VERSION "HNNBNNNYNNNNNNNNNNNNNNNNNNNNNNNNNNNNNNNNNN/4/%%%/4/'%**4NNN///"

NS_ :

BS_:

BU_: BAP_Tester FASFrontradar ICAS1_X_Gateway MFK MFK120 MIK MRR2023 NR_1 NR_2

BO_ 2331595789 NR_FR_Object_09_10: 64 NR_2
 SG_ NR_FR_Object_09_10_CRC : 0|8@1+ (1,0) [0|255] ""  ICAS1_X_Gateway,MRR2023
 SG_ NR_FR_Object_09_10_BZ : 8|4@1+ (1,0) [0|15] ""  ICAS1_X_Gateway,MRR2023
 SG_ NR_FR_Object_09_10_BlockID_02 : 12|4@1+ (1,0) [0|15] "Unit_None"  ICAS1_X_Gateway,MRR2023
 SG_ NR_FR_Object_09_ID : 16|8@1+ (1,0) [1|254] "Unit_None"  ICAS1_X_Gateway,MRR2023
 SG_ NR_FR_Object_09_ReferencePoint : 24|4@1+ (1.0,0.0) [0.0|15] ""  ICAS1_X_Gateway,MRR2023
 SG_ NR_FR_Object_09_PosX : 28|14@1+ (0.03125,-200) [-200.00000|311.93750] "Unit_Meter"  ICAS1_X_Gateway,MRR2023
 SG_ NR_FR_Object_09_PosXSD : 42|8@1+ (0.03125,0) [0.00000|7.93750] "Unit_Meter"  ICAS1_X_Gateway,MRR2023
 SG_ NR_FR_Object_09_PosY : 50|13@1+ (0.03125,-128) [-128.00000|127.93750] "Unit_Meter"  ICAS1_X_Gateway,MRR2023
 SG_ NR_FR_Object_09_PosYSD : 63|8@1+ (0.03125,0) [0.00000|7.93750] "Unit_Meter"  ICAS1_X_Gateway,MRR2023
 SG_ NR_FR_Object_09_vAbsX : 71|12@1+ (0.0625,-128) [-128.0000|127.8750] "Unit_MeterPerSecon"  ICAS1_X_Gateway,MRR2023
 SG_ NR_FR_Object_09_vAbsXSD : 83|6@1+ (0.0625,0) [0.0000|3.8750] "Unit_MeterPerSecon"  ICAS1_X_Gateway,MRR2023
 SG_ NR_FR_Object_09_vAbsY : 89|12@1+ (0.0625,-128) [-128.0000|127.8750] "Unit_MeterPerSecon"  ICAS1_X_Gateway,MRR2023
 SG_ NR_FR_Object_09_vAbsYSD : 101|6@1+ (0.0625,0) [0.0000|3.8750] "Unit_MeterPerSecon"  ICAS1_X_Gateway,MRR2023
 SG_ NR_FR_Object_09_aAbsX : 107|9@1+ (0.0625,-16) [-16.0000|15.8750] "Unit_MeterPerSeconSquar"  ICAS1_X_Gateway,MRR2023
 SG_ NR_FR_Object_09_aAbsXSD : 116|6@1+ (0.0625,0) [0.0000|3.8750] "Unit_MeterPerSeconSquar"  ICAS1_X_Gateway,MRR2023
 SG_ NR_FR_Object_09_aAbsY : 122|9@1+ (0.0625,-16) [-16.0000|15.8750] "Unit_MeterPerSeconSquar"  ICAS1_X_Gateway,MRR2023
 SG_ NR_FR_Object_09_aAbsYSD : 131|6@1+ (0.0625,0) [0.0000|3.8750] "Unit_MeterPerSeconSquar"  ICAS1_X_Gateway,MRR2023
 SG_ NR_FR_Object_09_DynamicState : 137|2@1+ (1.0,0.0) [0.0|3] ""  ICAS1_X_Gateway,MRR2023
 SG_ NR_FR_Object_09_YawAngle : 139|12@1+ (0.001953125,-4) [-4.000000000|3.996093750] "Unit_Radia"  ICAS1_X_Gateway,MRR2023
 SG_ NR_FR_Object_09_YawAngleSD : 151|9@1+ (0.001953125,0) [0E-9|0.996093750] "Unit_Radia"  ICAS1_X_Gateway,MRR2023
 SG_ NR_FR_Object_09_Width : 160|8@1+ (0.03125,0) [0.00000|7.93750] "Unit_Meter"  ICAS1_X_Gateway,MRR2023
 SG_ NR_FR_Object_09_WidthSD : 168|7@1+ (0.03125,0) [0.00000|3.93750] "Unit_Meter"  ICAS1_X_Gateway,MRR2023
 SG_ NR_FR_Object_09_Length : 175|10@1+ (0.03125,0) [0.00000|31.93750] "Unit_Meter"  ICAS1_X_Gateway,MRR2023
 SG_ NR_FR_Object_09_LengthSD : 185|7@1+ (0.03125,0) [0.00000|3.93750] "Unit_Meter"  ICAS1_X_Gateway,MRR2023
 SG_ NR_FR_Object_09_Class : 192|4@1+ (1.0,0.0) [0.0|15] ""  ICAS1_X_Gateway,MRR2023
 SG_ NR_FR_Object_09_ClassPlausib : 196|4@1+ (0.0714285714,0) [0E-10|0.9999999996] "Unit_None"  ICAS1_X_Gateway,MRR2023
 SG_ NR_FR_Object_09_ExistProb : 200|7@1+ (0.0078125,0.015625) [0.0156250|1.0000000] "Unit_None"  ICAS1_X_Gateway,MRR2023
 SG_ NR_FR_Object_09_Age : 207|7@1+ (1,0) [0|126] "Unit_None"  ICAS1_X_Gateway,MRR2023
 SG_ NR_FR_Object_09_YawRateAbs : 214|12@1+ (0.001953125,-4) [-4.000000000|3.996093750] "Unit_RadiaPerSecon"  ICAS1_X_Gateway,MRR2023
 SG_ NR_FR_Object_09_YawRateAbsSD : 226|6@1+ (0.003906,0) [0.000000|0.242172] "Unit_RadiaPerSecon"  ICAS1_X_Gateway,MRR2023
 SG_ NR_FR_Object_09_MeasurementState : 232|1@1+ (1.0,0.0) [0.0|1] ""  ICAS1_X_Gateway,MRR2023
 SG_ NR_FR_Object_10_ID : 233|8@1+ (1,0) [1|254] "Unit_None"  ICAS1_X_Gateway,MRR2023
 SG_ NR_FR_Object_10_ReferencePoint : 241|4@1+ (1.0,0.0) [0.0|15] ""  ICAS1_X_Gateway,MRR2023
 SG_ NR_FR_Object_10_PosX : 245|14@1+ (0.03125,-200) [-200.00000|311.93750] "Unit_Meter"  ICAS1_X_Gateway,MRR2023
 SG_ NR_FR_Object_10_PosXSD : 259|8@1+ (0.03125,0) [0.00000|7.93750] "Unit_Meter"  ICAS1_X_Gateway,MRR2023
 SG_ NR_FR_Object_10_PosY : 267|13@1+ (0.03125,-128) [-128.00000|127.93750] "Unit_Meter"  ICAS1_X_Gateway,MRR2023
 SG_ NR_FR_Object_10_PosYSD : 280|8@1+ (0.03125,0) [0.00000|7.93750] "Unit_Meter"  ICAS1_X_Gateway,MRR2023
 SG_ NR_FR_Object_10_vAbsX : 288|12@1+ (0.0625,-128) [-128.0000|127.8750] "Unit_MeterPerSecon"  ICAS1_X_Gateway,MRR2023
 SG_ NR_FR_Object_10_vAbsXSD : 300|6@1+ (0.0625,0) [0.0000|3.8750] "Unit_MeterPerSecon"  ICAS1_X_Gateway,MRR2023
 SG_ NR_FR_Object_10_vAbsY : 306|12@1+ (0.0625,-128) [-128.0000|127.8750] "Unit_MeterPerSecon"  ICAS1_X_Gateway,MRR2023
 SG_ NR_FR_Object_10_vAbsYSD : 318|6@1+ (0.0625,0) [0.0000|3.8750] "Unit_MeterPerSecon"  ICAS1_X_Gateway,MRR2023
 SG_ NR_FR_Object_10_aAbsX : 324|9@1+ (0.0625,-16) [-16.0000|15.8750] "Unit_MeterPerSeconSquar"  ICAS1_X_Gateway,MRR2023
 SG_ NR_FR_Object_10_aAbsXSD : 333|6@1+ (0.0625,0) [0.0000|3.8750] "Unit_MeterPerSeconSquar"  ICAS1_X_Gateway,MRR2023
 SG_ NR_FR_Object_10_aAbsY : 339|9@1+ (0.0625,-16) [-16.0000|15.8750] "Unit_MeterPerSeconSquar"  ICAS1_X_Gateway,MRR2023
 SG_ NR_FR_Object_10_aAbsYSD : 348|6@1+ (0.0625,0) [0.0000|3.8750] "Unit_MeterPerSeconSquar"  ICAS1_X_Gateway,MRR2023
 SG_ NR_FR_Object_10_DynamicState : 354|2@1+ (1.0,0.0) [0.0|3] ""  ICAS1_X_Gateway,MRR2023
 SG_ NR_FR_Object_10_YawAngle : 356|12@1+ (0.001953125,-4) [-4.000000000|3.996093750] "Unit_Radia"  ICAS1_X_Gateway,MRR2023
 SG_ NR_FR_Object_10_YawAngleSD : 368|9@1+ (0.001953125,0) [0E-9|0.996093750] "Unit_Radia"  ICAS1_X_Gateway,MRR2023
 SG_ NR_FR_Object_10_Width : 377|8@1+ (0.03125,0) [0.00000|7.93750] "Unit_Meter"  ICAS1_X_Gateway,MRR2023
 SG_ NR_FR_Object_10_WidthSD : 385|7@1+ (0.03125,0) [0.00000|3.93750] "Unit_Meter"  ICAS1_X_Gateway,MRR2023
 SG_ NR_FR_Object_10_Length : 392|10@1+ (0.03125,0) [0.00000|31.93750] "Unit_Meter"  ICAS1_X_Gateway,MRR2023
 SG_ NR_FR_Object_10_LengthSD : 402|7@1+ (0.03125,0) [0.00000|3.93750] "Unit_Meter"  ICAS1_X_Gateway,MRR2023
 SG_ NR_FR_Object_10_Class : 409|4@1+ (1.0,0.0) [0.0|15] ""  ICAS1_X_Gateway,MRR2023
 SG_ NR_FR_Object_10_ClassPlausib : 413|4@1+ (0.0714285714,0) [0E-10|0.9999999996] "Unit_None"  ICAS1_X_Gateway,MRR2023
 SG_ NR_FR_Object_10_ExistProb : 417|7@1+ (0.0078125,0.015625) [0.0156250|1.0000000] "Unit_None"  ICAS1_X_Gateway,MRR2023
 SG_ NR_FR_Object_10_Age : 424|7@1+ (1,0) [0|126] "Unit_None"  ICAS1_X_Gateway,MRR2023
 SG_ NR_FR_Object_10_YawRateAbs : 431|12@1+ (0.001953125,-4) [-4.000000000|3.996093750] "Unit_RadiaPerSecon"  ICAS1_X_Gateway,MRR2023
 SG_ NR_FR_Object_10_YawRateAbsSD : 443|6@1+ (0.003906,0) [0.000000|0.242172] "Unit_RadiaPerSecon"  ICAS1_X_Gateway,MRR2023
 SG_ NR_FR_Object_10_MeasurementState : 449|1@1+ (1.0,0.0) [0.0|1] ""  ICAS1_X_Gateway,MRR2023
 SG_ SOK_NR_FR_Object_09_10_Signatur : 480|32@1+ (1,0) [0|4294967295] ""  ICAS1_X_Gateway

BO_ 2589284097 NR_FR_SensorHeader: 24 NR_2
 SG_ NR_FR_HW_Version : 12|32@1+ (1,0) [0|4294967294] "Unit_None"  ICAS1_X_Gateway,MRR2023
 SG_ NR_FR_SW_Version : 44|32@1+ (1,0) [0|4294967295] "Unit_None"  ICAS1_X_Gateway,MRR2023
 SG_ NR_FR_SerialNumber : 76|32@1+ (1,0) [0|4294967295] "Unit_None"  ICAS1_X_Gateway,MRR2023
 SG_ DS_FR_StructureVersion_1 : 108|32@1+ (1,0) [0|4294967295] "Unit_None"  ICAS1_X_Gateway
 SG_ DS_FR_StructureVersion_2 : 140|32@1+ (1,0) [0|4294967295] "Unit_None"  ICAS1_X_Gateway

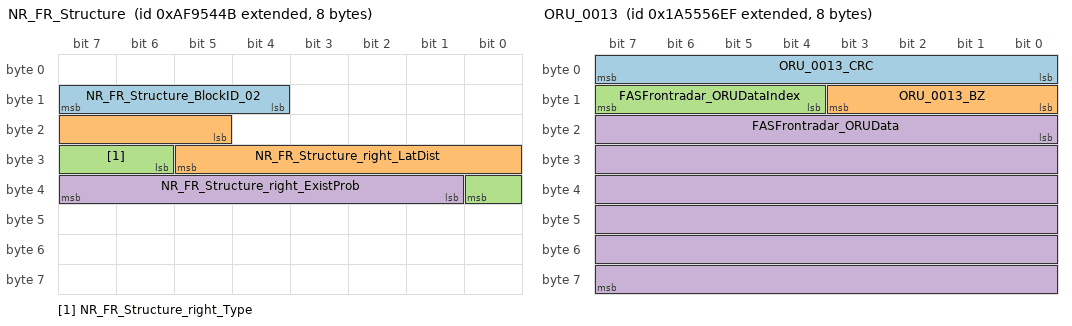
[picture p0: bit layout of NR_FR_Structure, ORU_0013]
BO_ 2331595851 NR_FR_Structure: 8 NR_2
 SG_ NR_FR_Structure_BlockID_02 : 12|4@1+ (1,0) [0|15] "Unit_None"  ICAS1_X_Gateway,MRR2023
 SG_ NR_FR_Structure_right_LatDist : 21|9@1+ (0.03125,0) [0.00000|15.93750] "Unit_Meter"  ICAS1_X_Gateway,MRR2023
 SG_ NR_FR_Structure_right_Type : 30|3@1+ (1.0,0.0) [0.0|7] ""  ICAS1_X_Gateway,MRR2023
 SG_ NR_FR_Structure_right_ExistProb : 33|7@1+ (0.0078125,0.015625) [0.0156250|1.0000000] "Unit_None"  ICAS1_X_Gateway,MRR2023

BO_ 2264486984 NR_FR_SyncReady: 16 NR_2
 SG_ NR_FR_SyncReadyVersion : 12|8@1+ (1,0) [0|255] "Unit_None"  ICAS1_X_Gateway,MRR2023
 SG_ NR_FR_EarliestStartTime : 20|32@1+ (1,0) [0|4294967295] "Unit_None"  ICAS1_X_Gateway,MRR2023
 SG_ NR_FR_RequestedModulation : 52|4@1+ (1,0) [0|15] "Unit_None"  ICAS1_X_Gateway,MRR2023
 SG_ NR_FR_InteferenceInfo : 56|16@1+ (1,0) [0|65535] "Unit_None"  ICAS1_X_Gateway,MRR2023
 SG_ NR_FR_SyncCycleCount : 74|32@1+ (1,0) [0|4294967295] "Unit_None"  ICAS1_X_Gateway,MRR2023
 SG_ NR_FR_LatestSyncCounter : 106|4@1+ (1,0) [0|15] "Unit_None"  ICAS1_X_Gateway,MRR2023

BO_ 2621440599 OBDC_ACC_Req_FD: 64 ICAS1_X_Gateway
 SG_ OBDC_ACC_Req_FD_Data : 0|512@1+ (1.0,0.0) [0.0|13407807929942597099574024998205846127479365820592393377723561443721764030073546976801874298166903427690031858186486050853753882811946569946433649006084095] ""  FASFrontradar,MRR2023

BO_ 2621571671 OBDC_ACC_Resp_FD: 64 FASFrontradar
 SG_ OBDC_ACC_Resp_FD_Data : 0|512@1+ (1.0,0.0) [0.0|13407807929942597099574024998205846127479365820592393377723561443721764030073546976801874298166903427690031858186486050853753882811946569946433649006084095] ""  ICAS1_X_Gateway

BO_ 2621506048 OBDC_Funktionaler_Req_All_FD: 64 ICAS1_X_Gateway
 SG_ OBDC_Funktion_Req_All_FD_Data : 0|512@1+ (1.0,0.0) [0.0|13407807929942597099574024998205846127479365820592393377723561443721764030073546976801874298166903427690031858186486050853753882811946569946433649006084095] ""  FASFrontradar,MFK,MRR2023,NR_1,NR_2

BO_ 2621440591 OBDC_Kamera_Req_FD: 64 ICAS1_X_Gateway
 SG_ OBDC_Kamera_Req_FD_Data : 0|512@1+ (1.0,0.0) [0.0|13407807929942597099574024998205846127479365820592393377723561443721764030073546976801874298166903427690031858186486050853753882811946569946433649006084095] ""  MFK

BO_ 2621571663 OBDC_Kamera_Resp_FD: 64 MFK
 SG_ OBDC_Kamera_Resp_FD_Data : 0|512@1+ (1.0,0.0) [0.0|13407807929942597099574024998205846127479365820592393377723561443721764030073546976801874298166903427690031858186486050853753882811946569946433649006084095] ""  ICAS1_X_Gateway

BO_ 2621440699 OBDC_NR_01_Req_FD: 64 ICAS1_X_Gateway
 SG_ OBDC_NR_01_Req_FD_Data : 0|512@1+ (1.0,0.0) [0.0|13407807929942597099574024998205846127479365820592393377723561443721764030073546976801874298166903427690031858186486050853753882811946569946433649006084095] ""  NR_1

BO_ 2621571771 OBDC_NR_01_Resp_FD: 64 NR_1
 SG_ OBDC_NR_01_Resp_FD_Data : 0|512@1+ (1.0,0.0) [0.0|13407807929942597099574024998205846127479365820592393377723561443721764030073546976801874298166903427690031858186486050853753882811946569946433649006084095] ""  ICAS1_X_Gateway

BO_ 2621440700 OBDC_NR_02_Req_FD: 64 ICAS1_X_Gateway
 SG_ OBDC_NR_02_Req_FD_Data : 0|512@1+ (1.0,0.0) [0.0|13407807929942597099574024998205846127479365820592393377723561443721764030073546976801874298166903427690031858186486050853753882811946569946433649006084095] ""  NR_2

BO_ 2621571772 OBDC_NR_02_Resp_FD: 64 NR_2
 SG_ OBDC_NR_02_Resp_FD_Data : 0|512@1+ (1.0,0.0) [0.0|13407807929942597099574024998205846127479365820592393377723561443721764030073546976801874298166903427690031858186486050853753882811946569946433649006084095] ""  ICAS1_X_Gateway

BO_ 2564502513 OBDx_allOBD_Req: 8 ICAS1_X_Gateway
 SG_ OBDx_allOBD_Req_Data : 0|64@1+ (1.0,0.0) [0.0|18446744073709551615] ""  Vector__XXX

BO_ 2589284079 ORU_0013: 8 FASFrontradar
 SG_ ORU_0013_CRC : 0|8@1+ (1,0) [0|255] ""  ICAS1_X_Gateway
 SG_ ORU_0013_BZ : 8|4@1+ (1,0) [0|15] ""  ICAS1_X_Gateway
 SG_ FASFrontradar_ORUDataIndex : 12|4@1+ (1,0) [0|15] ""  ICAS1_X_Gateway
 SG_ FASFrontradar_ORUData : 16|48@1+ (1,0) [0|281474976710655] ""  ICAS1_X_Gateway

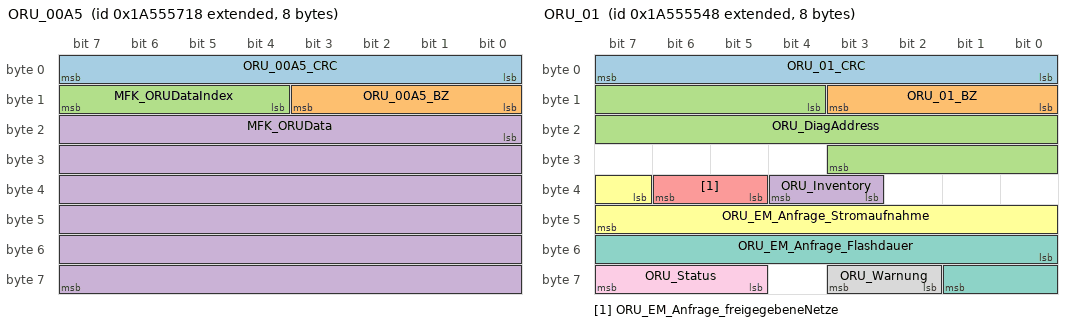
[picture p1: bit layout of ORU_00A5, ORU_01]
BO_ 2589284120 ORU_00A5: 8 MFK
 SG_ ORU_00A5_CRC : 0|8@1+ (1,0) [0|255] ""  ICAS1_X_Gateway
 SG_ ORU_00A5_BZ : 8|4@1+ (1,0) [0|15] ""  ICAS1_X_Gateway
 SG_ MFK_ORUDataIndex : 12|4@1+ (1.0,0.0) [0.0|15] ""  ICAS1_X_Gateway
 SG_ MFK_ORUData : 16|48@1+ (1,0) [0|281474976710655] ""  ICAS1_X_Gateway

BO_ 2589283656 ORU_01: 8 ICAS1_X_Gateway
 SG_ ORU_01_CRC : 0|8@1+ (1,0) [0|255] ""  MRR2023
 SG_ ORU_01_BZ : 8|4@1+ (1,0) [0|15] ""  MRR2023
 SG_ ORU_DiagAddress : 12|16@1+ (1,0) [0|65535] ""  Vector__XXX
 SG_ ORU_Inventory : 35|2@1+ (1.0,0.0) [0.0|3] ""  Vector__XXX
 SG_ ORU_EM_Anfrage_freigegebeneNetze : 37|2@1+ (1.0,0.0) [0.0|3] ""  Vector__XXX
 SG_ ORU_EM_Anfrage_Stromaufnahme : 39|9@1+ (0.1,0) [0.0|51.1] "Unit_Amper"  Vector__XXX
 SG_ ORU_EM_Anfrage_Flashdauer : 48|10@1+ (10,0) [0|10230] "Unit_Secon"  Vector__XXX
 SG_ ORU_Warnung : 58|2@1+ (1.0,0.0) [0.0|3] ""  MFK,MFK120
 SG_ ORU_Status : 61|3@1+ (1.0,0.0) [0.0|7] ""  FASFrontradar,MFK,MFK120,MIK,MRR2023

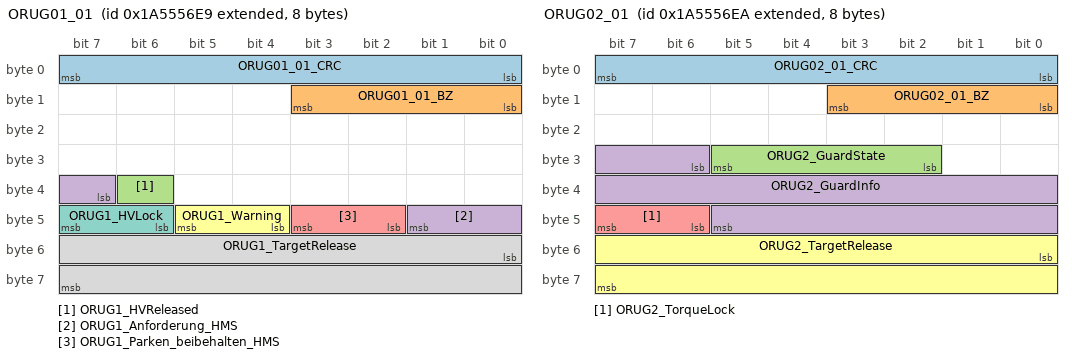
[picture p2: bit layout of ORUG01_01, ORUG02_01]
BO_ 2589284073 ORUG01_01: 8 ICAS1_X_Gateway
 SG_ ORUG01_01_CRC : 0|8@1+ (1,0) [0|255] ""  FASFrontradar,MFK,MFK120
 SG_ ORUG01_01_BZ : 8|4@1+ (1,0) [0|15] ""  FASFrontradar,MFK,MFK120
 SG_ ORUG1_HVReleased : 38|1@1+ (1.0,0.0) [0.0|1] ""  Vector__XXX
 SG_ ORUG1_Anforderung_HMS : 39|3@1+ (1.0,0.0) [0.0|7] ""  Vector__XXX
 SG_ ORUG1_Parken_beibehalten_HMS : 42|2@1+ (1.0,0.0) [0.0|3] ""  Vector__XXX
 SG_ ORUG1_Warning : 44|2@1+ (1.0,0.0) [0.0|3] ""  Vector__XXX
 SG_ ORUG1_HVLock : 46|2@1+ (1.0,0.0) [0.0|3] ""  Vector__XXX
 SG_ ORUG1_TargetRelease : 48|16@1+ (1,0) [0|65535] ""  FASFrontradar,MFK,MFK120,MRR2023

BO_ 2589284074 ORUG02_01: 8 ICAS1_X_Gateway
 SG_ ORUG02_01_CRC : 0|8@1+ (1,0) [0|255] ""  FASFrontradar,MFK,MFK120
 SG_ ORUG02_01_BZ : 8|4@1+ (1,0) [0|15] ""  FASFrontradar,MFK,MFK120
 SG_ ORUG2_GuardState : 26|4@1+ (1.0,0.0) [0.0|15] ""  Vector__XXX
 SG_ ORUG2_GuardInfo : 30|16@1+ (1.0,0.0) [0.0|65535] ""  Vector__XXX
 SG_ ORUG2_TorqueLock : 46|2@1+ (1.0,0.0) [0.0|3] ""  Vector__XXX
 SG_ ORUG2_TargetRelease : 48|16@1+ (1,0) [0|65535] ""  FASFrontradar,MFK,MFK120,MRR2023

BO_ 525 PaCo_01: 16 ICAS1_X_Gateway
 SG_ PaCo_01_Sendestatus : 12|1@1+ (1.0,0.0) [0.0|1] ""  MFK,MFK120
 SG_ PaCo_APS_TargetState : 13|3@1+ (1.0,0.0) [0.0|7] ""  Vector__XXX
 SG_ PaCo_APSOPS_DetectionFront : 16|1@1+ (1.0,0.0) [0.0|1] ""  Vector__XXX
 SG_ PaCo_APSOPS_DetectionRear : 17|1@1+ (1.0,0.0) [0.0|1] ""  Vector__XXX
 SG_ PaCo_APSOPS_LED : 18|2@1+ (1.0,0.0) [0.0|3] ""  Vector__XXX
 SG_ PaCo_OPS_TargetState : 20|3@1+ (1.0,0.0) [0.0|7] ""  Vector__XXX
 SG_ PaCo_OPS_DrivingTube : 23|1@1+ (1.0,0.0) [0.0|1] ""  Vector__XXX
 SG_ PaCo_PLAIPA_InterventionStart : 24|1@1+ (1.0,0.0) [0.0|1] ""  Vector__XXX
 SG_ PaCo_PLAIPA_PLE : 25|1@1+ (1.0,0.0) [0.0|1] ""  Vector__XXX
 SG_ PaCo_PLAIPA_LED : 26|2@1+ (1.0,0.0) [0.0|3] ""  Vector__XXX
 SG_ PaCo_PLAIPA_TargetState : 28|4@1+ (1.0,0.0) [0.0|15] ""  MFK,MFK120
 SG_ PaCo_PLAIPA_SwitchParkSlot : 32|1@1+ (1.0,0.0) [0.0|1] ""  Vector__XXX
 SG_ PaCo_RBFMA_InterventionStrategy : 33|3@1+ (1.0,0.0) [0.0|7] ""  Vector__XXX
 SG_ PaCo_VPS_TargetView : 36|4@1+ (1.0,0.0) [0.0|15] ""  Vector__XXX
 SG_ PaCo_VPS_TargetMode : 40|4@1+ (1.0,0.0) [0.0|15] ""  Vector__XXX
 SG_ PaCo_VPS_LED : 44|2@1+ (1.0,0.0) [0.0|3] ""  Vector__XXX
 SG_ PaCo_VPS_TargetState : 46|2@1+ (1.0,0.0) [0.0|3] ""  Vector__XXX
 SG_ PaCo_VPS_TargetBirdview : 48|3@1+ (1.0,0.0) [0.0|7] ""  Vector__XXX
 SG_ PaCo_VPS_DarkenVideo : 51|1@1+ (1.0,0.0) [0.0|1] ""  Vector__XXX
 SG_ PaCo_VPS_PLE : 52|1@1+ (1.0,0.0) [0.0|1] ""  Vector__XXX
 SG_ PaCo_ARA_TargetState : 53|1@1+ (1.0,0.0) [0.0|1] ""  Vector__XXX
 SG_ PaCo_RCTA_InterventionStrategy : 54|2@1+ (1.0,0.0) [0.0|3] ""  Vector__XXX
 SG_ PaCo_MainState : 56|3@1+ (1.0,0.0) [0.0|7] ""  MFK,MFK120
 SG_ PaCo_RCTA_Warning : 59|3@1+ (1.0,0.0) [0.0|7] ""  Vector__XXX
 SG_ PaCo_APS_AudioLowering : 62|1@1+ (1.0,0.0) [0.0|1] ""  Vector__XXX
 SG_ PaCo_VPS_TargetRVCscreen : 63|3@1+ (1.0,0.0) [0.0|7] ""  Vector__XXX
 SG_ PaCo_AAA_Intervention : 66|2@1+ (1.0,0.0) [0.0|3] ""  Vector__XXX
 SG_ PaCo_AAA_TargetState : 68|2@1+ (1.0,0.0) [0.0|3] ""  Vector__XXX
 SG_ PaCo_TPA_TargetState : 70|4@1+ (1.0,0.0) [0.0|15] ""  MFK,MFK120
 SG_ PaCo_DiETa_LED : 74|2@1+ (1.0,0.0) [0.0|3] ""  Vector__XXX
 SG_ PaCo_RA_InterventionStart : 80|1@1+ (1.0,0.0) [0.0|1] ""  Vector__XXX
 SG_ PaCo_VPS_TargetCarOverlay : 94|2@1+ (1.0,0.0) [0.0|3] ""  Vector__XXX
 SG_ PaCo_VPS_TargetBowl : 96|5@1+ (1.0,0.0) [0.0|31] ""  Vector__XXX
 SG_ PaCo_VPS_TargetGraphicOverlay : 101|4@1+ (1.0,0.0) [0.0|15] ""  Vector__XXX
 SG_ PaCo_RA_Targetstate : 108|4@1+ (1.0,0.0) [0.0|15] ""  Vector__XXX
 SG_ PaCo_AEBPR_InterventionStrategy : 118|1@1+ (1.0,0.0) [0.0|1] ""  Vector__XXX
 SG_ PaCo_AEBPR_ImplementationRBFMA : 120|1@1+ (1.0,0.0) [0.0|1] ""  Vector__XXX
 SG_ PaCo_RBFMA_ImplementationAEBPR : 121|1@1+ (1.0,0.0) [0.0|1] ""  Vector__XXX
 SG_ PaCo_ARA_InterventionStart : 124|1@1+ (1.0,0.0) [0.0|1] ""  Vector__XXX

BO_ 518 Parken_01: 24 ICAS1_X_Gateway
 SG_ Parken_01_CRC : 0|8@1+ (1,0) [0|255] ""  Vector__XXX
 SG_ Parken_01_BZ : 8|4@1+ (1,0) [0|15] ""  Vector__XXX
 SG_ Parken_BKD_Anf : 12|4@1+ (0.1,0) [0.0|1.3] "Unit_Secon"  Vector__XXX
 SG_ Parken_Verz_Anf : 16|7@1+ (0.1,-12.6) [-12.6|-0.1] "Unit_MeterPerSeconSquar"  Vector__XXX
 SG_ Parken_Prefill_Anf : 23|1@1+ (1.0,0.0) [0.0|1] ""  Vector__XXX
 SG_ Parken_Warnruck_Anf : 24|2@1+ (1.0,0.0) [0.0|3] ""  Vector__XXX
 SG_ Parken_Verz_Anf_ASIL : 26|2@1+ (1.0,0.0) [0.0|3] ""  Vector__XXX
 SG_ Parken_Warnruckeln_Anf : 28|2@1+ (1.0,0.0) [0.0|3] ""  Vector__XXX
 SG_ Parken_beibehalten : 30|2@1+ (1.0,0.0) [0.0|3] ""  Vector__XXX
 SG_ Parken_Anforderung_HMS : 32|3@1+ (1.0,0.0) [0.0|7] ""  Vector__XXX
 SG_ Parken_Fahrbereitschaft_Anf : 35|1@1+ (1.0,0.0) [0.0|1] ""  Vector__XXX
 SG_ Parken_Motorlauf_Anf : 36|2@1+ (1.0,0.0) [0.0|3] ""  Vector__XXX
 SG_ IPA_TPA_ausgerichtetes_Parken : 38|2@1+ (1.0,0.0) [0.0|3] ""  MFK120
 SG_ Parken_Notstopp_Anf : 40|2@1+ (1.0,0.0) [0.0|3] ""  Vector__XXX
 SG_ Parken_Anhalteweg_Anf : 42|10@1+ (0.01,0) [0.00|10.21] "Unit_Meter"  Vector__XXX
 SG_ Parken_aktives_System : 52|4@1+ (1.0,0.0) [0.0|15] ""  Vector__XXX
 SG_ Parken_max_Beschleunigung : 56|7@1+ (0.1,-6) [-5.9|6.1] "Unit_MeterPerSeconSquar"  Vector__XXX
 SG_ Parken_Blinker_li_Anf : 63|1@1+ (1.0,0.0) [0.0|1] ""  Vector__XXX
 SG_ Parken_Sollbeschleunigung : 118|9@1+ (0.01,-4.11) [-4.10|1.00] "Unit_MeterPerSeconSquar"  Vector__XXX
 SG_ Parken_Blinker_re_Anf : 127|1@1+ (1.0,0.0) [0.0|1] ""  Vector__XXX
 SG_ Parken_Status_IPA_TSK : 128|4@1+ (1.0,0.0) [0.0|15] ""  Vector__XXX
 SG_ Parken_erhoehtes_Moment : 132|4@1+ (1.0,0.0) [0.0|15] ""  Vector__XXX
 SG_ Parken_max_Geschwindigkeit : 136|8@1+ (0.1,0) [0.1|25.0] "Unit_KiloMeterPerHour"  Vector__XXX
 SG_ Parken_Soll_Anhalteweg_Anf : 144|10@1+ (0.01,0) [0.00|10.21] "Unit_Meter"  Vector__XXX
 SG_ Parken_Fahrstufenwunsch : 154|3@1+ (1.0,0.0) [0.0|7] ""  Vector__XXX
 SG_ Parken_Schleichfahrt_Anf : 157|1@1+ (1.0,0.0) [0.0|1] ""  Vector__XXX
 SG_ Parken_Bordstein_Winkel : 158|7@1+ (1,-1) [0|90] "Unit_DegreOfArc"  Vector__XXX
 SG_ IPA_TPA_Remote : 176|2@1+ (1.0,0.0) [0.0|3] ""  MFK,MFK120
 SG_ IPA_TPA_Remote_Anf : 178|2@1+ (1.0,0.0) [0.0|3] ""  MFK,MFK120
 SG_ IPA_TPA_Fehler : 180|4@1+ (1.0,0.0) [0.0|15] ""  MFK,MFK120
 SG_ IPA_TPA_Abbruch : 184|4@1+ (1.0,0.0) [0.0|15] ""  MFK,MFK120
 SG_ IPA_TPA_Status : 188|4@1+ (1.0,0.0) [0.0|15] ""  MFK,MFK120

BO_ 796 PCS_Li_01: 32 NR_1
 SG_ PCS_Li_MessZeitpunkt : 12|13@1+ (0.001,0) [0.000|8.190] "Unit_Secon"  ICAS1_X_Gateway
 SG_ PCS_Li_CW : 28|7@1+ (1,0) [0|100] "Unit_PerCent"  ICAS1_X_Gateway
 SG_ PCS_Li_CS : 42|7@1+ (1,0) [0|100] "Unit_PerCent"  ICAS1_X_Gateway
 SG_ PCS_Li_TTC : 56|10@1+ (0.001,0) [0.000|1.000] "Unit_Secon"  ICAS1_X_Gateway
 SG_ PCS_Li_BlockID : 73|4@1+ (1,0) [0|15] "Unit_None"  ICAS1_X_Gateway
 SG_ PCS_Li_Status : 77|4@1+ (1.0,0.0) [0.0|15] ""  ICAS1_X_Gateway

BO_ 797 PCS_Re_01: 32 NR_2
 SG_ PCS_Re_MessZeitpunkt : 12|13@1+ (0.001,0) [0.000|8.190] "Unit_Secon"  ICAS1_X_Gateway
 SG_ PCS_Re_CW : 28|7@1+ (1,0) [0|100] "Unit_PerCent"  ICAS1_X_Gateway
 SG_ PCS_Re_CS : 42|7@1+ (1,0) [0|100] "Unit_PerCent"  ICAS1_X_Gateway
 SG_ PCS_Re_TTC : 56|10@1+ (0.001,0) [0.000|1.000] "Unit_Secon"  ICAS1_X_Gateway
 SG_ PCS_Re_BlockID : 73|4@1+ (1,0) [0|15] "Unit_None"  ICAS1_X_Gateway
 SG_ PCS_Re_Status : 77|4@1+ (1.0,0.0) [0.0|15] ""  ICAS1_X_Gateway

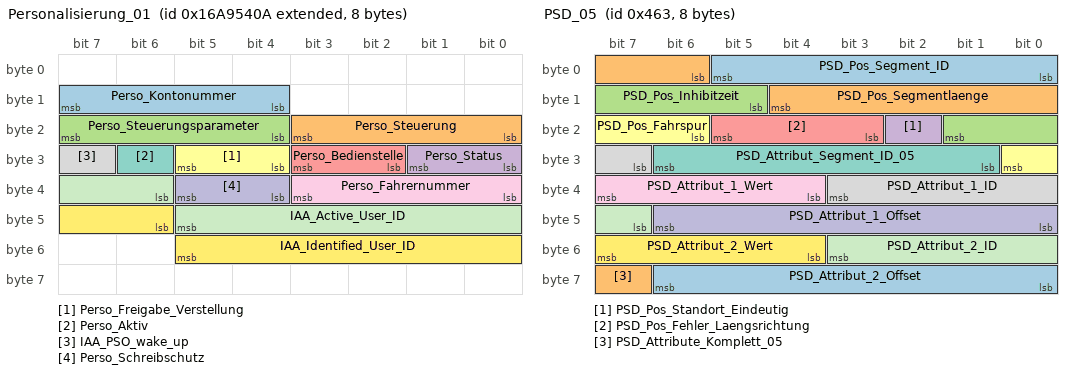
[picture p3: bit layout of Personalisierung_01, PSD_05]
BO_ 2527679498 Personalisierung_01: 8 ICAS1_X_Gateway
 SG_ Perso_Kontonummer : 12|4@1+ (1.0,0.0) [0.0|15] ""  FASFrontradar,MFK,MFK120,MRR2023
 SG_ Perso_Steuerung : 16|4@1+ (1.0,0.0) [0.0|15] ""  FASFrontradar,MFK,MFK120,MRR2023
 SG_ Perso_Steuerungsparameter : 20|4@1+ (1.0,0.0) [0.0|15] ""  FASFrontradar,MFK,MFK120,MRR2023
 SG_ Perso_Status : 24|2@1+ (1.0,0.0) [0.0|3] ""  FASFrontradar,MFK,MFK120,MRR2023
 SG_ Perso_Bedienstelle : 26|2@1+ (1.0,0.0) [0.0|3] ""  FASFrontradar,MFK,MRR2023
 SG_ Perso_Freigabe_Verstellung : 28|2@1+ (1.0,0.0) [0.0|3] ""  FASFrontradar,MFK,MRR2023
 SG_ Perso_Aktiv : 30|1@1+ (1.0,0.0) [0.0|1] ""  FASFrontradar,MFK,MFK120,MRR2023
 SG_ IAA_PSO_wake_up : 31|1@1+ (1.0,0.0) [0.0|1] ""  Vector__XXX
 SG_ Perso_Fahrernummer : 32|4@1+ (1.0,0.0) [0.0|15] ""  FASFrontradar,MFK,MFK120,MRR2023
 SG_ Perso_Schreibschutz : 36|2@1+ (1.0,0.0) [0.0|3] ""  FASFrontradar,MFK,MRR2023
 SG_ IAA_Active_User_ID : 38|8@1+ (1,0) [0|255] "Unit_None"  Vector__XXX
 SG_ IAA_Identified_User_ID : 46|8@1+ (1,0) [0|255] "Unit_None"  Vector__XXX

BO_ 1031 PLA_04: 8 ICAS1_X_Gateway
 SG_ PLA_04_CRC : 0|8@1+ (1,0) [0|255] ""  Vector__XXX
 SG_ PLA_04_BZ : 8|4@1+ (1,0) [0|15] ""  Vector__XXX
 SG_ PLAIPA_PaCo_ParkingSlots_02 : 12|4@1+ (1.0,0.0) [0.0|15] ""  Vector__XXX
 SG_ RA_PaCo_USSensorStatus : 16|3@1+ (1.0,0.0) [0.0|7] ""  Vector__XXX
 SG_ RA_PaCo_MainState : 19|3@1+ (1.0,0.0) [0.0|7] ""  Vector__XXX
 SG_ RA_PaCo_FunctionState : 22|4@1+ (1.0,0.0) [0.0|15] ""  Vector__XXX
 SG_ RA_PaCo_InterventionPossible : 26|3@1+ (1.0,0.0) [0.0|7] ""  Vector__XXX
 SG_ RA_PaCo_UnavailableReason : 29|4@1+ (1.0,0.0) [0.0|15] ""  Vector__XXX
 SG_ PLAIPA_PaCo_RemoteActivatable : 33|3@1+ (1.0,0.0) [0.0|7] ""  Vector__XXX
 SG_ PLAIPA_PaCo_GarageActivatable : 36|1@1+ (1.0,0.0) [0.0|1] ""  Vector__XXX
 SG_ RPA_Anf_Sonder_Funktion_Status : 37|3@1+ (1.0,0.0) [0.0|7] ""  Vector__XXX
 SG_ RPA_Anf_Sonder_Klemme_15 : 40|2@1+ (1.0,0.0) [0.0|3] ""  Vector__XXX
 SG_ RPA_Anf_WFS_Freigabe : 42|2@1+ (1.0,0.0) [0.0|3] ""  Vector__XXX
 SG_ PLAIPA_PaCo_SwitchPossible : 44|1@1+ (1.0,0.0) [0.0|1] ""  Vector__XXX
 SG_ PLAIPA_PaCo_ParkingSlots : 45|3@1+ (1.0,0.0) [0.0|7] ""  Vector__XXX
 SG_ PLAIPA_PaCo_UnavailableReason : 48|4@1+ (1.0,0.0) [0.0|15] ""  MFK,MFK120
 SG_ PLAIPA_PaCo_InterventionPossible : 52|1@1+ (1.0,0.0) [0.0|1] ""  Vector__XXX
 SG_ PLAIPA_PaCo_MainState : 53|3@1+ (1.0,0.0) [0.0|7] ""  Vector__XXX
 SG_ PLAIPA_PaCo_FunctionState : 56|5@1+ (1.0,0.0) [0.0|31] ""  FASFrontradar,MRR2023
 SG_ PLAIPA_PaCo_PLEPossible : 61|1@1+ (1.0,0.0) [0.0|1] ""  Vector__XXX
 SG_ PLAIPA_PaCo_Button : 62|2@1+ (1.0,0.0) [0.0|3] ""  Vector__XXX

BO_ 1122 PSD_04: 8 ICAS1_X_Gateway
 SG_ PSD_Segment_ID : 0|6@1+ (1,0) [2|63] ""  MFK120,MRR2023
 SG_ PSD_Vorgaenger_Segment_ID : 6|6@1+ (1,0) [2|63] ""  MFK120,MRR2023
 SG_ PSD_Segmentlaenge : 12|7@1+ (2,0) [0|254] "Unit_Meter"  MFK120,MRR2023
 SG_ PSD_Strassenkategorie : 19|3@1+ (1.0,0.0) [0.0|7] ""  MFK120,MRR2023
 SG_ PSD_Endkruemmung : 22|8@1+ (1,0) [0|254] "Unit_None"  MFK120,MRR2023
 SG_ PSD_Endkruemmung_Vorz : 30|1@1+ (1.0,0.0) [0.0|1] ""  MFK120,MRR2023
 SG_ PSD_Idenditaets_ID : 31|6@1+ (1,0) [2|63] ""  MFK120,MRR2023
 SG_ PSD_ADAS_Qualitaet : 37|1@1+ (1.0,0.0) [0.0|1] ""  MFK120,MRR2023
 SG_ PSD_wahrscheinlichster_Pfad : 38|1@1+ (1.0,0.0) [0.0|1] ""  MFK120,MRR2023
 SG_ PSD_Geradester_Pfad : 39|1@1+ (1.0,0.0) [0.0|1] ""  MFK120,MRR2023
 SG_ PSD_Fahrspuren_Anzahl : 40|3@1+ (1.0,0.0) [0.0|7] ""  MFK120,MRR2023
 SG_ PSD_Bebauung : 43|1@1+ (1.0,0.0) [0.0|1] ""  MFK120,MRR2023
 SG_ PSD_Segment_Komplett : 44|1@1+ (1.0,0.0) [0.0|1] ""  MFK120,MRR2023
 SG_ PSD_Rampe : 45|2@1+ (1.0,0.0) [0.0|3] ""  MFK120,MRR2023
 SG_ PSD_Anfangskruemmung : 47|8@1+ (1,0) [0|254] ""  MFK120,MRR2023
 SG_ PSD_Anfangskruemmung_Vorz : 55|1@1+ (1.0,0.0) [0.0|1] ""  MFK120,MRR2023
 SG_ PSD_Abzweigerichtung : 56|1@1+ (1.0,0.0) [0.0|1] ""  MFK120,MRR2023
 SG_ PSD_Abzweigewinkel : 57|7@1+ (1.417323,0) [0.000000|180.000021] ""  MFK120,MRR2023

BO_ 1123 PSD_05: 8 ICAS1_X_Gateway
 SG_ PSD_Pos_Segment_ID : 0|6@1+ (1,0) [2|63] ""  MFK120,MRR2023
 SG_ PSD_Pos_Segmentlaenge : 6|7@1+ (2,0) [0|254] "Unit_Meter"  MFK120,MRR2023
 SG_ PSD_Pos_Inhibitzeit : 13|5@1+ (10,0) [0|310] "Unit_MilliSecon"  MFK120,MRR2023
 SG_ PSD_Pos_Standort_Eindeutig : 18|1@1+ (1.0,0.0) [0.0|1] ""  MFK120,MRR2023
 SG_ PSD_Pos_Fehler_Laengsrichtung : 19|3@1+ (1.0,0.0) [0.0|7] ""  MFK120,MRR2023
 SG_ PSD_Pos_Fahrspur : 22|3@1+ (1.0,0.0) [0.0|7] ""  MFK120,MRR2023
 SG_ PSD_Attribut_Segment_ID_05 : 25|6@1+ (1,0) [2|63] ""  MFK120,MRR2023
 SG_ PSD_Attribut_1_ID : 31|5@1+ (1,0) [1|31] ""  MFK120,MRR2023
 SG_ PSD_Attribut_1_Wert : 36|4@1+ (1,0) [0|15] "Unit_None"  MFK120,MRR2023
 SG_ PSD_Attribut_1_Offset : 40|7@1+ (2,0) [0|254] "Unit_Meter"  MFK120,MRR2023
 SG_ PSD_Attribut_2_ID : 47|5@1+ (1,0) [1|31] ""  MFK120,MRR2023
 SG_ PSD_Attribut_2_Wert : 52|4@1+ (1,0) [0|15] "Unit_None"  MFK120,MRR2023
 SG_ PSD_Attribut_2_Offset : 56|7@1+ (2,0) [0|254] "Unit_Meter"  MFK120,MRR2023
 SG_ PSD_Attribute_Komplett_05 : 63|1@1+ (1.0,0.0) [0.0|1] ""  MFK120,MRR2023

BO_ 1124 PSD_06: 8 ICAS1_X_Gateway
 SG_ PSD_06_Mux M  : 0|3@1+ (1.0,0.0) [0.0|7] ""  MFK120,MRR2023
 SG_ PSD_Sys_Segment_ID m0  : 3|6@1+ (1,0) [2|63] ""  MFK120,MRR2023
 SG_ PSD_Attribut_Segment_ID m1  : 3|6@1+ (1,0) [2|63] ""  MFK120,MRR2023
 SG_ PSD_Ges_Segment_ID m2  : 3|6@1+ (1,0) [2|63] ""  MFK120,MRR2023
 SG_ PSD_Baum_Laenge_VZ m3  : 3|1@1+ (1.0,0.0) [0.0|1] ""  MFK120,MRR2023
 SG_ PSD_Steigung_1_Segment_ID m4  : 3|6@1+ (1,0) [2|63] ""  MFK120,MRR2023
 SG_ PSD_Baum_Laenge m3  : 4|25@1+ (0.00001,0) [0.00000|180.00000] "Unit_DegreOfArc"  MFK120,MRR2023
 SG_ PSD_Sys_Laendercode m0  : 9|8@1+ (1,0) [0|255] "Unit_None"  MFK120,MRR2023
 SG_ PSD_Attribut_3_ID m1  : 9|5@1+ (1,0) [1|31] ""  MFK120,MRR2023
 SG_ PSD_Ges_Offset m2  : 9|7@1+ (2,0) [0|254] "Unit_Meter"  MFK120,MRR2023
 SG_ PSD_Steigung_1_A_Steigung m4  : 9|7@1+ (0.12,0) [0.00|15.00] "Unit_PerCent"  MFK120,MRR2023
 SG_ PSD_Attribut_3_Offset m1  : 14|7@1+ (2,0) [0|254] "Unit_Meter"  MFK120,MRR2023
 SG_ PSD_Ges_Geschwindigkeit m2  : 16|5@1+ (1.0,0.0) [0.0|31] ""  MFK120,MRR2023
 SG_ PSD_Steigung_1_A_Vorz m4  : 16|1@1+ (1.0,0.0) [0.0|1] ""  MFK120,MRR2023
 SG_ PSD_Sys_Geschwindigkeit_Einheit m0  : 17|1@1+ (1.0,0.0) [0.0|1] ""  MFK120,MRR2023
 SG_ PSD_Steigung_1_A_Offset m4  : 17|7@1+ (2,0) [0|254] "Unit_Meter"  MFK120,MRR2023
 SG_ PSD_Sys_Verkehrsrichtung m0  : 18|1@1+ (1.0,0.0) [0.0|1] ""  MFK120,MRR2023
 SG_ PSD_Sys_Geometrieguete m0  : 19|2@1+ (1.0,0.0) [0.0|3] ""  MFK120,MRR2023
 SG_ PSD_Sys_Mapmatchingguete m0  : 21|2@1+ (1.0,0.0) [0.0|3] ""  MFK120,MRR2023
 SG_ PSD_Attribut_3_Wert m1  : 21|4@1+ (1,0) [0|15] "Unit_None"  MFK120,MRR2023
 SG_ PSD_Ges_Typ m2  : 21|2@1+ (1.0,0.0) [0.0|3] ""  MFK120,MRR2023
 SG_ PSD_Sys_Alter_Karte m0  : 23|3@1+ (1.0,0.0) [0.0|7] ""  MFK120,MRR2023
 SG_ PSD_Ges_Spur_Geschw_Begrenzung m2  : 23|6@1+ (1.0,0.0) [0.0|63] ""  MFK120,MRR2023
 SG_ PSD_Steigung_1_B_Steigung m4  : 24|7@1+ (0.12,0) [0.00|15.00] "Unit_PerCent"  MFK120,MRR2023
 SG_ PSD_Attribut_4_ID m1  : 25|5@1+ (1,0) [1|31] ""  MFK120,MRR2023
 SG_ PSD_Sys_Zielfuehrung m0  : 26|1@1+ (1.0,0.0) [0.0|1] ""  MFK120,MRR2023
 SG_ PSD_Sys_US_State m0  : 27|6@1+ (1.0,0.0) [0.0|63] ""  MFK120,MRR2023
 SG_ PSD_Ges_Geschwindigkeit_Gespann m2  : 29|2@1+ (1.0,0.0) [0.0|3] ""  MFK120,MRR2023
 SG_ PSD_Baum_Breite_VZ m3  : 29|1@1+ (1.0,0.0) [0.0|1] ""  MFK120,MRR2023
 SG_ PSD_Attribut_4_Wert m1  : 30|4@1+ (1,0) [0|15] ""  MFK120,MRR2023
 SG_ PSD_Baum_Breite m3  : 30|24@1+ (0.00001,0) [0.00000|90.00000] "Unit_DegreOfArc"  MFK120,MRR2023
 SG_ PSD_Ges_Geschwindigkeit_Witter m2  : 31|2@1+ (1.0,0.0) [0.0|3] ""  MFK120,MRR2023
 SG_ PSD_Steigung_1_B_Vorz m4  : 31|1@1+ (1.0,0.0) [0.0|1] ""  MFK120,MRR2023
 SG_ PSD_Steigung_1_B_Offset m4  : 32|7@1+ (2,0) [0|254] "Unit_Meter"  MFK120,MRR2023
 SG_ PSD_Sys_Quali_Geometrien m0  : 33|3@1+ (1,0) [0|7] "Unit_None"  MFK120,MRR2023
 SG_ PSD_Ges_Geschwindigkeit_Tag_Anf m2  : 33|3@1+ (1.0,0.0) [0.0|7] ""  MFK120,MRR2023
 SG_ PSD_Attribut_4_Offset m1  : 34|7@1+ (2,0) [0|254] "Unit_Meter"  MFK120,MRR2023
 SG_ PSD_Sys_Quali_Ortsinfo m0  : 36|2@1+ (1,0) [0|3] "Unit_None"  MFK120,MRR2023
 SG_ PSD_Ges_Geschwindigkeit_Tag_Ende m2  : 36|3@1+ (1.0,0.0) [0.0|7] ""  MFK120,MRR2023
 SG_ PSD_Sys_Quali_verfuegbar m0  : 38|1@1+ (1.0,0.0) [0.0|1] ""  MFK120,MRR2023
 SG_ PSD_Sys_Zielfuehrung_geaendert m0  : 39|1@1+ (1.0,0.0) [0.0|1] ""  MFK120,MRR2023
 SG_ PSD_Ges_Geschwindigkeit_Std_Anf m2  : 39|5@1+ (1,0) [0|24] "Unit_Hours"  MFK120,MRR2023
 SG_ PSD_Steigung_1_Attribute_kompl m4  : 39|1@1+ (1.0,0.0) [0.0|1] ""  MFK120,MRR2023
 SG_ PSD_Sys_Geometrieguete_erweitert m0  : 40|8@1+ (1.0,0.0) [0.0|255] ""  MFK120,MRR2023
 SG_ PSD_Steigung_2_Segment_ID m4  : 40|6@1+ (1,0) [2|63] ""  MFK120,MRR2023
 SG_ PSD_Attribut_5_ID m1  : 41|5@1+ (1,0) [1|31] ""  MFK120,MRR2023
 SG_ PSD_Ges_Geschwindigkeit_Std_Ende m2  : 44|5@1+ (1,0) [0|24] "Unit_Hours"  MFK120,MRR2023
 SG_ PSD_Attribut_5_Offset m1  : 46|7@1+ (2,0) [0|254] "Unit_Meter"  MFK120,MRR2023
 SG_ PSD_Steigung_2_Steigung m4  : 46|7@1+ (0.12,0) [0.00|15.00] "Unit_PerCent"  MFK120,MRR2023
 SG_ PSD_Sys_Quali_sonstige_Attribute m0  : 48|3@1+ (1,0) [0|7] "Unit_None"  MFK120,MRR2023
 SG_ PSD_Ges_Ueberholverbot m2  : 49|2@1+ (1.0,0.0) [0.0|3] ""  MFK120,MRR2023
 SG_ PSD_Sys_Quali_Steigungen m0  : 51|3@1+ (1,0) [0|7] ""  MFK120,MRR2023
 SG_ PSD_Ges_Wechselverkehrszeichen m2  : 51|3@1+ (1.0,0.0) [0.0|7] ""  MFK120,MRR2023
 SG_ PSD_Attribut_5_Wert m1  : 53|4@1+ (1,0) [0|15] ""  MFK120,MRR2023
 SG_ PSD_Steigung_2_Vorz m4  : 53|1@1+ (1.0,0.0) [0.0|1] ""  MFK120,MRR2023
 SG_ PSD_Sys_Quali_Strassenkennz m0  : 54|3@1+ (1,0) [0|7] "Unit_None"  MFK120,MRR2023
 SG_ PSD_Wechselverkehrszeichen_Typ m2  : 54|2@1+ (1.0,0.0) [0.0|3] ""  MFK120,MRR2023
 SG_ PSD_Baum_Ausrichtung m3  : 54|10@1+ (0.3515625,0) [0E-7|359.6484375] "Unit_DegreOfArc"  MFK120,MRR2023
 SG_ PSD_Steigung_2_Offset m4  : 54|7@1+ (2,0) [0|254] "Unit_Meter"  MFK120,MRR2023
 SG_ PSD_Ges_Gesetzlich_Kategorie m2  : 56|3@1+ (1.0,0.0) [0.0|7] ""  MFK120,MRR2023
 SG_ PSD_Sys_Quali_Tempolimits m0  : 57|3@1+ (1,0) [0|7] "Unit_None"  MFK120,MRR2023
 SG_ PSD_Attribute_Komplett_06 m1  : 57|1@1+ (1.0,0.0) [0.0|1] ""  MFK120,MRR2023
 SG_ PSD_Ges_Gesetzlich_Zusatz m2  : 59|2@1+ (1.0,0.0) [0.0|3] ""  MFK120,MRR2023
 SG_ PSD_Sys_Quali_Vorfahrtsregelung m0  : 60|3@1+ (1,0) [0|7] "Unit_None"  MFK120,MRR2023
 SG_ PSD_Ges_Verkehrszeichen_Quelle m2  : 61|2@1+ (1.0,0.0) [0.0|3] ""  MFK120,MRR2023
 SG_ PSD_Steigung_2_Attribute_kompl m4  : 61|1@1+ (1.0,0.0) [0.0|1] ""  MFK120,MRR2023
 SG_ PSD_Ges_Attribute_Komplett m2  : 63|1@1+ (1.0,0.0) [0.0|1] ""  MFK120,MRR2023

BO_ 317 QFK_01_Auth: 32 ICAS1_X_Gateway
 SG_ QFK_01_CRC : 0|8@1+ (1,0) [0|255] ""  Vector__XXX
 SG_ QFK_01_BZ : 8|4@1+ (1,0) [0|15] ""  Vector__XXX
 SG_ QFK_01_Sendestatus : 12|1@1+ (1.0,0.0) [0.0|1] ""  MFK
 SG_ QFK_stEingriffBr : 13|1@1+ (1.0,0.0) [0.0|1] ""  MFK,MFK120
 SG_ QFK_DynBegr_aktiv : 14|1@1+ (1.0,0.0) [0.0|1] ""  FASFrontradar,MFK,MFK120,MRR2023
 SG_ QFK_Anf_Giermomoffset_VZ : 15|1@1+ (1.0,0.0) [0.0|1] ""  MFK,MFK120
 SG_ QFK_Status : 16|4@1+ (1.0,0.0) [0.0|15] ""  FASFrontradar,MFK,MFK120,MRR2023
 SG_ QFK_stHCA : 20|4@1+ (1.0,0.0) [0.0|15] ""  MFK,MFK120
 SG_ QFK_stPLA : 24|4@1+ (1.0,0.0) [0.0|15] ""  Vector__XXX
 SG_ QFK_stAWV : 28|4@1+ (1.0,0.0) [0.0|15] ""  FASFrontradar,MRR2023
 SG_ QFK_stDSR : 32|4@1+ (1.0,0.0) [0.0|15] ""  FASFrontradar,MRR2023
 SG_ QFK_ZPosIst_VZ : 36|1@1+ (1.0,0.0) [0.0|1] ""  Vector__XXX
 SG_ QFK_KrIst_VZ : 37|1@1+ (1.0,0.0) [0.0|1] ""  MFK,MFK120
 SG_ QFK_IstKraft_VZ : 38|1@1+ (1.0,0.0) [0.0|1] ""  MFK,MFK120
 SG_ QFK_KruemmIst : 40|15@1+ (0.0000067,0) [0E-7|0.2195389] "Unit_MeterInver"  FASFrontradar,MFK,MFK120,MRR2023
 SG_ QFK_KruemmIst_VZ : 55|1@1+ (1.0,0.0) [0.0|1] ""  FASFrontradar,MFK,MFK120,MRR2023
 SG_ QFK_IstKraftNiveau : 56|7@1+ (1,0) [0|100] "Unit_PerCent"  MFK,MFK120
 SG_ QFK_IstKraftNiveau_VZ : 63|1@1+ (1.0,0.0) [0.0|1] ""  MFK,MFK120
 SG_ QFK_Anf_Giermomoffset : 64|12@1+ (0.65,0) [0.00|2661.75] "Unit_NewtoMeter"  MFK,MFK120
 SG_ QFK_ZPosIst : 76|16@1+ (0.00153,0) [0.00000|100.26702] "Unit_MilliMeter"  Vector__XXX
 SG_ QFK_stMA : 92|4@1+ (1.0,0.0) [0.0|15] ""  Vector__XXX
 SG_ QFK_KrIst : 96|16@1+ (0.0000067,0) [0E-7|0.4390711] "Unit_MeterInver"  MFK,MFK120
 SG_ QFK_IstKraft : 112|10@1+ (30,0) [0|30630] "Unit_Newto"  MFK,MFK120
 SG_ SOK_QFK_01_Signatur : 224|32@1+ (1,0) [0|4294967295] ""  Vector__XXX

BO_ 591 RDR1_Objekte_02: 64 FASFrontradar
 SG_ RDR1_relevanter_Fehler : 12|1@1+ (1.0,0.0) [0.0|1] ""  ICAS1_X_Gateway
 SG_ RDR1_Blindheit_erkannt : 13|1@1+ (1.0,0.0) [0.0|1] ""  ICAS1_X_Gateway
 SG_ RDR1_relev_Nichtverfuegbarkeit : 14|1@1+ (1.0,0.0) [0.0|1] ""  ICAS1_X_Gateway
 SG_ RDR1_Obj_01_Nummer : 16|6@1+ (1,0) [0|63] ""  ICAS1_X_Gateway
 SG_ RDR1_Obj_02_Nummer : 22|6@1+ (1,0) [0|63] ""  ICAS1_X_Gateway
 SG_ RDR1_Obj_03_Nummer : 28|6@1+ (1,0) [0|63] ""  ICAS1_X_Gateway
 SG_ RDR1_Obj_04_Nummer : 34|6@1+ (1,0) [0|63] ""  ICAS1_X_Gateway
 SG_ RDR1_Obj_05_Nummer : 40|6@1+ (1,0) [0|63] ""  ICAS1_X_Gateway
 SG_ RDR1_Obj_06_Nummer : 46|6@1+ (1,0) [0|63] ""  ICAS1_X_Gateway
 SG_ RDR1_Verkehrssinn : 52|2@1+ (1.0,0.0) [0.0|3] ""  ICAS1_X_Gateway
 SG_ RDR1_Objekte_02_Datenalter : 54|10@1+ (0.0009765625,0) [0E-10|0.9980468750] "Unit_Secon"  ICAS1_X_Gateway
 SG_ RDR1_Obj_01_dx_v : 64|12@1+ (0.0625,0) [0.0000|255.9375] "Unit_Meter"  ICAS1_X_Gateway
 SG_ RDR1_Obj_01_dy_v : 76|10@1+ (0.0625,-32) [-32.0000|31.9375] "Unit_Meter"  ICAS1_X_Gateway
 SG_ RDR1_Obj_01_vx_v : 86|10@1+ (0.25,-128) [-128.00|127.75] "Unit_MeterPerSecon"  ICAS1_X_Gateway
 SG_ RDR1_Obj_02_dx_v : 96|12@1+ (0.0625,0) [0.0000|255.9375] "Unit_Meter"  ICAS1_X_Gateway
 SG_ RDR1_Obj_02_dy_v : 108|10@1+ (0.0625,-32) [-32.0000|31.9375] "Unit_Meter"  ICAS1_X_Gateway
 SG_ RDR1_Obj_02_vx_v : 118|10@1+ (0.25,-128) [-128.00|127.75] "Unit_MeterPerSecon"  ICAS1_X_Gateway
 SG_ RDR1_Obj_03_dx_v : 128|12@1+ (0.0625,0) [0.0000|255.9375] "Unit_Meter"  ICAS1_X_Gateway
 SG_ RDR1_Obj_03_dy_v : 140|10@1+ (0.0625,-32) [-32.0000|31.9375] "Unit_Meter"  ICAS1_X_Gateway
 SG_ RDR1_Obj_03_vx_v : 150|10@1+ (0.25,-128) [-128.00|127.75] "Unit_MeterPerSecon"  ICAS1_X_Gateway
 SG_ RDR1_Obj_04_dx_v : 160|12@1+ (0.0625,0) [0.0000|255.9375] "Unit_Meter"  ICAS1_X_Gateway
 SG_ RDR1_Obj_04_dy_v : 172|10@1+ (0.0625,-32) [-32.0000|31.9375] "Unit_Meter"  ICAS1_X_Gateway
 SG_ RDR1_Obj_04_vx_v : 182|10@1+ (0.25,-128) [-128.00|127.75] "Unit_MeterPerSecon"  ICAS1_X_Gateway
 SG_ RDR1_Obj_05_dx_v : 192|12@1+ (0.0625,0) [0.0000|255.9375] "Unit_Meter"  ICAS1_X_Gateway
 SG_ RDR1_Obj_05_dy_v : 204|10@1+ (0.0625,-32) [-32.0000|31.9375] "Unit_Meter"  ICAS1_X_Gateway
 SG_ RDR1_Obj_05_vx_v : 214|10@1+ (0.25,-128) [-128.00|127.75] "Unit_MeterPerSecon"  ICAS1_X_Gateway
 SG_ RDR1_Obj_06_dx_v : 224|12@1+ (0.0625,0) [0.0000|255.9375] "Unit_Meter"  ICAS1_X_Gateway
 SG_ RDR1_Obj_06_dy_v : 236|10@1+ (0.0625,-32) [-32.0000|31.9375] "Unit_Meter"  ICAS1_X_Gateway
 SG_ RDR1_Obj_06_vx_v : 246|10@1+ (0.25,-128) [-128.00|127.75] "Unit_MeterPerSecon"  ICAS1_X_Gateway
 SG_ RDR1_Obj_01_ax_v : 256|8@1+ (0.125,-16) [-16.000|15.750] "Unit_MeterPerSeconSquar"  ICAS1_X_Gateway
 SG_ RDR1_Obj_01_ax_StdA : 264|6@1+ (0.125,0) [0.000|7.750] "Unit_MeterPerSeconSquar"  ICAS1_X_Gateway
 SG_ RDR1_Obj_01_vx_StdA : 270|7@1+ (0.03125,0) [0.00000|3.93750] "Unit_MeterPerSecon"  ICAS1_X_Gateway
 SG_ RDR1_Obj_01_dx_StdA : 277|7@1+ (0.05,0) [0.00|6.30] "Unit_Meter"  ICAS1_X_Gateway
 SG_ RDR1_Obj_01_dy_StdA : 284|7@1+ (0.0625,0) [0.0000|7.8750] "Unit_Meter"  ICAS1_X_Gateway

BO_TX_BU_ 2621571671 :FASFrontradar,MRR2023;
BO_TX_BU_ 2589284079 :FASFrontradar,MRR2023;
BO_TX_BU_ 2589284120 :MFK,MFK120;
CM_ BO_ 2621506048 "VDC funktionaler Request auf CANFD";

CM_ SG_ 2331595789 NR_FR_Object_09_10_BlockID_02 "BlockID is a counter to associate data togehter, which are split over severel PDUs.";
CM_ SG_ 2331595789 NR_FR_Object_09_10_BZ "4bit Botschaftszähler, wird mit jeder Sendebotschaft inkrementiert";
CM_ SG_ 2331595789 NR_FR_Object_09_10_CRC "Für MLB:
Berechnung siehe Lastenheft 'Kommunikationsabsicherung für FlexRay und CAN'
Ab MQB und MLBevo:
Berechnung siehe Lastenheft 'End-to-End Kommunikationsabsicherung'

Endwerte siehe Begleitdokument 'S-PDU Kennungsfolgen'";
CM_ SG_ 2331595789 NR_FR_Object_09_aAbsX "The signal indicates the absolute acceleration of the object in the X direction.";
CM_ SG_ 2331595789 NR_FR_Object_09_aAbsXSD "The signal indicates the standard deviation of the absolute acceleration of the object in the X direction.";
CM_ SG_ 2331595789 NR_FR_Object_09_aAbsY "The signal indicates the absolute acceleration of the object in the Y direction.";
CM_ SG_ 2331595789 NR_FR_Object_09_aAbsYSD "The signal indicates the standard deviation of the absolute acceleration of the object in the Y direction.";
CM_ SG_ 2331595789 NR_FR_Object_09_Age "The signal indicates the age of the object. How long has the object been seen";
CM_ SG_ 2331595789 NR_FR_Object_09_Class "The signal indicates the object class.";
CM_ SG_ 2331595789 NR_FR_Object_09_ClassPlausib "The signal indicates the plausibility of the object class.";
CM_ SG_ 2331595789 NR_FR_Object_09_DynamicState "The signal indicates the motion state of the object.";
CM_ SG_ 2331595789 NR_FR_Object_09_ExistProb "The signal indicates the existence probability of the object.";
CM_ SG_ 2331595789 NR_FR_Object_09_ID "Signal indicates the ID of the object.";
CM_ SG_ 2331595789 NR_FR_Object_09_Length "The signal indicates the length of the object.";
CM_ SG_ 2331595789 NR_FR_Object_09_LengthSD "The signal indicates the standard deviation of the length of the object.";
CM_ SG_ 2331595789 NR_FR_Object_09_MeasurementState "The signal indicates whether the object was measured in the current cycle.";
CM_ SG_ 2331595789 NR_FR_Object_09_PosX "Object X position in UKS";
CM_ SG_ 2331595789 NR_FR_Object_09_PosXSD "The signal indicates the standard deviation of the X position";
CM_ SG_ 2331595789 NR_FR_Object_09_PosY "Object Y position in UKS";
CM_ SG_ 2331595789 NR_FR_Object_09_PosYSD "The signal indicates the standard deviation of the Y position";
CM_ SG_ 2331595789 NR_FR_Object_09_ReferencePoint "Reference Point of the Object";
CM_ SG_ 2331595789 NR_FR_Object_09_vAbsX "The signal indicates the velocity in X direction";
CM_ SG_ 2331595789 NR_FR_Object_09_vAbsXSD "The signal indicates the standard deviation of the velocity in X direction";
CM_ SG_ 2331595789 NR_FR_Object_09_vAbsY "The signal indicates the velocity in Y direction.";
CM_ SG_ 2331595789 NR_FR_Object_09_vAbsYSD "The signal indicates the standard deviation of the velocity in Y direction.";
CM_ SG_ 2331595789 NR_FR_Object_09_Width "The signal indicates the width of the object.";
CM_ SG_ 2331595789 NR_FR_Object_09_WidthSD "The signal indicates the standard deviation of the width of the object.";
CM_ SG_ 2331595789 NR_FR_Object_09_YawAngle "The signal indicates the yaw angle of the object relative to the UKS.";
CM_ SG_ 2331595789 NR_FR_Object_09_YawAngleSD "The signal indicates the standard deviation to the yaw angle.";
CM_ SG_ 2331595789 NR_FR_Object_09_YawRateAbs "The signal indicates the yaw rate of the object relative to the UKS.";
CM_ SG_ 2331595789 NR_FR_Object_09_YawRateAbsSD "The signal indicates the standard deviation to the yaw rate.";
CM_ SG_ 2331595789 NR_FR_Object_10_aAbsX "The signal indicates the absolute acceleration of the object in the X direction.";
CM_ SG_ 2331595789 NR_FR_Object_10_aAbsXSD "The signal indicates the standard deviation of the absolute acceleration of the object in the X direction.";
CM_ SG_ 2331595789 NR_FR_Object_10_aAbsY "The signal indicates the absolute acceleration of the object in the Y direction.";
CM_ SG_ 2331595789 NR_FR_Object_10_aAbsYSD "The signal indicates the standard deviation of the absolute acceleration of the object in the Y direction.";
CM_ SG_ 2331595789 NR_FR_Object_10_Age "The signal indicates the age of the object. How long has the object been seen";
CM_ SG_ 2331595789 NR_FR_Object_10_Class "The signal indicates the object class.";
CM_ SG_ 2331595789 NR_FR_Object_10_ClassPlausib "The signal indicates the plausibility of the object class.";
CM_ SG_ 2331595789 NR_FR_Object_10_DynamicState "The signal indicates the motion state of the object.";
CM_ SG_ 2331595789 NR_FR_Object_10_ExistProb "The signal indicates the existence probability of the object.";
CM_ SG_ 2331595789 NR_FR_Object_10_ID "Signal indicates the ID of the object.";
CM_ SG_ 2331595789 NR_FR_Object_10_Length "The signal indicates the length of the object.";
CM_ SG_ 2331595789 NR_FR_Object_10_LengthSD "The signal indicates the standard deviation of the length of the object.";
CM_ SG_ 2331595789 NR_FR_Object_10_MeasurementState "The signal indicates whether the object was measured in the current cycle.";
CM_ SG_ 2331595789 NR_FR_Object_10_PosX "Object X position in UKS";
CM_ SG_ 2331595789 NR_FR_Object_10_PosXSD "The signal indicates the standard deviation of the X position";
CM_ SG_ 2331595789 NR_FR_Object_10_PosY "Object Y position in UKS";
CM_ SG_ 2331595789 NR_FR_Object_10_PosYSD "The signal indicates the standard deviation of the Y position";
CM_ SG_ 2331595789 NR_FR_Object_10_ReferencePoint "Reference Point of the Object";
CM_ SG_ 2331595789 NR_FR_Object_10_vAbsX "The signal indicates the velocity in X direction";
CM_ SG_ 2331595789 NR_FR_Object_10_vAbsXSD "The signal indicates the standard deviation of the velocity in X direction";
CM_ SG_ 2331595789 NR_FR_Object_10_vAbsY "The signal indicates the velocity in Y direction.";
CM_ SG_ 2331595789 NR_FR_Object_10_vAbsYSD "The signal indicates the standard deviation of the velocity in Y direction.";
CM_ SG_ 2331595789 NR_FR_Object_10_Width "The signal indicates the width of the object.";
CM_ SG_ 2331595789 NR_FR_Object_10_WidthSD "The signal indicates the standard deviation of the width of the object.";
CM_ SG_ 2331595789 NR_FR_Object_10_YawAngle "The signal indicates the yaw angle of the object relative to the UKS.";
CM_ SG_ 2331595789 NR_FR_Object_10_YawAngleSD "The signal indicates the standard deviation to the yaw angle.";
CM_ SG_ 2331595789 NR_FR_Object_10_YawRateAbs "The signal indicates the yaw rate of the object relative to the UKS.";
CM_ SG_ 2331595789 NR_FR_Object_10_YawRateAbsSD "The signal indicates the standard deviation to the yaw rate.";
CM_ SG_ 2331595789 SOK_NR_FR_Object_09_10_Signatur "Signatur im Rahmen der durch SOK geschützen Broadcast-Kommunikation
";

CM_ SG_ 2589284097 DS_FR_StructureVersion_1 "Current 'Datensatzversion' structure";
CM_ SG_ 2589284097 DS_FR_StructureVersion_2 "Current 'Datensatzversion' version";
CM_ SG_ 2589284097 NR_FR_HW_Version "Hardware Version (intern)";
CM_ SG_ 2589284097 NR_FR_SerialNumber "Serial number of the component.";
CM_ SG_ 2589284097 NR_FR_SW_Version "Sofware Version of Sensor";

CM_ SG_ 2331595851 NR_FR_Structure_BlockID_02 "BlockID is a counter to associate data togehter, which are split over severel PDUs.";
CM_ SG_ 2331595851 NR_FR_Structure_right_ExistProb "The signal indicates the existence probability of the side cultivation (Randbebauung) structure right";
CM_ SG_ 2331595851 NR_FR_Structure_right_LatDist "Distance to side cultivation (Randbebauung) structure right";
CM_ SG_ 2331595851 NR_FR_Structure_right_Type "Type of side cultivation (Randbebauung) structure right";

CM_ SG_ 2264486984 NR_FR_EarliestStartTime "Signal indicates the earlist chirp sequence start time";
CM_ SG_ 2264486984 NR_FR_InteferenceInfo "Signal indicates the current interferece level";
CM_ SG_ 2264486984 NR_FR_LatestSyncCounter "Signal indicates the latest synchronisation counter";
CM_ SG_ 2264486984 NR_FR_RequestedModulation "Signal indicates the requested modulation mode";
CM_ SG_ 2264486984 NR_FR_SyncCycleCount "Signal indicates the current cycle indication";
CM_ SG_ 2264486984 NR_FR_SyncReadyVersion "Signal indicates the version of synchronisation ready";

CM_ SG_ 2621440599 OBDC_ACC_Req_FD_Data "OnBoard Tester Diagnose Request ACC";

CM_ SG_ 2621571671 OBDC_ACC_Resp_FD_Data "OnBoard Tester Diagnose Response ACC";

CM_ SG_ 2621506048 OBDC_Funktion_Req_All_FD_Data "OnBoard Tester funktionaler Diagnose Request ALL";

CM_ SG_ 2621440591 OBDC_Kamera_Req_FD_Data "OnBoard Tester Diagnose Request FD Kamera.";

CM_ SG_ 2621571663 OBDC_Kamera_Resp_FD_Data "OnBoard Tester Diagnose Response FD Kamera.";

CM_ SG_ 2621440699 OBDC_NR_01_Req_FD_Data "OnBoard Tester Diagnose Request NR_01";

CM_ SG_ 2621571771 OBDC_NR_01_Resp_FD_Data "OnBoard Tester Diagnose Response NR_01";

CM_ SG_ 2621440700 OBDC_NR_02_Req_FD_Data "OnBoard Tester Diagnose Request NR_02";

CM_ SG_ 2621571772 OBDC_NR_02_Resp_FD_Data "OnBoard Tester Diagnose Response NR_02";

CM_ SG_ 2564502513 OBDx_allOBD_Req_Data "Generic Scan Tool funktionaler Diagnose Request ALL OBD";

CM_ SG_ 2589284079 FASFrontradar_ORUData "ORU information multiplexed
- diagnostic address (2 bytes)
- HW-part no   (11 bytes)
- HW version no.   (3 bytes)
- SW version no. (4 bytes)
- IVD-P Value   (64 bytes)

need to be sent in combination with ORUDataIndex";
CM_ SG_ 2589284079 FASFrontradar_ORUDataIndex "Data index of the last 6 Bytes";
CM_ SG_ 2589284079 ORU_0013_BZ "4bit Botschaftszähler, wird mit jeder Sendebotschaft inkrementiert";
CM_ SG_ 2589284079 ORU_0013_CRC "Für MLB:
Berechnung siehe Lastenheft 'Kommunikationsabsicherung für FlexRay und CAN'
Ab MQB und MLBevo:
Berechnung siehe Lastenheft 'End-to-End Kommunikationsabsicherung'

Endwerte siehe Begleitdokument 'S-PDU Kennungsfolgen'";

CM_ SG_ 2589284120 MFK_ORUData "- diagnostic address LowByte=a / Highbyte=b (2 bytes)
- HW-part no cde.fgh.ijk.lm   (11 bytes ASCII)
- HW version no. nop  (3 bytes ACII)
- SW version no. qrst (4 bytes ASCII)
- IVD-P Value   (32 bytes) lowest byte = I1 / highest byte = I32";
CM_ SG_ 2589284120 MFK_ORUDataIndex "Data index of the last 6 Bytes";
CM_ SG_ 2589284120 ORU_00A5_BZ "4bit Botschaftszähler, wird mit jeder Sendebotschaft inkrementiert";
CM_ SG_ 2589284120 ORU_00A5_CRC "Für MLB:
Berechnung siehe Lastenheft 'Kommunikationsabsicherung für FlexRay und CAN'
Ab MQB und MLBevo:
Berechnung siehe Lastenheft 'End-to-End Kommunikationsabsicherung'

Endwerte siehe Begleitdokument 'S-PDU Kennungsfolgen'";

CM_ SG_ 2589283656 ORU_DiagAddress "Diagnostic address of next ECU to be updated";
CM_ SG_ 2589283656 ORU_EM_Anfrage_Flashdauer "Anfrage an das Energiemanagement, ob ein konkretes Online Remote Update durchgeführt werden kann - Flashdauer in 10s.";
CM_ SG_ 2589283656 ORU_EM_Anfrage_freigegebeneNetze "Meldung der während eines konkreten Online Remote Updates freigegebenen Netze (12V, 48V, HV)";
CM_ SG_ 2589283656 ORU_EM_Anfrage_Stromaufnahme "Meldung der voraussichtlichen durchschnittlichen Stromaufnahme eines konkreten Online Remote Updates an das NVEM";
CM_ SG_ 2589283656 ORU_Inventory "Signal zur Anzeige, ob die Inventory Erstellung durch ORU aktiv ist.

0 = Init
1 = ORU Inventory Erstellung ist nicht aktiv
2 = ORU Inventory Erstellung ist aktiv";
CM_ SG_ 2589283656 ORU_Status "Verteilung des internen ORU Zustandes";
CM_ SG_ 2589283656 ORU_Warnung "Wenn durch Störungen der Funktion Online Remote Update nicht sichergestellt ist, dass vor Kunde keine Funktionseinschränkungen auftreten, muss der Benutzer des Fahrzeugs entsprechend gewarnt werden.";

CM_ SG_ 2589284073 ORUG01_01_BZ "4bit Botschaftszähler, wird mit jeder Sendebotschaft inkrementiert";
CM_ SG_ 2589284073 ORUG01_01_CRC "Für MLB:
Berechnung siehe Lastenheft 'Kommunikationsabsicherung für FlexRay und CAN'
Ab MQB und MLBevo:
Berechnung siehe Lastenheft 'End-to-End Kommunikationsabsicherung'

Endwerte siehe Begleitdokument 'S-PDU Kennungsfolgen'";
CM_ SG_ 2589284073 ORUG1_Anforderung_HMS "Request to gain park status to HMS";
CM_ SG_ 2589284073 ORUG1_HVLock "Request to lock HV-System to be de-energized";
CM_ SG_ 2589284073 ORUG1_HVReleased "Combination of the two status fixation state of HV to be de-energized is active and no crash has occured.";
CM_ SG_ 2589284073 ORUG1_Parken_beibehalten_HMS "Request to keep park status to HMS";
CM_ SG_ 2589284073 ORUG1_TargetRelease "Diagnostic address of ECU released to be updated";
CM_ SG_ 2589284073 ORUG1_Warning "Suppress warning on HMI during ORU update";

CM_ SG_ 2589284074 ORUG02_01_BZ "4bit Botschaftszähler, wird mit jeder Sendebotschaft inkrementiert";
CM_ SG_ 2589284074 ORUG02_01_CRC "Für MLB:
Berechnung siehe Lastenheft 'Kommunikationsabsicherung für FlexRay und CAN'
Ab MQB und MLBevo:
Berechnung siehe Lastenheft 'End-to-End Kommunikationsabsicherung'

Endwerte siehe Begleitdokument 'S-PDU Kennungsfolgen'";
CM_ SG_ 2589284074 ORUG2_GuardInfo "Released           = no lock is active
VehLocked         = vehicle lock is active
HVVehLocked    = HV-System is locked";
CM_ SG_ 2589284074 ORUG2_GuardState "Idle            = ORU guards are in Idle state
DataErr      = check of Metadata not succsessful
CountErr    = no. of ECUs differs between data and vehicle
Collecting = data collection from ECUs is incomplete
HwVerErr  = wrong HW version found
Waiting";
CM_ SG_ 2589284074 ORUG2_TargetRelease "Diagnostic address of ECU released to be updated";
CM_ SG_ 2589284074 ORUG2_TorqueLock "Request HV system to prevent bringing torque on the EMotor";

CM_ SG_ 525 PaCo_01_Sendestatus "Gibt den Sendestatus der Botschaft PaCo_01 an (notwendig für IL-Unterstützung)";
CM_ SG_ 525 PaCo_AAA_Intervention "Fahrfreigabe des Kunden.";
CM_ SG_ 525 PaCo_AAA_TargetState "Sollzustand der Kundenfunktion AAA.";
CM_ SG_ 525 PaCo_AEBPR_ImplementationRBFMA "Über dieses Signal wird die Information, ob RBF im Fahrzeug verbaut ist, an die Funktion AEB-PR gesendet.";
CM_ SG_ 525 PaCo_AEBPR_InterventionStrategy "Signal controls AEB-PR function activation";
CM_ SG_ 525 PaCo_APS_AudioLowering "Steuerung der Anforderung der Audioabsenkung

0 Inactive: Die Kundenfunktion APS fordert keine Audioabsenkung bei der Tonausgabe an
1 Active: Die Kundenfunktion APS fordert eine Audioabsenkung bei der Tonausgabe an";
CM_ SG_ 525 PaCo_APS_TargetState "Sollzustand der APS-Funktion.

0 APS_Inactive: APS darf den Fahrer nicht vor Hindernissen warnen.
1 APS_Active: APS muss den Fahrer gemäß seiner Warnstrategie vor Hindernissen warnen.
2 APS_Active_ReducedRange: APS muss den Fahrer mit Hilfe von Warntö";
CM_ SG_ 525 PaCo_APSOPS_DetectionFront "control of obstacle detection in the front
0 Detection_Inactive: APSOPS shall not display obtacles in the front
1 Detection_Active: APSOPS shall display obstacles in the front";
CM_ SG_ 525 PaCo_APSOPS_DetectionRear "control of obstacle detectionin the rear
0 Detection_Inactive: APSOPS shall not display obtacles in the rear
1 Detection_Active: APSOPS shall display obstacles in the rear";
CM_ SG_ 525 PaCo_APSOPS_LED "Steuerung des Zustandes der Funktionsbeleuchtung im PDC-Hardkey.

0 LED_Inactive: Die Funktionsbeleuchtung im PDC-Hardkey muss leuchten
1 LED_Active: Die Funktionsbeleuchtung im PDC-Hardkey darf nicht leuchten
2 LED_Flashing: Die Funktionsbeleuchtung ";
CM_ SG_ 525 PaCo_ARA_InterventionStart "Initiierung der aktiven Regelung der Funktion ARA

Inactive: ARA darf die Regelung nicht übernehmen
Active: ARA muss die Regelung gemäß der ARA-Funktionsstrategie übernehmen";
CM_ SG_ 525 PaCo_ARA_TargetState "Sollzustand der Kundenfunktion ARA

0 Inactive: ARA übernimmt nicht die Querführung des Fahrzeugs und ermöglicht dem Fahrer nicht die Einstellung des Sollknickwinkels
1 Active: ARA übernimmt die Querführung des Fahrzeugs und ermöglicht dem Fahrer die E";
CM_ SG_ 525 PaCo_DiETa_LED "Ansteuerung der Funktionsbeleuchtung im Direkteinstiegstaster ('DiETa') durch den Parking Coordinator ('PaCo').

0 LED_Inactive: Die Funktionsbeleuchtung im DiETa_Parken muss leuchten
1 LED_Active: Die Funktionsbeleuchtung im DiETa_Parken darf nicht le";
CM_ SG_ 525 PaCo_MainState "Hauptzustand des ParkingCoordinator

0 Init: PaCo befindet sich in der Initialisierung
1 InOperation_NoError: PaCo befindet sich im Betrieb ohne Fehler
7 Fehler: PaCo befindet sich im Fehlerzustand";
CM_ SG_ 525 PaCo_OPS_DrivingTube "Steuerung der Übertragung von Fahrschlauchinformationen.

0 Inactive: OPS darf derzeit keine Fahrschlauchinformationen an die Headunit übertragen
1 Active: OPS muss derzeit Fahrschlauchinformationen an die Headunit übertragen";
CM_ SG_ 525 PaCo_OPS_TargetState "Target state of function OPS
0 = function is inactive
1 = function is active
2 = function is active but muted";
CM_ SG_ 525 PaCo_PLAIPA_InterventionStart "Initiierung des aktiven Parkvorgangs

0 Inactive: PLA/IPA darf die Führung des Fahrzeugs für den aktiven Parkvorgang nicht übernehmen
1 Active: PLA/IPA muss die Führung des Fahrzeugs für den aktiven Parkvorgang gemäß der PLA/IPA-Funktionsstrategie über";
CM_ SG_ 525 PaCo_PLAIPA_LED "Steuerung des Zustandes der Funktionsbeleuchtung im PLA/IPA-Hardkey.

0 LED_Inactive: Die Funktionsbeleuchtung im PLA/IPA-Hardkey muss leuchten
1 LED_Active: Die Funktionsbeleuchtung im PLA/IPA-Hardkey darf nicht leuchten
2 LED_Flashing: Die Funktions";
CM_ SG_ 525 PaCo_PLAIPA_PLE "Steuerung des Zustandes der Parklückeneinblendung (PLE)

0 Inactive: PLA/IPA überträgt keine Koordinaten für PLE an die Kamera
1 Active: PLA/IPA überträgt Koordinaten für PLE an die Kamera";
CM_ SG_ 525 PaCo_PLAIPA_SwitchParkSlot "Steuerung zur Übermittlung der Aufforderung an PLA/IPA dem Fahrer die nächste Parklücke anzubieten

0 NotToggle_ToNextParkingSlot: PLA/IPA darf dem Fahrer nicht die nächste Parklücke anbieten
1 Toggle_ToNextParkingSlot: PLA/IPA muss dem Fahrer die näch";
CM_ SG_ 525 PaCo_PLAIPA_TargetState "Sollzustand der Kundenfunktion PLA/IPA

0 Inactive: PLA/IPA ist inakiv vor Kunde
1 Active_Visible: PLA/IPA ist gemäß der PLA/IPA-Funktionsstrategie aktiv vor Kunde
2 DeactBy_NoReason: PLA/IPA muss sich deaktivieren und anschließend inaktiv vor Kunde s";
CM_ SG_ 525 PaCo_RA_InterventionStart "Initiierung des aktiven Rückwärtsfahrens

-----

Signalwerte:
0 Inactive: RA darf die Querführung des Fahrzeugs für das aktive Rückwärtsfahren nicht übernehmen
1 Active: RA muss die Querführung des Fahrzeugs für das aktive Rückwärtsfahren  gemäß der";
CM_ SG_ 525 PaCo_RA_Targetstate "Signal is used to control the activation state of ReverseAssist function in accordance to the Parking PopUp Content in Infotainment";
CM_ SG_ 525 PaCo_RBFMA_ImplementationAEBPR "Dieses Signal übermittelt der Rangierbremsfunktion, ob AEB-PR im Fahrzeug verbaut ist.";
CM_ SG_ 525 PaCo_RBFMA_InterventionStrategy "Steuerung der Eingriffstrategie von RBF/MA.

0 No_Intervention: RBF/MA muss inaktiv vor Kunde sein und darf keine Eingriffe durchführen
1 Only_Braking: RBF/MA muss den Fahrer durch Bremseingriff gemäß der RBF/MA-Warnstrategie unterstützen und darf den ";
CM_ SG_ 525 PaCo_RCTA_InterventionStrategy "Steuerung der Eingriffstrategie der RCTA-Funktion

0 No_Intervention: RCTA muss inaktiv vor Kunde sein und darf keine Eingriffe durchführen
1 Braking: RCTA muss dem Fahrer eine Unterstützung durch Bremseingriff gemäß der RCTA-Warnstrategie anbieten";
CM_ SG_ 525 PaCo_RCTA_Warning "control of RCTA warning output
0=RCTA_Inactive
1=RCTA_Active
2=RCTA_Active_Muted
3=RCTA_Off";
CM_ SG_ 525 PaCo_TPA_TargetState "Sollzustand der Kundenfunktion TPA


0 Inactive: TPA ist inakiv vor Kunde
1 Active_Visible: TPA ist gemäß der TPA-Funktionsstrategie aktiv vor Kunde
2 DeactBy_NoReason: PLA/IPA muss sich deaktivieren und anschließend inaktiv vor Kunde sein
8 DeactBy";
CM_ SG_ 525 PaCo_VPS_DarkenVideo "Steuerung der Schwarzschaltung von VPS

0 Inactive: VPS schaltet das Videobild nicht schwarz
1 Active: VPS schaltet das Videobild schwarz";
CM_ SG_ 525 PaCo_VPS_LED "Steuerung des Zustandes der Funktionsbeleuchtung im VPS-Hardkey.

0 LED_Inactive: Die Funktionsbeleuchtung im VPS-Hardkey muss leuchten
1 LED_Active: Die Funktionsbeleuchtung im VPS-Hardkey darf nicht leuchten
2 LED_Flashing: Die Funktionsbeleuchtung ";
CM_ SG_ 525 PaCo_VPS_PLE "Steuerung des Zustandes der Parklückeneinblendung (PLE)

0 Inactive: VPS blendet keine Parklücken für PLE im Videobild ein
1 Active: VPS blendet Parklücken für PLE im Videobild ein";
CM_ SG_ 525 PaCo_VPS_TargetBirdview "Target-Birdview of the  VPS-Function";
CM_ SG_ 525 PaCo_VPS_TargetBowl "Control of the 3D view direction";
CM_ SG_ 525 PaCo_VPS_TargetCarOverlay "Control of the overlay on the vehicle pictogram 0=noCarOverlay 1=normalCarOverlay 2=transparentCarOverlay";
CM_ SG_ 525 PaCo_VPS_TargetGraphicOverlay "Control of the graphical overlay on the video image";
CM_ SG_ 525 PaCo_VPS_TargetMode "Target-Mode of the VPS-Function";
CM_ SG_ 525 PaCo_VPS_TargetRVCscreen "Signal zum Umschalten der Rearview Ansicht

Werte:
0x0=NoScreen
0x1=Fullscreen
0x2=Side-by-Side / Splitscreen";
CM_ SG_ 525 PaCo_VPS_TargetState "Target-State of the VPS-Function";
CM_ SG_ 525 PaCo_VPS_TargetView "Target-View of the  VPS-Function";

CM_ SG_ 518 IPA_TPA_Abbruch "Signalisierung eines durch IPA erkannten Abbruchs mit Angabe des Grundes";
CM_ SG_ 518 IPA_TPA_ausgerichtetes_Parken "signalisiert TPA, ob ausgerichtetes Einparken aktiv ist";
CM_ SG_ 518 IPA_TPA_Fehler "Signalisierung eines durch IPA erkannten Fehlers mit Angabe der Fehlerart";
CM_ SG_ 518 IPA_TPA_Remote "Status hinsichtlich Umschaltung auf fernbedienten Parkvorgang";
CM_ SG_ 518 IPA_TPA_Remote_Anf "Anforderung für bzw. bei fernbedienten Parkvorgang";
CM_ SG_ 518 IPA_TPA_Status "Status der Funktion IPA gegenüber der Funktion TPA";
CM_ SG_ 518 Parken_01_BZ "4bit Botschaftszähler, wird mit jeder Sendebotschaft inkrementiert";
CM_ SG_ 518 Parken_01_CRC "Für MLB:
Berechnung siehe Lastenheft 'Kommunikationsabsicherung für FlexRay und CAN'
Ab MQB und MLBevo:
Berechnung siehe Lastenheft 'End-to-End Kommunikationsabsicherung'

Endwerte siehe Begleitdokument 'S-PDU Kennungsfolgen'";
CM_ SG_ 518 Parken_aktives_System "Das Signal zeigt an, welches der Parksysteme auf dem zFAS gerade aktiv ist.";
CM_ SG_ 518 Parken_Anforderung_HMS "Anforderung der Dienste des HMS durch die Parkplattform";
CM_ SG_ 518 Parken_Anhalteweg_Anf "Zeigt eine Anhalteweg Anforderung an";
CM_ SG_ 518 Parken_beibehalten "Fordert das Parken beim HMS an";
CM_ SG_ 518 Parken_BKD_Anf "Anforderung der Systemtotzeitoptimierung ans VZM";
CM_ SG_ 518 Parken_Blinker_li_Anf "Anforderung seitens Parkens für 'Links blinken'";
CM_ SG_ 518 Parken_Blinker_re_Anf "Anforderung seitens Parken für 'Rechts blinken'";
CM_ SG_ 518 Parken_Bordstein_Winkel "Winkel zwischen Bordstein und Fahrzeug.";
CM_ SG_ 518 Parken_erhoehtes_Moment "Anforderung einer spezifizierten Motormomenten-Rampe seitens IPA/PiloPa für das Überfahren einer Schwelle oder eines Bordsteins.";
CM_ SG_ 518 Parken_Fahrbereitschaft_Anf "Anforderung seitens iPA/pilotiertes Parken, die Fahrbereitschaft aufrecht zu erhalten und das Verlassenskonzept im MSG beim „automatischen Parkvorgang“ zu deaktivieren.";
CM_ SG_ 518 Parken_Fahrstufenwunsch "Fahrstufenwunsch von IPAe/RPAe an das Getriebe";
CM_ SG_ 518 Parken_max_Beschleunigung "Maximale zulässige Beschleunigung der Parkfunktion";
CM_ SG_ 518 Parken_max_Geschwindigkeit "Maximale zulässige Geschwindigkeit der Parkfunktion";
CM_ SG_ 518 Parken_Motorlauf_Anf "Anforderung Motorlauf seitens PiloPa";
CM_ SG_ 518 Parken_Notstopp_Anf "Anforderung Notstopp der Parkplattform";
CM_ SG_ 518 Parken_Prefill_Anf "Anforderung Prefill am VZM";
CM_ SG_ 518 Parken_Schleichfahrt_Anf "Anforderungen des Schleichfahrtmodus.";
CM_ SG_ 518 Parken_Soll_Anhalteweg_Anf "Anforderung des Soll Anhalteweges der PPF beim VZM";
CM_ SG_ 518 Parken_Sollbeschleunigung "Anforderung einer Parkenfunktion an den TSK, das Fahrzeug zu beschleunigen.";
CM_ SG_ 518 Parken_Status_IPA_TSK "Statusinformation vom IPA für Handshakemechanismus mit TSK";
CM_ SG_ 518 Parken_Verz_Anf "Zeigt die die angeforderte Verzögerung an";
CM_ SG_ 518 Parken_Verz_Anf_ASIL "Angabe des ASIL Levels der aktuell aktiven Funtkion auf der Parkplattform";
CM_ SG_ 518 Parken_Warnruck_Anf "Signal zur Anforderung Warnruck beim VZM";
CM_ SG_ 518 Parken_Warnruckeln_Anf "Anforderung Warnruckeln beim VZM";

CM_ SG_ 796 PCS_Li_BlockID "BlockID is a counter to associate objects to the measurement cylce (one block contains header plus objects).";
CM_ SG_ 796 PCS_Li_CS "Prädizierte Schwere für eine Kollision.";
CM_ SG_ 796 PCS_Li_CW "Kollisionswahrscheinlichkeit";
CM_ SG_ 796 PCS_Li_MessZeitpunkt "Wann wurden die Objekte gemessen? (analog Masterzeit)";
CM_ SG_ 796 PCS_Li_Status "Status der PCS-Komponente auf dem linkem Nanoradar.";
CM_ SG_ 796 PCS_Li_TTC "Prädizierte Zeit bis zur Kollision.";

CM_ SG_ 797 PCS_Re_BlockID "BlockID is a counter to associate objects to the measurement cylce (one block contains header plus objects).";
CM_ SG_ 797 PCS_Re_CS "Prädizierte Schwere für eine Kollision.";
CM_ SG_ 797 PCS_Re_CW "Kollisionswahrscheinlichkeit";
CM_ SG_ 797 PCS_Re_MessZeitpunkt "Wann wurden die Objekte gemessen? (analog Masterzeit)";
CM_ SG_ 797 PCS_Re_Status "Status der PCS-Komponente auf dem rechten Nanoradar.";
CM_ SG_ 797 PCS_Re_TTC "Prädizierte Zeit bis zur Kollision.";

CM_ SG_ 2527679498 IAA_Active_User_ID "Signal gibt die IAA Nutzer ID des aktiven IAA Nutzers an.";
CM_ SG_ 2527679498 IAA_Identified_User_ID "Signal gibt die IAA Nutzer ID des vom BCM identifizierten IAA Nutzers an";
CM_ SG_ 2527679498 IAA_PSO_wake_up "Signal zum Wake_up der IAA und PSO Komponenten im Kombi und in der OCU";
CM_ SG_ 2527679498 Perso_Aktiv "Status Personalisierung für den Fahrer aktiviert/ deaktiviert (via HMI)";
CM_ SG_ 2527679498 Perso_Bedienstelle "Signal zeigt an, über welche Bedienstelle die Umschaltung des Benutzerkontos gestartet wurden.";
CM_ SG_ 2527679498 Perso_Fahrernummer "Signal gibt die jewels aktuelle Nummer des Fahrers für die Personalisierung an.
Nicht für AU736 und AU48x.";
CM_ SG_ 2527679498 Perso_Freigabe_Verstellung "Signal zeigt an, ob die Ergonomiefunktionen nach Umschaltung des Benutzerkontos verfahren dürfen.";
CM_ SG_ 2527679498 Perso_Kontonummer "Signal gibt die jewels aktuelle Kontonummer für die Personalisierung an.
Nicht für AU736 und AU48x.";
CM_ SG_ 2527679498 Perso_Schreibschutz "Signal zeigt an, ob der Schreibschutz der Personalisierung aktiv ist.";
CM_ SG_ 2527679498 Perso_Status "Codierstatus der Personalisierung
Nicht für AU736 und AU49x.";
CM_ SG_ 2527679498 Perso_Steuerung "Signal gibt einen Steuerungsbefehl an die Funktionsteilnehmer der Personalisierung.
Nicht für AU736 und AU49x.";
CM_ SG_ 2527679498 Perso_Steuerungsparameter "Signal gibt einen Parameter zum Steuerungsbefehl (Signal Perso_Steuerung) für die Personalisierung an.
Nicht für AU736 und AU49x.";

CM_ SG_ 1031 PLA_04_BZ "4bit Botschaftszähler, wird mit jeder Sendebotschaft inkrementiert";
CM_ SG_ 1031 PLA_04_CRC "Für MLB:
Berechnung siehe Lastenheft 'Kommunikationsabsicherung für FlexRay und CAN'
Ab MQB und MLBevo:
Berechnung siehe Lastenheft 'End-to-End Kommunikationsabsicherung'

Endwerte siehe Begleitdokument 'S-PDU Kennungsfolgen'";
CM_ SG_ 1031 PLAIPA_PaCo_Button "Signalisierung eines gedrückten PLA/IPA-Hardkeys.

0 Init_Or_Not_Equipped: Init oder kein PLA/IPA-Hardkey vorhanden
1 Button_Not_Pressed: PLA/IPA-Hardkey ist nicht gedrückt
2 Button_Pressed_Debounced: PLA/IPA-Hardkey ist gedrückt (entprellt)
3 Error:";
CM_ SG_ 1031 PLAIPA_PaCo_FunctionState "Signalisierung des Funktionszustandes von PLA/IPA

0 ResumePossible: Wiederaufnahme des aktiven Parkvorgangs ist seitens PLA/IPA möglich
1 Park_In_SearchMode: PLA/IPA befindet sich in der Lückensuchfahrt
2 Park_In_SlotFound: PLA/IPA hat mindestens ein";
CM_ SG_ 1031 PLAIPA_PaCo_GarageActivatable "Signalisierung, ob Garagenparken vom Fahrer aktiviert werden kann.";
CM_ SG_ 1031 PLAIPA_PaCo_InterventionPossible "Signalisierung, ob seitens PLA/IPA eine Übernahme der Fahrzeugführung für den (teil-)automatisierten Parkvorgang möglich ist

0 Not_Possible: Die Übernahme der Fahrzeugführung ist seitens PLA/IPA nicht möglich
1 Possible_Or_Active: Die Übernahme der Fa";
CM_ SG_ 1031 PLAIPA_PaCo_MainState "Hauptzustand der Kundenfunktion PLA/IPA.

0 Init: PLAIPA befindet sich in der Initialisierung
1 InOperation_NoError: PLAIPA befindet sich im Betrieb ohne Fehler
7 Fehler: PLAIPA befindet sich im Fehlerzustand";
CM_ SG_ 1031 PLAIPA_PaCo_ParkingSlots "Signalisierung der von PLA/IPA gefundenen Parklücken

0 Nothing: PLA/IPA hat keine Parklücken gefunden
1 One_ParkingSlot: PLA/IPA hat eine Parklücke gefunden
2 Two_ParkingSlots: PLA/IPA hat zwei Parklücken gefunden
3 Three_ParkingSlots: PLA/IPA hat d";
CM_ SG_ 1031 PLAIPA_PaCo_ParkingSlots_02 "Signalisierung der von PLA/IPA gefundenen Parklücken

0 Nothing: PLA/IPA hat keine Parklücken gefunden
1 One_ParkingSlot: PLA/IPA hat eine Parklücke gefunden
2 Two_ParkingSlots: PLA/IPA hat zwei Parklücken gefunden
3 Three_ParkingSlots: PLA/IPA hat d";
CM_ SG_ 1031 PLAIPA_PaCo_PLEPossible "Signalisierung, ob seitens PLA/IPA die Parklückeneinblendung (PLE) zur Verfügung steht

0 Not_Possible: die PLE-Funktionalität von PLA/IPA steht nicht zur Verfügung
1 Possible: die PLE-Funktionalität von PLA/IPA steht zur Verfügung";
CM_ SG_ 1031 PLAIPA_PaCo_RemoteActivatable "Signalisierung, ob RPAe vom Fahrer aktiviert werden kann.";
CM_ SG_ 1031 PLAIPA_PaCo_SwitchPossible "Signalisierung, ob seitens PLA/IPA ein Toggeln zur Auswahl der nächsten Parklücke möglich ist

0 Not_Possible: PLA/IPA kann keine weitere Parklücke als die aktuell ausgewählte dem Fahrer anbieten
1 Possible: PLA/IPA kann eine weitere Parklücke als die ";
CM_ SG_ 1031 PLAIPA_PaCo_UnavailableReason "Signalisierung der Ursache für die Nicht-Verfügbarkeit des PLA/IPA

0 No_Reason: PLA/IPA signalisiert keine Ursache für eine Nicht-Verfügbarkeit
1 EmergencyAssist_active: PLA/IPA steht aufgrund des aktiven Notfallassistenten nicht zur Verfügung.
2 Off";
CM_ SG_ 1031 RA_PaCo_FunctionState "Signalisierung des Funktionszustandes von RA

-----

Signalwerte:
0: Available (verfügbar): RA kann innerhalb der aktuellen Grenzen dem Fahrer die Funktion anbieten.
1: Trajectory_Recording (aufzeichnend): RA speichert eine Trajektorie zum späteren ";
CM_ SG_ 1031 RA_PaCo_InterventionPossible "Signalisierung, ob seitens RA eine Übernahme der Querführung für das Rückwärtsfahren möglich ist

-----

Signalwerte:
0 Not_Possible: Die Übernahme der Querführung ist seitens RA nicht möglich
1 Possible_Or_Active: Die Übernahme der Querführung ist ";
CM_ SG_ 1031 RA_PaCo_MainState "Hauptzustand der Kundenfunktion RA.

-----

Signalwerte:
0 Init: RA befindet sich in der Initialisierung
1 InOperation_NoError: RA befindet sich im Betrieb ohne Fehler
2 Fehler: RA befindet sich im Fehlerzustand";
CM_ SG_ 1031 RA_PaCo_UnavailableReason "Signalisierung für die Verfügbarkeit und die Ursache für die Nicht-Verfügbarkeit des Reversing Assist (RA)

-----

Signalwerte:
0 No_Reason: RA ist verfügbar. Es liegt kein Grund für eine Nicht-Verfügbarkeit vor
1 EmergencyAssist_active: RA steht au";
CM_ SG_ 1031 RA_PaCo_USSensorStatus "Signalverwendung:
0 No_Error: es liegt kein Fehler der Ultraschallsensorik vor
1 Sensor_Defect: es liegt ein Fehler aufgrund eines Sensordefekts vor
2 Sensor_Contaminated: es liegt ein Fehler aufgrund einer Sensorvereisung /-verschmutzung vor";
CM_ SG_ 1031 RPA_Anf_Sonder_Funktion_Status "Hiermit signalisiert die Funktion RemoteParkAssist ihren Zustand únd die Übernahme von bzw. Übergabe an KlemmenKoordinator";
CM_ SG_ 1031 RPA_Anf_Sonder_Klemme_15 "Hiermit fordert die Funktion RemoteParkAssist das Einschalten der Klemme 15 beim KlemmenKoordinator an";
CM_ SG_ 1031 RPA_Anf_WFS_Freigabe "Hiermit übermittelt die Funktion RPA welche Art der Fahrfreigabe beim Herstellen der Zündung notwendig ist";

CM_ SG_ 1122 PSD_Abzweigerichtung "Richtung, in der die Abzweigung von der Hauptroute abzweigt
";
CM_ SG_ 1122 PSD_Abzweigewinkel "Winkel, unter dem die Abzweigung von der Hauptroute abzweigt.
";
CM_ SG_ 1122 PSD_ADAS_Qualitaet "ADAS Qualtität des Streckensegments.";
CM_ SG_ 1122 PSD_Anfangskruemmung "Startkrümmung der Klothoide des übermittelten abzweigenden Streckensegments. 
1/(1+0.155 * x^2) {1/m}'
";
CM_ SG_ 1122 PSD_Anfangskruemmung_Vorz "Vorzeichen für die Startkrümmung bei Abzweigungen
";
CM_ SG_ 1122 PSD_Bebauung "Segement befindet sich innerhalb bebauten Gebietes";
CM_ SG_ 1122 PSD_Endkruemmung "'Endkrümmung der Klotoide des übermittelten Streckensegments. Die Anfangskrümmung des folgenden Streckensegments entspricht der Endkrümmung dieses Segments. Krümmung = 1/(1+0.155 * x²) [1/m]

";
CM_ SG_ 1122 PSD_Fahrspuren_Anzahl "Anzahl der Fahrspuren in Fahrtrichtung
";
CM_ SG_ 1122 PSD_Geradester_Pfad "Segment ist Teil des geradesten Pfades";
CM_ SG_ 1122 PSD_Idenditaets_ID "Identifier auf ein Streckensegment, dass mit dem aktuell übertragenen geometrisch identisch ist.";
CM_ SG_ 1122 PSD_Segment_ID "Identifier des prädiktiven Streckensegments
";
CM_ SG_ 1122 PSD_Segment_Komplett "Zeigt, ob alle Attribute für das Segment übertragen worden sind
";
CM_ SG_ 1122 PSD_Segmentlaenge "Gesamtlänge des prädiktiven Streckensegments";
CM_ SG_ 1122 PSD_Strassenkategorie "Klassifizierung der Straße des beschriebenen Segments
";
CM_ SG_ 1122 PSD_Vorgaenger_Segment_ID "An dem Streckensegment mit diesem Identifier schließt sich das neue Segment mit der ID 'PSD_01_Segment_ID' an.
";
CM_ SG_ 1122 PSD_wahrscheinlichster_Pfad "Identifiziert den vom Navigationssystem berechneten wahrscheinlichsten Pfad des Fahrzeuges. ";

CM_ SG_ 1123 PSD_Attribut_1_ID "Identifier des ersten Attributes";
CM_ SG_ 1123 PSD_Attribut_1_Offset "Positionsoffset im Segment für die Position des Attributs";
CM_ SG_ 1123 PSD_Attribut_1_Wert "Wert des ersten Attributes";
CM_ SG_ 1123 PSD_Attribut_2_ID "Identifier des zweiten Attributes";
CM_ SG_ 1123 PSD_Attribut_2_Offset "Positionsoffset im Segment für die Position des Attributs";
CM_ SG_ 1123 PSD_Attribut_2_Wert "Wert des zweiten Attributes";
CM_ SG_ 1123 PSD_Attribut_Segment_ID_05 "Identifier des Streckensegments, für das die weiteren Attribute in der Botschaft gültig sind";
CM_ SG_ 1123 PSD_Attribute_Komplett_05 "Zeigt, ob alle Attribute für das Segment übertragen worden sind";
CM_ SG_ 1123 PSD_Pos_Fahrspur "Spur, auf der sich das Fahrzeug aktuell befindet";
CM_ SG_ 1123 PSD_Pos_Fehler_Laengsrichtung "Laengsfehler der Positionierung";
CM_ SG_ 1123 PSD_Pos_Inhibitzeit "Zeitspanne zwischen Generierung der PSD Daten im Navigationssystem und Versand der Daten auf den Most
";
CM_ SG_ 1123 PSD_Pos_Segment_ID "Identifier des Streckensegments, auf dem sich das Fahrzeug aktuell befindet
";
CM_ SG_ 1123 PSD_Pos_Segmentlaenge "Verbleibende Länge des Streckensegments, auf dem sich das Fahrzeug aktuell befindet
";
CM_ SG_ 1123 PSD_Pos_Standort_Eindeutig "Ist die Position des Fahrzeugs eindeutig dem aktuelle Segment zugeordnet, oder gibt es fahrbare alternative Segmente, die bei akteller GPS-Position ebenfalls als aktuelles Segment möglich wären.";

CM_ SG_ 1124 PSD_06_Mux "Multiplex Zähler für die PSD_06-Botschaft.
Die unterschiedlichen Muxe folgen keiner festen Reihenfolge. Je nach Inhalt des PSD-Protokolls an der aktuellen Position werden jeweils die notwendigen PSD6-Botschaften gesendet.";
CM_ SG_ 1124 PSD_Attribut_3_ID "Identifier des dritten Attributes";
CM_ SG_ 1124 PSD_Attribut_3_Offset "Positionsoffset im Segment für die Position des Attributs";
CM_ SG_ 1124 PSD_Attribut_3_Wert "Wert des dritten Attributes";
CM_ SG_ 1124 PSD_Attribut_4_ID "Typ von Attribut 4";
CM_ SG_ 1124 PSD_Attribut_4_Offset "Offset von Attribut 4";
CM_ SG_ 1124 PSD_Attribut_4_Wert "Wert von Attribut 4";
CM_ SG_ 1124 PSD_Attribut_5_ID "Typ von Attribut 5";
CM_ SG_ 1124 PSD_Attribut_5_Offset "Offset von Attribut 5";
CM_ SG_ 1124 PSD_Attribut_5_Wert "Wert von Attribut 5";
CM_ SG_ 1124 PSD_Attribut_Segment_ID "Identifier des Streckensegments,für das die weiteren Attribute in der Botschaft gültig sind";
CM_ SG_ 1124 PSD_Attribute_Komplett_06 "Zeigt, ob alle Attribute für das Segment übertragen worden sind
";
CM_ SG_ 1124 PSD_Baum_Ausrichtung "Ausrichtung des Fahrzeugsegments zu Nord";
CM_ SG_ 1124 PSD_Baum_Breite "WGS84 Breite des Fahrzeugsegments";
CM_ SG_ 1124 PSD_Baum_Breite_VZ "Vorzeichen WGS84 Breite des Fahrzeugsegments";
CM_ SG_ 1124 PSD_Baum_Laenge "WGS84 Laenge des Fahrzeugsegments";
CM_ SG_ 1124 PSD_Baum_Laenge_VZ "Vorzeichen WGS84 Laenge des Fahrzeugsegments";
CM_ SG_ 1124 PSD_Ges_Attribute_Komplett "Zeigt, ob alle Attribute für das Segment übertragen worden sind";
CM_ SG_ 1124 PSD_Ges_Geschwindigkeit_Gespann "Gilt diese Einschränkung der Geschwindigkeit für alle Fahrzeuge oder ausschließlich für PKW mit Gespann oder für LKW, Buss, etc.";
CM_ SG_ 1124 PSD_Ges_Geschwindigkeit_Std_Anf "Stunde, zu der die stündliche Geschwindigkeitsbegrenzung beginnt
0h.. 24h";
CM_ SG_ 1124 PSD_Ges_Geschwindigkeit_Std_Ende "Stunde, an der die stündliche Geschwindigkeitsbegrenzung endet
0h.. 24h";
CM_ SG_ 1124 PSD_Ges_Geschwindigkeit_Tag_Anf "Wochentag, an dem die tägliche Geschwindigkeitsbegrenzung beginnt";
CM_ SG_ 1124 PSD_Ges_Geschwindigkeit_Tag_Ende "Wochentag, an dem die tägliche Geschwindigkeitsbegrenzung endet";
CM_ SG_ 1124 PSD_Ges_Geschwindigkeit_Witter "Witterungsabhängigkeit der Geschwindigkeitsbegrenzung";
CM_ SG_ 1124 PSD_Ges_Gesetzlich_Kategorie "Kategorie für das legale Gebot";
CM_ SG_ 1124 PSD_Ges_Gesetzlich_Zusatz "Zusatz für das legale Gebot";
CM_ SG_ 1124 PSD_Ges_Offset "Positionsoffset im Segment für die Position des Attributs";
CM_ SG_ 1124 PSD_Ges_Segment_ID "Identifier des prädiktiven Streckensegments ab dem die Geschwindigkeitsbegrenzungen und mögliche Einschränkungen gelten.
";
CM_ SG_ 1124 PSD_Ges_Spur_Geschw_Begrenzung "Definition der Spuren, für die das übertragene Gebot gilt";
CM_ SG_ 1124 PSD_Ges_Typ "Typ der Geschwindigkeitsbegrenzung
";
CM_ SG_ 1124 PSD_Ges_Verkehrszeichen_Quelle "Quelle der Verkehrszeicheninformation";
CM_ SG_ 1124 PSD_Ges_Wechselverkehrszeichen "Am Beginn des Segments ist ein Wechselverkehrszeichen angebracht.";
CM_ SG_ 1124 PSD_Steigung_1_A_Offset "Positionsoffset im Segment für die Position der Steigung 1 A";
CM_ SG_ 1124 PSD_Steigung_1_A_Steigung "Steigung des Segments ab Offset 1A";
CM_ SG_ 1124 PSD_Steigung_1_A_Vorz "Vorzeichen für Steigung 1 A";
CM_ SG_ 1124 PSD_Steigung_1_Attribute_kompl "Alle Steigungsdaten für dieses Segment gesendet";
CM_ SG_ 1124 PSD_Steigung_1_B_Offset "Positionsoffset im Segment für die Position der Steigung 1 B";
CM_ SG_ 1124 PSD_Steigung_1_B_Steigung "Steigung des Segments ab Offset 1B";
CM_ SG_ 1124 PSD_Steigung_1_B_Vorz "Vorzeichen für Steigung 1 B";
CM_ SG_ 1124 PSD_Steigung_1_Segment_ID "Identifier des prädiktiven Streckensegments, zu dem die  ersten beiden Steigungswerte dieser Botschaft gehören";
CM_ SG_ 1124 PSD_Steigung_2_Attribute_kompl "Alle Steigungsdaten für dieses Segment gesendet";
CM_ SG_ 1124 PSD_Steigung_2_Offset "Positionsoffset im Segment für die Position der Steigung 2";
CM_ SG_ 1124 PSD_Steigung_2_Segment_ID "Identifier des prädiktiven Streckensegments, zu dem der dritte Steigungswert dieser Botschaft gehört";
CM_ SG_ 1124 PSD_Steigung_2_Steigung "Steigung des Segments ab Offset 2";
CM_ SG_ 1124 PSD_Steigung_2_Vorz "Vorzeichen für Steigung 2";
CM_ SG_ 1124 PSD_Sys_Alter_Karte "Alter der Karte";
CM_ SG_ 1124 PSD_Sys_Geometrieguete "Maß für die Güte der Klothoidengeometrie.";
CM_ SG_ 1124 PSD_Sys_Geometrieguete_erweitert "Güte der Kurvenrepräsentation der Klothoiden";
CM_ SG_ 1124 PSD_Sys_Geschwindigkeit_Einheit "Unterscheidung zwischen km/h und miles/h";
CM_ SG_ 1124 PSD_Sys_Laendercode "Ländercode";
CM_ SG_ 1124 PSD_Sys_Mapmatchingguete "Güte des Mapmatchings";
CM_ SG_ 1124 PSD_Sys_Quali_Geometrien "Qualität der Geometrien in dieser Region";
CM_ SG_ 1124 PSD_Sys_Quali_Ortsinfo "Qualität Ortsinformationen (Bebauung, Ortsschild) dieser Region";
CM_ SG_ 1124 PSD_Sys_Quali_sonstige_Attribute "Qualität sonstiger Attribute dieser Region";
CM_ SG_ 1124 PSD_Sys_Quali_Steigungen "Qualität der Steigungen dieser Region";
CM_ SG_ 1124 PSD_Sys_Quali_Strassenkennz "Qualität Straßenkennzeichnungen dieser Region";
CM_ SG_ 1124 PSD_Sys_Quali_Tempolimits "Qualität Tempolimits dieser Region";
CM_ SG_ 1124 PSD_Sys_Quali_verfuegbar "Karte enthält gültige Qualitätskriterien";
CM_ SG_ 1124 PSD_Sys_Quali_Vorfahrtsregelung "Qualität Vorfahrtsregelungen dieser Region";
CM_ SG_ 1124 PSD_Sys_Segment_ID "Identifier des prädiktiven Streckensegments ab dem die Systeminformationen gültig sind.
";
CM_ SG_ 1124 PSD_Sys_US_State "Name des USA-State";
CM_ SG_ 1124 PSD_Sys_Verkehrsrichtung "Unterscheidung zwischen Linksverkehr und Rechtsverkehr";
CM_ SG_ 1124 PSD_Sys_Zielfuehrung "Zielfuehrung im Navigationssystem. Damit lässt sich der wahrscheinlichste Pfad des Fahrzeuges zuverlässig angeben.";
CM_ SG_ 1124 PSD_Sys_Zielfuehrung_geaendert "Die Zielführung (Route) hat sich geändert hat ohne dass der Fahrer eine neue Zielführung gestartet hat";
CM_ SG_ 1124 PSD_Wechselverkehrszeichen_Typ "Typ des Wechselverkehrszeichen";

CM_ SG_ 317 QFK_01_BZ "4bit Botschaftszähler, wird mit jeder Sendebotschaft inkrementiert";
CM_ SG_ 317 QFK_01_CRC "Für MLB:
Berechnung siehe Lastenheft 'Kommunikationsabsicherung für FlexRay und CAN'
Ab MQB und MLBevo:
Berechnung siehe Lastenheft 'End-to-End Kommunikationsabsicherung'

Endwerte siehe Begleitdokument 'S-PDU Kennungsfolgen'";
CM_ SG_ 317 QFK_01_Sendestatus "Umschalten zwischen langsamem und schnellem Zyklus der QFK_01-Botschaft";
CM_ SG_ 317 QFK_Anf_Giermomoffset "Giermomentenanforderung an das ESC";
CM_ SG_ 317 QFK_Anf_Giermomoffset_VZ "Giermomentenanforderung an das ESC Vorzeichen";
CM_ SG_ 317 QFK_DynBegr_aktiv "Aktueller Eingriff wird durch Sicherheits-
Ebene beschränkt";
CM_ SG_ 317 QFK_IstKraft "QFK IstKraft Bedienung mit gem. QFK Masterlastenheft";
CM_ SG_ 317 QFK_IstKraft_VZ "Vorzeicheninformation des Signals QFK_IstKraft";
CM_ SG_ 317 QFK_IstKraftNiveau "QFK Ist-Kraftniveau";
CM_ SG_ 317 QFK_IstKraftNiveau_VZ "Vorzeichen QFK Ist-Kraftniveau";
CM_ SG_ 317 QFK_KrIst "QFK Ist-Krümmung erweiterter Wertebereich";
CM_ SG_ 317 QFK_KrIst_VZ "Vorzeicheninformation des Signals QFK_KrIst (Ist-Kruemmung erweiterter Wertebereich)";
CM_ SG_ 317 QFK_KruemmIst "QFK Ist-Krümmung";
CM_ SG_ 317 QFK_KruemmIst_VZ "Vorzeicheninformation der QFK Ist-Kruemmung";
CM_ SG_ 317 QFK_Status "Statussignal für VMM und Teilnehmer";
CM_ SG_ 317 QFK_stAWV "QFK-Statussignal für AWV";
CM_ SG_ 317 QFK_stDSR "QFK-Statussignal für DSR";
CM_ SG_ 317 QFK_stEingriffBr "QFK Status des Bremseneingriffs";
CM_ SG_ 317 QFK_stHCA "QFK-Statussignal für HCA";
CM_ SG_ 317 QFK_stMA "Lenkhilfe QFK Statussignal für MA";
CM_ SG_ 317 QFK_stPLA "QFK-Statussignal für PLA";
CM_ SG_ 317 QFK_ZPosIst "Ist Zahnstangenposition";
CM_ SG_ 317 QFK_ZPosIst_VZ "Zahnstangenposition Vorzeichen";
CM_ SG_ 317 SOK_QFK_01_Signatur "Signatur im Rahmen der durch SOK geschützten Broadcast-Kommunikation

Geschützte Funktion: FAS-Systeme
Geschützte Botschaft: QFK_01";

CM_ SG_ 591 RDR1_Blindheit_erkannt "Blindheitserkennung";
CM_ SG_ 591 RDR1_Obj_01_ax_StdA "Standardabweichung der Relativbeschleunigung in x-Richtung des bezüglich des Ego-Fzg. Momentankurses detektierten Objektes";
CM_ SG_ 591 RDR1_Obj_01_ax_v "Relativbeschleunigung in x-Richtung des bezüglich des Ego-Fzg. Momentankurses detektierten Objektes";
CM_ SG_ 591 RDR1_Obj_01_dx_StdA "Standardabweichung des x-Abstands des bezüglich des Ego-Fzg.-Momentankurses detektierten Objektdatenblocks";
CM_ SG_ 591 RDR1_Obj_01_dx_v "x-Abstand des bezüglich des Ego-Fzg.-Momentankurses detektierten Objektdatenblocks";
CM_ SG_ 591 RDR1_Obj_01_dy_StdA "Standardabweichung des y-Abstands des bezüglich des Ego-Fzg.-Momentankurses detektierten Objektdatenblocks";
CM_ SG_ 591 RDR1_Obj_01_dy_v "y-Abstand des bezüglich des Ego-Fzg.-Momentankurses detektierten Objektdatenblocks";
CM_ SG_ 591 RDR1_Obj_01_Nummer "Interne Objektnummer (Track)";
CM_ SG_ 591 RDR1_Obj_01_vx_StdA "Standardabweichung der Relativgeschwindigkeit in x-Richtung des bezüglich des Ego-Fzg. Momentankurses detektierten Objektes";
CM_ SG_ 591 RDR1_Obj_01_vx_v "Relativgeschwindigkeit in x-Richtung des bezüglich des Ego-Fzg. Momentankurses detektierten Objektes";
CM_ SG_ 591 RDR1_Obj_02_dx_v "x-Abstand des bezüglich des Ego-Fzg.-Momentankurses detektierten Objektdatenblocks";
CM_ SG_ 591 RDR1_Obj_02_dy_v "y-Abstand des bezüglich des Ego-Fzg.-Momentankurses detektierten Objektdatenblocks";
CM_ SG_ 591 RDR1_Obj_02_Nummer "Interne Objektnummer (Track)";
CM_ SG_ 591 RDR1_Obj_02_vx_v "Relativgeschwindigkeit in x-Richtung des bezüglich des Ego-Fzg. Momentankurses detektierten Objektes";
CM_ SG_ 591 RDR1_Obj_03_dx_v "x-Abstand des bezüglich des Ego-Fzg.-Momentankurses detektierten Objektdatenblocks";
CM_ SG_ 591 RDR1_Obj_03_dy_v "y-Abstand des bezüglich des Ego-Fzg.-Momentankurses detektierten Objektdatenblocks";
CM_ SG_ 591 RDR1_Obj_03_Nummer "Interne Objektnummer (Track)";
CM_ SG_ 591 RDR1_Obj_03_vx_v "Relativgeschwindigkeit in x-Richtung des bezüglich des Ego-Fzg. Momentankurses detektierten Objektes";
CM_ SG_ 591 RDR1_Obj_04_dx_v "x-Abstand des bezüglich des Ego-Fzg.-Momentankurses detektierten Objektdatenblocks";
CM_ SG_ 591 RDR1_Obj_04_dy_v "y-Abstand des bezüglich des Ego-Fzg.-Momentankurses detektierten Objektdatenblocks";
CM_ SG_ 591 RDR1_Obj_04_Nummer "Interne Objektnummer (Track)";
CM_ SG_ 591 RDR1_Obj_04_vx_v "Relativgeschwindigkeit in x-Richtung des bezüglich des Ego-Fzg. Momentankurses detektierten Objektes";
CM_ SG_ 591 RDR1_Obj_05_dx_v "x-Abstand des bezüglich des Ego-Fzg.-Momentankurses detektierten Objektdatenblocks";
CM_ SG_ 591 RDR1_Obj_05_dy_v "y-Abstand des bezüglich des Ego-Fzg.-Momentankurses detektierten Objektdatenblocks";
CM_ SG_ 591 RDR1_Obj_05_Nummer "Interne Objektnummer (Track)";
CM_ SG_ 591 RDR1_Obj_05_vx_v "Relativgeschwindigkeit in x-Richtung des bezüglich des Ego-Fzg. Momentankurses detektierten Objektes";
CM_ SG_ 591 RDR1_Obj_06_dx_v "x-Abstand des bezüglich des Ego-Fzg.-Momentankurses detektierten Objektdatenblocks";
CM_ SG_ 591 RDR1_Obj_06_dy_v "y-Abstand des bezüglich des Ego-Fzg.-Momentankurses detektierten Objektdatenblocks";
CM_ SG_ 591 RDR1_Obj_06_Nummer "Interne Objektnummer (Track)";
CM_ SG_ 591 RDR1_Obj_06_vx_v "Relativgeschwindigkeit in x-Richtung des bezüglich des Ego-Fzg. Momentankurses detektierten Objektes";
CM_ SG_ 591 RDR1_Objekte_02_Datenalter "Datenalter der Objekte aus Botschaft RDR1_Objekte_02";
CM_ SG_ 591 RDR1_relev_Nichtverfuegbarkeit "RDR1-SG erkennt eine temporäre Nichtverfügbarkeit, ohne FSP-Eintrag";
CM_ SG_ 591 RDR1_relevanter_Fehler "RDR1-SG erkennt einen Fehler, mit FSP-Eintrag.";
CM_ SG_ 591 RDR1_Verkehrssinn "vom Radar erkannter Verkehrssinn";
BA_DEF_REL_ BU_SG_REL_  "GenSigTimeoutTime" INT 0 65535;
BA_DEF_ BO_  "DiagRequest" ENUM "No", "Yes";
BA_DEF_ BO_  "DiagResponse" ENUM "No", "Yes";
BA_DEF_ BO_  "DiagState" ENUM "No", "Yes";
BA_DEF_ BO_  "GenMsgChkConstant" HEX 0 4095;
BA_DEF_ BO_  "GenMsgCycleTime" INT 0 65535;
BA_DEF_ BO_  "GenMsgCycleTimeFast" INT 0 65535;
BA_DEF_ BO_  "GenMsgDelayTime" INT 0 100000;
BA_DEF_ BO_  "GenMsgILSupport" ENUM "No", "Yes";
BA_DEF_ BO_  "GenMsgNrOfRepetition" INT 0 100;
BA_DEF_ BO_  "GenMsgPDUConstants" STRING;
BA_DEF_ BO_  "GenMsgSendType" ENUM "Cyclic", "not_used", "not_used", "not_used", "not_used", "not_used", "not_used", "IfActive", "NoMsgSendType";
BA_DEF_ BO_  "GenMsgStartDelayTime" INT 0 100000;
BA_DEF_ BO_  "NmMessage" ENUM "No", "Yes";
BA_DEF_ BO_  "NmhMessage" ENUM "No", "Yes";
BA_DEF_ BO_  "MsgType" ENUM "Application", "NM ", "NMH", "TP2.0", "ISO-TP ", "BAP", "EID", "KS", "XCP_PRE_CONFIGURED", "XCP_RUNTIME_CONFIGURED";
BA_DEF_ BO_  "VAGTP20_API" HEX 0 255;
BA_DEF_ BO_  "VAGTP20_DynConnection" ENUM "No", "Yes";
BA_DEF_ BO_  "VAGTP20_DynSetup" ENUM "No", "Yes";
BA_DEF_ BO_  "VAGTP20_StatConnection" ENUM "No", "Yes";
BA_DEF_ BO_  "CANFD_BRS" ENUM "0", "1";
BA_DEF_ BO_  "VFrameFormat" ENUM "StandardCAN", "ExtendedCAN", "reserved", "reserved", "reserved", "reserved", "reserved", "reserved", "reserved", "reserved", "reserved", "reserved", "reserved", "reserved", "StandardCAN_FD", "ExtendedCAN_FD";
BA_DEF_ SG_  "GenSigActiveRepetitions" INT -2147483648 2147483647;
BA_DEF_ SG_  "GenSigInactiveValue" INT -2147483648 2147483647;
BA_DEF_ SG_  "GenSigSendType" ENUM "Cyclic", "OnWrite", "OnWriteWithRepetition", "OnChange", "OnChangeWithRepetition", "IfActive", "IfActiveWithRepetition", "NoSigSendType", "OnChangeAndIfActive", "OnChangeAndIfActiveWithRepetition";
BA_DEF_ SG_  "GenSigStartValue" INT -2147483648 2147483647;
BA_DEF_ SG_  "NWM-WakeupAllowed" ENUM "No", "Yes";
BA_DEF_ SG_  "GenSigFuncType" ENUM "NoFunction", "MsgCounter", "CRC-8", "XOR", "XOR-2", "DatedBit", "SW-Kl15", "CHK", "Constant", "Protocol", "CRC-8-SAE_J1850", "CRC-32", "DataLength", "DataID", "MsgCounter16", "SOK-Signatur", "Cluster";
BA_DEF_ SG_  "GenSigSwitchedByIgnition" ENUM "No", "Yes";
BA_DEF_ SG_  "Fehlerwert" HEX 0 2147483647;
BA_DEF_ SG_  "GenSigMissingSourceValue" HEX 0 2147483647;
BA_DEF_DEF_REL_  "GenSigTimeoutTime" 0;
BA_DEF_DEF_  "DiagRequest" "No";
BA_DEF_DEF_  "DiagResponse" "No";
BA_DEF_DEF_  "DiagState" "No";
BA_DEF_DEF_  "GenMsgChkConstant" 0;
BA_DEF_DEF_  "GenMsgCycleTime" 0;
BA_DEF_DEF_  "GenMsgCycleTimeFast" 0;
BA_DEF_DEF_  "GenMsgDelayTime" 0;
BA_DEF_DEF_  "GenMsgILSupport" "No";
BA_DEF_DEF_  "GenMsgNrOfRepetition" 0;
BA_DEF_DEF_  "GenMsgPDUConstants" "";
BA_DEF_DEF_  "GenMsgSendType" "NoMsgSendType";
BA_DEF_DEF_  "GenMsgStartDelayTime" 0;
BA_DEF_DEF_  "NmMessage" "No";
BA_DEF_DEF_  "NmhMessage" "No";
BA_DEF_DEF_  "MsgType" "Application";
BA_DEF_DEF_  "VAGTP20_API" 0;
BA_DEF_DEF_  "VAGTP20_DynConnection" "No";
BA_DEF_DEF_  "VAGTP20_DynSetup" "No";
BA_DEF_DEF_  "VAGTP20_StatConnection" "No";
BA_DEF_DEF_  "CANFD_BRS" "1";
BA_DEF_DEF_  "VFrameFormat" "StandardCAN";
BA_DEF_DEF_  "GenSigActiveRepetitions" 0;
BA_DEF_DEF_  "GenSigInactiveValue" 0;
BA_DEF_DEF_  "GenSigSendType" "NoSigSendType";
BA_DEF_DEF_  "GenSigStartValue" 0;
BA_DEF_DEF_  "NWM-WakeupAllowed" "No";
BA_DEF_DEF_  "GenSigFuncType" "NoFunction";
BA_DEF_DEF_  "GenSigSwitchedByIgnition" "Yes";
BA_DEF_DEF_  "Fehlerwert" 0;
BA_DEF_DEF_  "GenSigMissingSourceValue" 0;
BA_ "GenMsgCycleTime" BO_ 2331595789 50;
BA_ "GenMsgILSupport" BO_ 2331595789 1;
BA_ "GenMsgPDUConstants" BO_ 2331595789 "0xf9,0xce,0xc4,0xd1,0xb4,0xe2,0x53,0x1a,0x4f,0xef,0xec,0xe4,0x32,0xfb,0xf8,0x65";
BA_ "GenMsgSendType" BO_ 2331595789 0;
BA_ "VFrameFormat" BO_ 2331595789 15;
BA_ "GenMsgCycleTime" BO_ 2589284097 2000;
BA_ "GenMsgILSupport" BO_ 2589284097 1;
BA_ "GenMsgSendType" BO_ 2589284097 0;
BA_ "VFrameFormat" BO_ 2589284097 15;
BA_ "GenMsgCycleTime" BO_ 2331595851 50;
BA_ "GenMsgILSupport" BO_ 2331595851 1;
BA_ "GenMsgSendType" BO_ 2331595851 0;
BA_ "VFrameFormat" BO_ 2331595851 15;
BA_ "GenMsgCycleTime" BO_ 2264486984 50;
BA_ "GenMsgILSupport" BO_ 2264486984 1;
BA_ "GenMsgSendType" BO_ 2264486984 0;
BA_ "VFrameFormat" BO_ 2264486984 15;
BA_ "DiagRequest" BO_ 2621440599 1;
BA_ "MsgType" BO_ 2621440599 4;
BA_ "VFrameFormat" BO_ 2621440599 15;
BA_ "DiagResponse" BO_ 2621571671 1;
BA_ "MsgType" BO_ 2621571671 4;
BA_ "VFrameFormat" BO_ 2621571671 15;
BA_ "DiagState" BO_ 2621506048 1;
BA_ "MsgType" BO_ 2621506048 4;
BA_ "VFrameFormat" BO_ 2621506048 15;
BA_ "DiagRequest" BO_ 2621440591 1;
BA_ "MsgType" BO_ 2621440591 4;
BA_ "VFrameFormat" BO_ 2621440591 15;
BA_ "DiagResponse" BO_ 2621571663 1;
BA_ "MsgType" BO_ 2621571663 4;
BA_ "VFrameFormat" BO_ 2621571663 15;
BA_ "DiagRequest" BO_ 2621440699 1;
BA_ "MsgType" BO_ 2621440699 4;
BA_ "VFrameFormat" BO_ 2621440699 15;
BA_ "DiagResponse" BO_ 2621571771 1;
BA_ "MsgType" BO_ 2621571771 4;
BA_ "VFrameFormat" BO_ 2621571771 15;
BA_ "DiagRequest" BO_ 2621440700 1;
BA_ "MsgType" BO_ 2621440700 4;
BA_ "VFrameFormat" BO_ 2621440700 15;
BA_ "DiagResponse" BO_ 2621571772 1;
BA_ "MsgType" BO_ 2621571772 4;
BA_ "VFrameFormat" BO_ 2621571772 15;
BA_ "DiagState" BO_ 2564502513 1;
BA_ "MsgType" BO_ 2564502513 4;
BA_ "VFrameFormat" BO_ 2564502513 15;
BA_ "GenMsgCycleTime" BO_ 2589284079 500;
BA_ "GenMsgILSupport" BO_ 2589284079 1;
BA_ "GenMsgPDUConstants" BO_ 2589284079 "0xb9,0x99,0x69,0xec,0xc7,0xa8,0x14,0x13,0xf0,0xd6,0xce,0x6f,0x9e,0x7f,0x26,0x33";
BA_ "GenMsgSendType" BO_ 2589284079 0;
BA_ "VFrameFormat" BO_ 2589284079 15;
BA_ "GenMsgCycleTime" BO_ 2589284120 500;
BA_ "GenMsgILSupport" BO_ 2589284120 1;
BA_ "GenMsgPDUConstants" BO_ 2589284120 "0x9f,0x22,0x99,0xda,0x44,0xbe,0x18,0x85,0x97,0x54,0x7b,0x63,0x72,0x7c,0x80,0xf5";
BA_ "GenMsgSendType" BO_ 2589284120 0;
BA_ "VFrameFormat" BO_ 2589284120 15;
BA_ "GenMsgCycleTime" BO_ 2589283656 500;
BA_ "GenMsgDelayTime" BO_ 2589283656 100;
BA_ "GenMsgILSupport" BO_ 2589283656 1;
BA_ "GenMsgPDUConstants" BO_ 2589283656 "0xee,0xcc,0x2f,0x27,0x93,0x0c,0x45,0x97,0x87,0x2e,0xec,0x3b,0xd3,0x35,0xcb,0x4a";
BA_ "GenMsgSendType" BO_ 2589283656 0;
BA_ "VFrameFormat" BO_ 2589283656 15;
BA_ "GenMsgCycleTime" BO_ 2589284073 500;
BA_ "GenMsgILSupport" BO_ 2589284073 1;
BA_ "GenMsgPDUConstants" BO_ 2589284073 "0xdf,0xa2,0xc0,0x44,0x96,0xbf,0x81,0x49,0x65,0xe4,0x1a,0xd1,0xf4,0x10,0xaa,0xac";
BA_ "GenMsgSendType" BO_ 2589284073 0;
BA_ "VFrameFormat" BO_ 2589284073 15;
BA_ "GenMsgCycleTime" BO_ 2589284074 500;
BA_ "GenMsgILSupport" BO_ 2589284074 1;
BA_ "GenMsgPDUConstants" BO_ 2589284074 "0x20,0x60,0x3f,0x23,0x7c,0x96,0x28,0x42,0x0e,0x79,0x90,0xe4,0x40,0xb1,0xce,0x18";
BA_ "GenMsgSendType" BO_ 2589284074 0;
BA_ "VFrameFormat" BO_ 2589284074 15;
BA_ "GenMsgCycleTime" BO_ 525 1000;
BA_ "GenMsgCycleTimeFast" BO_ 525 50;
BA_ "GenMsgDelayTime" BO_ 525 50;
BA_ "GenMsgILSupport" BO_ 525 1;
BA_ "GenMsgNrOfRepetition" BO_ 525 5;
BA_ "GenMsgSendType" BO_ 525 0;
BA_ "VFrameFormat" BO_ 525 14;
BA_ "GenMsgCycleTime" BO_ 518 20;
BA_ "GenMsgILSupport" BO_ 518 1;
BA_ "GenMsgPDUConstants" BO_ 518 "0x09,0xfa,0xca,0x8e,0x62,0xd5,0xd1,0xf0,0x31,0xa0,0xaf,0xda,0x4d,0x1a,0x0a,0x97";
BA_ "GenMsgSendType" BO_ 518 0;
BA_ "VFrameFormat" BO_ 518 14;
BA_ "GenMsgCycleTime" BO_ 796 50;
BA_ "GenMsgILSupport" BO_ 796 1;
BA_ "GenMsgPDUConstants" BO_ 796 "0x82,0xd7,0xb7,0x12,0xad,0x85,0x09,0x7e,0x13,0x0b,0x9c,0x34,0x5a,0xfa,0x87,0x16";
BA_ "GenMsgSendType" BO_ 796 0;
BA_ "VFrameFormat" BO_ 796 14;
BA_ "GenMsgCycleTime" BO_ 797 50;
BA_ "GenMsgILSupport" BO_ 797 1;
BA_ "GenMsgPDUConstants" BO_ 797 "0x0e,0xa2,0xbc,0xc6,0x54,0x6d,0x12,0x40,0x57,0xa3,0x86,0x32,0xc2,0x7e,0x93,0xbe";
BA_ "GenMsgSendType" BO_ 797 0;
BA_ "VFrameFormat" BO_ 797 14;
BA_ "GenMsgCycleTime" BO_ 2527679498 1000;
BA_ "GenMsgCycleTimeFast" BO_ 2527679498 200;
BA_ "GenMsgDelayTime" BO_ 2527679498 50;
BA_ "GenMsgILSupport" BO_ 2527679498 1;
BA_ "GenMsgNrOfRepetition" BO_ 2527679498 3;
BA_ "GenMsgSendType" BO_ 2527679498 0;
BA_ "VFrameFormat" BO_ 2527679498 15;
BA_ "GenMsgCycleTime" BO_ 1031 100;
BA_ "GenMsgDelayTime" BO_ 1031 50;
BA_ "GenMsgILSupport" BO_ 1031 1;
BA_ "GenMsgPDUConstants" BO_ 1031 "0xef,0x60,0x04,0xa8,0x0c,0x1c,0xda,0x07,0x36,0xd7,0x28,0x92,0xa9,0x88,0x2c,0x4a";
BA_ "GenMsgSendType" BO_ 1031 0;
BA_ "VFrameFormat" BO_ 1031 14;
BA_ "GenMsgCycleTime" BO_ 1122 150;
BA_ "GenMsgILSupport" BO_ 1122 1;
BA_ "GenMsgSendType" BO_ 1122 0;
BA_ "VFrameFormat" BO_ 1122 14;
BA_ "GenMsgCycleTime" BO_ 1123 150;
BA_ "GenMsgILSupport" BO_ 1123 1;
BA_ "GenMsgSendType" BO_ 1123 0;
BA_ "VFrameFormat" BO_ 1123 14;
BA_ "GenMsgCycleTime" BO_ 1124 150;
BA_ "GenMsgILSupport" BO_ 1124 1;
BA_ "GenMsgSendType" BO_ 1124 0;
BA_ "VFrameFormat" BO_ 1124 14;
BA_ "GenMsgCycleTime" BO_ 317 20;
BA_ "GenMsgCycleTimeFast" BO_ 317 10;
BA_ "GenMsgILSupport" BO_ 317 1;
BA_ "GenMsgNrOfRepetition" BO_ 317 5;
BA_ "GenMsgPDUConstants" BO_ 317 "0x18,0x71,0x10,0x8d,0xd7,0xaa,0xb0,0x78,0xac,0x12,0xae,0x0c,0xdd,0xf1,0x85,0x68";
BA_ "GenMsgSendType" BO_ 317 0;
BA_ "VFrameFormat" BO_ 317 14;
BA_ "GenMsgCycleTime" BO_ 591 40;
BA_ "GenMsgILSupport" BO_ 591 1;
BA_ "GenMsgSendType" BO_ 591 0;
BA_ "VFrameFormat" BO_ 591 14;
BA_ "GenSigSendType" SG_ 2331595789 NR_FR_Object_09_10_BlockID_02 0;
BA_ "GenSigSendType" SG_ 2331595789 NR_FR_Object_09_10_BZ 0;
BA_ "GenSigFuncType" SG_ 2331595789 NR_FR_Object_09_10_BZ 1;
BA_ "GenSigSwitchedByIgnition" SG_ 2331595789 NR_FR_Object_09_10_BZ 0;
BA_ "GenSigSendType" SG_ 2331595789 NR_FR_Object_09_10_CRC 0;
BA_ "GenSigFuncType" SG_ 2331595789 NR_FR_Object_09_10_CRC 2;
BA_ "GenSigSwitchedByIgnition" SG_ 2331595789 NR_FR_Object_09_10_CRC 0;
BA_ "GenSigSendType" SG_ 2331595789 NR_FR_Object_09_aAbsX 0;
BA_ "GenSigStartValue" SG_ 2331595789 NR_FR_Object_09_aAbsX 511;
BA_ "GenSigSendType" SG_ 2331595789 NR_FR_Object_09_aAbsXSD 0;
BA_ "GenSigStartValue" SG_ 2331595789 NR_FR_Object_09_aAbsXSD 63;
BA_ "GenSigSendType" SG_ 2331595789 NR_FR_Object_09_aAbsY 0;
BA_ "GenSigStartValue" SG_ 2331595789 NR_FR_Object_09_aAbsY 511;
BA_ "GenSigSendType" SG_ 2331595789 NR_FR_Object_09_aAbsYSD 0;
BA_ "GenSigStartValue" SG_ 2331595789 NR_FR_Object_09_aAbsYSD 63;
BA_ "GenSigSendType" SG_ 2331595789 NR_FR_Object_09_Age 0;
BA_ "GenSigStartValue" SG_ 2331595789 NR_FR_Object_09_Age 127;
BA_ "GenSigSendType" SG_ 2331595789 NR_FR_Object_09_Class 0;
BA_ "GenSigStartValue" SG_ 2331595789 NR_FR_Object_09_Class 15;
BA_ "GenSigSendType" SG_ 2331595789 NR_FR_Object_09_ClassPlausib 0;
BA_ "GenSigStartValue" SG_ 2331595789 NR_FR_Object_09_ClassPlausib 15;
BA_ "GenSigSendType" SG_ 2331595789 NR_FR_Object_09_DynamicState 0;
BA_ "GenSigStartValue" SG_ 2331595789 NR_FR_Object_09_DynamicState 3;
BA_ "GenSigSendType" SG_ 2331595789 NR_FR_Object_09_ExistProb 0;
BA_ "GenSigStartValue" SG_ 2331595789 NR_FR_Object_09_ExistProb 127;
BA_ "GenSigSendType" SG_ 2331595789 NR_FR_Object_09_ID 0;
BA_ "GenSigStartValue" SG_ 2331595789 NR_FR_Object_09_ID 255;
BA_ "GenSigSendType" SG_ 2331595789 NR_FR_Object_09_Length 0;
BA_ "GenSigStartValue" SG_ 2331595789 NR_FR_Object_09_Length 1023;
BA_ "GenSigSendType" SG_ 2331595789 NR_FR_Object_09_LengthSD 0;
BA_ "GenSigStartValue" SG_ 2331595789 NR_FR_Object_09_LengthSD 127;
BA_ "GenSigSendType" SG_ 2331595789 NR_FR_Object_09_MeasurementState 0;
BA_ "GenSigSendType" SG_ 2331595789 NR_FR_Object_09_PosX 0;
BA_ "GenSigStartValue" SG_ 2331595789 NR_FR_Object_09_PosX 16383;
BA_ "GenSigSendType" SG_ 2331595789 NR_FR_Object_09_PosXSD 0;
BA_ "GenSigStartValue" SG_ 2331595789 NR_FR_Object_09_PosXSD 255;
BA_ "GenSigSendType" SG_ 2331595789 NR_FR_Object_09_PosY 0;
BA_ "GenSigStartValue" SG_ 2331595789 NR_FR_Object_09_PosY 8191;
BA_ "GenSigSendType" SG_ 2331595789 NR_FR_Object_09_PosYSD 0;
BA_ "GenSigStartValue" SG_ 2331595789 NR_FR_Object_09_PosYSD 255;
BA_ "GenSigSendType" SG_ 2331595789 NR_FR_Object_09_ReferencePoint 0;
BA_ "GenSigStartValue" SG_ 2331595789 NR_FR_Object_09_ReferencePoint 15;
BA_ "GenSigSendType" SG_ 2331595789 NR_FR_Object_09_vAbsX 0;
BA_ "GenSigStartValue" SG_ 2331595789 NR_FR_Object_09_vAbsX 4095;
BA_ "GenSigSendType" SG_ 2331595789 NR_FR_Object_09_vAbsXSD 0;
BA_ "GenSigStartValue" SG_ 2331595789 NR_FR_Object_09_vAbsXSD 63;
BA_ "GenSigSendType" SG_ 2331595789 NR_FR_Object_09_vAbsY 0;
BA_ "GenSigStartValue" SG_ 2331595789 NR_FR_Object_09_vAbsY 4095;
BA_ "GenSigSendType" SG_ 2331595789 NR_FR_Object_09_vAbsYSD 0;
BA_ "GenSigStartValue" SG_ 2331595789 NR_FR_Object_09_vAbsYSD 63;
BA_ "GenSigSendType" SG_ 2331595789 NR_FR_Object_09_Width 0;
BA_ "GenSigStartValue" SG_ 2331595789 NR_FR_Object_09_Width 255;
BA_ "GenSigSendType" SG_ 2331595789 NR_FR_Object_09_WidthSD 0;
BA_ "GenSigStartValue" SG_ 2331595789 NR_FR_Object_09_WidthSD 127;
BA_ "GenSigSendType" SG_ 2331595789 NR_FR_Object_09_YawAngle 0;
BA_ "GenSigStartValue" SG_ 2331595789 NR_FR_Object_09_YawAngle 4095;
BA_ "GenSigSendType" SG_ 2331595789 NR_FR_Object_09_YawAngleSD 0;
BA_ "GenSigStartValue" SG_ 2331595789 NR_FR_Object_09_YawAngleSD 511;
BA_ "GenSigSendType" SG_ 2331595789 NR_FR_Object_09_YawRateAbs 0;
BA_ "GenSigStartValue" SG_ 2331595789 NR_FR_Object_09_YawRateAbs 4095;
BA_ "GenSigSendType" SG_ 2331595789 NR_FR_Object_09_YawRateAbsSD 0;
BA_ "GenSigStartValue" SG_ 2331595789 NR_FR_Object_09_YawRateAbsSD 63;
BA_ "GenSigSendType" SG_ 2331595789 NR_FR_Object_10_aAbsX 0;
BA_ "GenSigStartValue" SG_ 2331595789 NR_FR_Object_10_aAbsX 511;
BA_ "GenSigSendType" SG_ 2331595789 NR_FR_Object_10_aAbsXSD 0;
BA_ "GenSigStartValue" SG_ 2331595789 NR_FR_Object_10_aAbsXSD 63;
BA_ "GenSigSendType" SG_ 2331595789 NR_FR_Object_10_aAbsY 0;
BA_ "GenSigStartValue" SG_ 2331595789 NR_FR_Object_10_aAbsY 511;
BA_ "GenSigSendType" SG_ 2331595789 NR_FR_Object_10_aAbsYSD 0;
BA_ "GenSigStartValue" SG_ 2331595789 NR_FR_Object_10_aAbsYSD 63;
BA_ "GenSigSendType" SG_ 2331595789 NR_FR_Object_10_Age 0;
BA_ "GenSigStartValue" SG_ 2331595789 NR_FR_Object_10_Age 127;
BA_ "GenSigSendType" SG_ 2331595789 NR_FR_Object_10_Class 0;
BA_ "GenSigStartValue" SG_ 2331595789 NR_FR_Object_10_Class 15;
BA_ "GenSigSendType" SG_ 2331595789 NR_FR_Object_10_ClassPlausib 0;
BA_ "GenSigStartValue" SG_ 2331595789 NR_FR_Object_10_ClassPlausib 15;
BA_ "GenSigSendType" SG_ 2331595789 NR_FR_Object_10_DynamicState 0;
BA_ "GenSigStartValue" SG_ 2331595789 NR_FR_Object_10_DynamicState 3;
BA_ "GenSigSendType" SG_ 2331595789 NR_FR_Object_10_ExistProb 0;
BA_ "GenSigStartValue" SG_ 2331595789 NR_FR_Object_10_ExistProb 127;
BA_ "GenSigSendType" SG_ 2331595789 NR_FR_Object_10_ID 0;
BA_ "GenSigStartValue" SG_ 2331595789 NR_FR_Object_10_ID 255;
BA_ "GenSigSendType" SG_ 2331595789 NR_FR_Object_10_Length 0;
BA_ "GenSigStartValue" SG_ 2331595789 NR_FR_Object_10_Length 1023;
BA_ "GenSigSendType" SG_ 2331595789 NR_FR_Object_10_LengthSD 0;
BA_ "GenSigStartValue" SG_ 2331595789 NR_FR_Object_10_LengthSD 127;
BA_ "GenSigSendType" SG_ 2331595789 NR_FR_Object_10_MeasurementState 0;
BA_ "GenSigSendType" SG_ 2331595789 NR_FR_Object_10_PosX 0;
BA_ "GenSigStartValue" SG_ 2331595789 NR_FR_Object_10_PosX 16383;
BA_ "GenSigSendType" SG_ 2331595789 NR_FR_Object_10_PosXSD 0;
BA_ "GenSigStartValue" SG_ 2331595789 NR_FR_Object_10_PosXSD 255;
BA_ "GenSigSendType" SG_ 2331595789 NR_FR_Object_10_PosY 0;
BA_ "GenSigStartValue" SG_ 2331595789 NR_FR_Object_10_PosY 8191;
BA_ "GenSigSendType" SG_ 2331595789 NR_FR_Object_10_PosYSD 0;
BA_ "GenSigStartValue" SG_ 2331595789 NR_FR_Object_10_PosYSD 255;
BA_ "GenSigSendType" SG_ 2331595789 NR_FR_Object_10_ReferencePoint 0;
BA_ "GenSigStartValue" SG_ 2331595789 NR_FR_Object_10_ReferencePoint 15;
BA_ "GenSigSendType" SG_ 2331595789 NR_FR_Object_10_vAbsX 0;
BA_ "GenSigStartValue" SG_ 2331595789 NR_FR_Object_10_vAbsX 4095;
BA_ "GenSigSendType" SG_ 2331595789 NR_FR_Object_10_vAbsXSD 0;
BA_ "GenSigStartValue" SG_ 2331595789 NR_FR_Object_10_vAbsXSD 63;
BA_ "GenSigSendType" SG_ 2331595789 NR_FR_Object_10_vAbsY 0;
BA_ "GenSigStartValue" SG_ 2331595789 NR_FR_Object_10_vAbsY 4095;
BA_ "GenSigSendType" SG_ 2331595789 NR_FR_Object_10_vAbsYSD 0;
BA_ "GenSigStartValue" SG_ 2331595789 NR_FR_Object_10_vAbsYSD 63;
BA_ "GenSigSendType" SG_ 2331595789 NR_FR_Object_10_Width 0;
BA_ "GenSigStartValue" SG_ 2331595789 NR_FR_Object_10_Width 255;
BA_ "GenSigSendType" SG_ 2331595789 NR_FR_Object_10_WidthSD 0;
BA_ "GenSigStartValue" SG_ 2331595789 NR_FR_Object_10_WidthSD 127;
BA_ "GenSigSendType" SG_ 2331595789 NR_FR_Object_10_YawAngle 0;
BA_ "GenSigStartValue" SG_ 2331595789 NR_FR_Object_10_YawAngle 4095;
BA_ "GenSigSendType" SG_ 2331595789 NR_FR_Object_10_YawAngleSD 0;
BA_ "GenSigStartValue" SG_ 2331595789 NR_FR_Object_10_YawAngleSD 511;
BA_ "GenSigSendType" SG_ 2331595789 NR_FR_Object_10_YawRateAbs 0;
BA_ "GenSigStartValue" SG_ 2331595789 NR_FR_Object_10_YawRateAbs 4095;
BA_ "GenSigSendType" SG_ 2331595789 NR_FR_Object_10_YawRateAbsSD 0;
BA_ "GenSigStartValue" SG_ 2331595789 NR_FR_Object_10_YawRateAbsSD 63;
BA_ "GenSigSendType" SG_ 2331595789 SOK_NR_FR_Object_09_10_Signatur 0;
BA_ "GenSigFuncType" SG_ 2331595789 SOK_NR_FR_Object_09_10_Signatur 15;
BA_ "GenSigSendType" SG_ 2589284097 DS_FR_StructureVersion_1 0;
BA_ "GenSigSwitchedByIgnition" SG_ 2589284097 DS_FR_StructureVersion_1 0;
BA_ "GenSigSendType" SG_ 2589284097 DS_FR_StructureVersion_2 0;
BA_ "GenSigSwitchedByIgnition" SG_ 2589284097 DS_FR_StructureVersion_2 0;
BA_ "GenSigSendType" SG_ 2589284097 NR_FR_HW_Version 0;
BA_ "GenSigSendType" SG_ 2589284097 NR_FR_SerialNumber 0;
BA_ "GenSigSendType" SG_ 2589284097 NR_FR_SW_Version 0;
BA_ "GenSigSendType" SG_ 2331595851 NR_FR_Structure_BlockID_02 0;
BA_ "GenSigSendType" SG_ 2331595851 NR_FR_Structure_right_ExistProb 0;
BA_ "GenSigStartValue" SG_ 2331595851 NR_FR_Structure_right_ExistProb 127;
BA_ "GenSigSendType" SG_ 2331595851 NR_FR_Structure_right_LatDist 0;
BA_ "GenSigStartValue" SG_ 2331595851 NR_FR_Structure_right_LatDist 511;
BA_ "GenSigSendType" SG_ 2331595851 NR_FR_Structure_right_Type 0;
BA_ "GenSigSendType" SG_ 2264486984 NR_FR_EarliestStartTime 0;
BA_ "GenSigSendType" SG_ 2264486984 NR_FR_InteferenceInfo 0;
BA_ "GenSigSendType" SG_ 2264486984 NR_FR_LatestSyncCounter 0;
BA_ "GenSigSendType" SG_ 2264486984 NR_FR_RequestedModulation 0;
BA_ "GenSigSendType" SG_ 2264486984 NR_FR_SyncCycleCount 0;
BA_ "GenSigSendType" SG_ 2264486984 NR_FR_SyncReadyVersion 0;
BA_ "GenSigSendType" SG_ 2621440599 OBDC_ACC_Req_FD_Data 3;
BA_ "GenSigFuncType" SG_ 2621440599 OBDC_ACC_Req_FD_Data 9;
BA_ "GenSigSwitchedByIgnition" SG_ 2621440599 OBDC_ACC_Req_FD_Data 0;
BA_ "GenSigSendType" SG_ 2621571671 OBDC_ACC_Resp_FD_Data 3;
BA_ "GenSigFuncType" SG_ 2621571671 OBDC_ACC_Resp_FD_Data 9;
BA_ "GenSigSwitchedByIgnition" SG_ 2621571671 OBDC_ACC_Resp_FD_Data 0;
BA_ "GenSigSendType" SG_ 2621506048 OBDC_Funktion_Req_All_FD_Data 3;
BA_ "GenSigFuncType" SG_ 2621506048 OBDC_Funktion_Req_All_FD_Data 9;
BA_ "GenSigSwitchedByIgnition" SG_ 2621506048 OBDC_Funktion_Req_All_FD_Data 0;
BA_ "GenSigSendType" SG_ 2621440591 OBDC_Kamera_Req_FD_Data 3;
BA_ "GenSigFuncType" SG_ 2621440591 OBDC_Kamera_Req_FD_Data 9;
BA_ "GenSigSwitchedByIgnition" SG_ 2621440591 OBDC_Kamera_Req_FD_Data 0;
BA_ "GenSigSendType" SG_ 2621571663 OBDC_Kamera_Resp_FD_Data 3;
BA_ "GenSigFuncType" SG_ 2621571663 OBDC_Kamera_Resp_FD_Data 9;
BA_ "GenSigSwitchedByIgnition" SG_ 2621571663 OBDC_Kamera_Resp_FD_Data 0;
BA_ "GenSigSendType" SG_ 2621440699 OBDC_NR_01_Req_FD_Data 3;
BA_ "GenSigFuncType" SG_ 2621440699 OBDC_NR_01_Req_FD_Data 9;
BA_ "GenSigSwitchedByIgnition" SG_ 2621440699 OBDC_NR_01_Req_FD_Data 0;
BA_ "GenSigSendType" SG_ 2621571771 OBDC_NR_01_Resp_FD_Data 3;
BA_ "GenSigFuncType" SG_ 2621571771 OBDC_NR_01_Resp_FD_Data 9;
BA_ "GenSigSwitchedByIgnition" SG_ 2621571771 OBDC_NR_01_Resp_FD_Data 0;
BA_ "GenSigSendType" SG_ 2621440700 OBDC_NR_02_Req_FD_Data 3;
BA_ "GenSigFuncType" SG_ 2621440700 OBDC_NR_02_Req_FD_Data 9;
BA_ "GenSigSwitchedByIgnition" SG_ 2621440700 OBDC_NR_02_Req_FD_Data 0;
BA_ "GenSigSendType" SG_ 2621571772 OBDC_NR_02_Resp_FD_Data 3;
BA_ "GenSigFuncType" SG_ 2621571772 OBDC_NR_02_Resp_FD_Data 9;
BA_ "GenSigSwitchedByIgnition" SG_ 2621571772 OBDC_NR_02_Resp_FD_Data 0;
BA_ "GenSigSendType" SG_ 2564502513 OBDx_allOBD_Req_Data 3;
BA_ "GenSigFuncType" SG_ 2564502513 OBDx_allOBD_Req_Data 9;
BA_ "GenSigSwitchedByIgnition" SG_ 2564502513 OBDx_allOBD_Req_Data 0;
BA_ "GenSigSendType" SG_ 2589284079 FASFrontradar_ORUData 0;
BA_ "GenSigSwitchedByIgnition" SG_ 2589284079 FASFrontradar_ORUData 0;
BA_ "GenSigSendType" SG_ 2589284079 FASFrontradar_ORUDataIndex 0;
BA_ "GenSigSwitchedByIgnition" SG_ 2589284079 FASFrontradar_ORUDataIndex 0;
BA_ "GenSigSendType" SG_ 2589284079 ORU_0013_BZ 0;
BA_ "GenSigFuncType" SG_ 2589284079 ORU_0013_BZ 1;
BA_ "GenSigSwitchedByIgnition" SG_ 2589284079 ORU_0013_BZ 0;
BA_ "GenSigSendType" SG_ 2589284079 ORU_0013_CRC 0;
BA_ "GenSigFuncType" SG_ 2589284079 ORU_0013_CRC 2;
BA_ "GenSigSwitchedByIgnition" SG_ 2589284079 ORU_0013_CRC 0;
BA_ "GenSigSendType" SG_ 2589284120 MFK_ORUData 0;
BA_ "GenSigSwitchedByIgnition" SG_ 2589284120 MFK_ORUData 0;
BA_ "GenSigSendType" SG_ 2589284120 MFK_ORUDataIndex 0;
BA_ "GenSigSwitchedByIgnition" SG_ 2589284120 MFK_ORUDataIndex 0;
BA_ "GenSigSendType" SG_ 2589284120 ORU_00A5_BZ 0;
BA_ "GenSigFuncType" SG_ 2589284120 ORU_00A5_BZ 1;
BA_ "GenSigSwitchedByIgnition" SG_ 2589284120 ORU_00A5_BZ 0;
BA_ "GenSigSendType" SG_ 2589284120 ORU_00A5_CRC 0;
BA_ "GenSigFuncType" SG_ 2589284120 ORU_00A5_CRC 2;
BA_ "GenSigSwitchedByIgnition" SG_ 2589284120 ORU_00A5_CRC 0;
BA_ "GenSigSendType" SG_ 2589283656 ORU_01_BZ 0;
BA_ "GenSigFuncType" SG_ 2589283656 ORU_01_BZ 1;
BA_ "GenSigSwitchedByIgnition" SG_ 2589283656 ORU_01_BZ 0;
BA_ "GenSigSendType" SG_ 2589283656 ORU_01_CRC 0;
BA_ "GenSigFuncType" SG_ 2589283656 ORU_01_CRC 2;
BA_ "GenSigSwitchedByIgnition" SG_ 2589283656 ORU_01_CRC 0;
BA_ "GenSigSendType" SG_ 2589283656 ORU_DiagAddress 0;
BA_ "GenSigSwitchedByIgnition" SG_ 2589283656 ORU_DiagAddress 0;
BA_ "GenSigSendType" SG_ 2589283656 ORU_EM_Anfrage_Flashdauer 3;
BA_ "GenSigSwitchedByIgnition" SG_ 2589283656 ORU_EM_Anfrage_Flashdauer 0;
BA_ "GenSigSendType" SG_ 2589283656 ORU_EM_Anfrage_freigegebeneNetze 3;
BA_ "GenSigSwitchedByIgnition" SG_ 2589283656 ORU_EM_Anfrage_freigegebeneNetze 0;
BA_ "GenSigSendType" SG_ 2589283656 ORU_EM_Anfrage_Stromaufnahme 3;
BA_ "GenSigSwitchedByIgnition" SG_ 2589283656 ORU_EM_Anfrage_Stromaufnahme 0;
BA_ "GenSigSendType" SG_ 2589283656 ORU_Inventory 0;
BA_ "GenSigSwitchedByIgnition" SG_ 2589283656 ORU_Inventory 0;
BA_ "GenSigSendType" SG_ 2589283656 ORU_Status 3;
BA_ "GenSigSwitchedByIgnition" SG_ 2589283656 ORU_Status 0;
BA_ "GenSigSendType" SG_ 2589283656 ORU_Warnung 3;
BA_ "GenSigSwitchedByIgnition" SG_ 2589283656 ORU_Warnung 0;
BA_ "GenSigSendType" SG_ 2589284073 ORUG01_01_BZ 0;
BA_ "GenSigFuncType" SG_ 2589284073 ORUG01_01_BZ 1;
BA_ "GenSigSwitchedByIgnition" SG_ 2589284073 ORUG01_01_BZ 0;
BA_ "GenSigSendType" SG_ 2589284073 ORUG01_01_CRC 0;
BA_ "GenSigFuncType" SG_ 2589284073 ORUG01_01_CRC 2;
BA_ "GenSigSwitchedByIgnition" SG_ 2589284073 ORUG01_01_CRC 0;
BA_ "GenSigSendType" SG_ 2589284073 ORUG1_Anforderung_HMS 0;
BA_ "GenSigSwitchedByIgnition" SG_ 2589284073 ORUG1_Anforderung_HMS 0;
BA_ "GenSigSendType" SG_ 2589284073 ORUG1_HVLock 0;
BA_ "GenSigSwitchedByIgnition" SG_ 2589284073 ORUG1_HVLock 0;
BA_ "GenSigSendType" SG_ 2589284073 ORUG1_HVReleased 0;
BA_ "GenSigSwitchedByIgnition" SG_ 2589284073 ORUG1_HVReleased 0;
BA_ "GenSigSendType" SG_ 2589284073 ORUG1_Parken_beibehalten_HMS 0;
BA_ "GenSigSwitchedByIgnition" SG_ 2589284073 ORUG1_Parken_beibehalten_HMS 0;
BA_ "Fehlerwert" SG_ 2589284073 ORUG1_Parken_beibehalten_HMS 3;
BA_ "GenSigSendType" SG_ 2589284073 ORUG1_TargetRelease 0;
BA_ "GenSigSwitchedByIgnition" SG_ 2589284073 ORUG1_TargetRelease 0;
BA_ "GenSigSendType" SG_ 2589284073 ORUG1_Warning 0;
BA_ "GenSigSwitchedByIgnition" SG_ 2589284073 ORUG1_Warning 0;
BA_ "GenSigSendType" SG_ 2589284074 ORUG02_01_BZ 0;
BA_ "GenSigFuncType" SG_ 2589284074 ORUG02_01_BZ 1;
BA_ "GenSigSwitchedByIgnition" SG_ 2589284074 ORUG02_01_BZ 0;
BA_ "GenSigSendType" SG_ 2589284074 ORUG02_01_CRC 0;
BA_ "GenSigFuncType" SG_ 2589284074 ORUG02_01_CRC 2;
BA_ "GenSigSwitchedByIgnition" SG_ 2589284074 ORUG02_01_CRC 0;
BA_ "GenSigSendType" SG_ 2589284074 ORUG2_GuardInfo 0;
BA_ "GenSigSwitchedByIgnition" SG_ 2589284074 ORUG2_GuardInfo 0;
BA_ "GenSigSendType" SG_ 2589284074 ORUG2_GuardState 0;
BA_ "GenSigSwitchedByIgnition" SG_ 2589284074 ORUG2_GuardState 0;
BA_ "GenSigSendType" SG_ 2589284074 ORUG2_TargetRelease 0;
BA_ "GenSigSwitchedByIgnition" SG_ 2589284074 ORUG2_TargetRelease 0;
BA_ "GenSigSendType" SG_ 2589284074 ORUG2_TorqueLock 0;
BA_ "GenSigSwitchedByIgnition" SG_ 2589284074 ORUG2_TorqueLock 0;
BA_ "GenSigSendType" SG_ 525 PaCo_01_Sendestatus 6;
BA_ "GenSigSwitchedByIgnition" SG_ 525 PaCo_01_Sendestatus 0;
BA_ "GenSigSendType" SG_ 525 PaCo_AAA_Intervention 3;
BA_ "GenSigSwitchedByIgnition" SG_ 525 PaCo_AAA_Intervention 0;
BA_ "GenSigSendType" SG_ 525 PaCo_AAA_TargetState 3;
BA_ "GenSigSwitchedByIgnition" SG_ 525 PaCo_AAA_TargetState 0;
BA_ "GenSigSendType" SG_ 525 PaCo_AEBPR_ImplementationRBFMA 3;
BA_ "GenSigSwitchedByIgnition" SG_ 525 PaCo_AEBPR_ImplementationRBFMA 0;
BA_ "GenSigSendType" SG_ 525 PaCo_AEBPR_InterventionStrategy 3;
BA_ "GenSigSwitchedByIgnition" SG_ 525 PaCo_AEBPR_InterventionStrategy 0;
BA_ "GenSigSendType" SG_ 525 PaCo_APS_AudioLowering 3;
BA_ "GenSigSwitchedByIgnition" SG_ 525 PaCo_APS_AudioLowering 0;
BA_ "GenSigSendType" SG_ 525 PaCo_APS_TargetState 3;
BA_ "GenSigSwitchedByIgnition" SG_ 525 PaCo_APS_TargetState 0;
BA_ "GenSigSendType" SG_ 525 PaCo_APSOPS_DetectionFront 3;
BA_ "GenSigSwitchedByIgnition" SG_ 525 PaCo_APSOPS_DetectionFront 0;
BA_ "GenSigSendType" SG_ 525 PaCo_APSOPS_DetectionRear 3;
BA_ "GenSigSwitchedByIgnition" SG_ 525 PaCo_APSOPS_DetectionRear 0;
BA_ "GenSigSendType" SG_ 525 PaCo_APSOPS_LED 3;
BA_ "GenSigSwitchedByIgnition" SG_ 525 PaCo_APSOPS_LED 0;
BA_ "GenSigSendType" SG_ 525 PaCo_ARA_InterventionStart 3;
BA_ "GenSigSwitchedByIgnition" SG_ 525 PaCo_ARA_InterventionStart 0;
BA_ "GenSigSendType" SG_ 525 PaCo_ARA_TargetState 3;
BA_ "GenSigSwitchedByIgnition" SG_ 525 PaCo_ARA_TargetState 0;
BA_ "GenSigSendType" SG_ 525 PaCo_DiETa_LED 3;
BA_ "GenSigSwitchedByIgnition" SG_ 525 PaCo_DiETa_LED 0;
BA_ "GenSigSendType" SG_ 525 PaCo_MainState 3;
BA_ "GenSigSwitchedByIgnition" SG_ 525 PaCo_MainState 0;
BA_ "Fehlerwert" SG_ 525 PaCo_MainState 7;
BA_ "GenSigSendType" SG_ 525 PaCo_OPS_DrivingTube 3;
BA_ "GenSigSwitchedByIgnition" SG_ 525 PaCo_OPS_DrivingTube 0;
BA_ "GenSigSendType" SG_ 525 PaCo_OPS_TargetState 3;
BA_ "GenSigSwitchedByIgnition" SG_ 525 PaCo_OPS_TargetState 0;
BA_ "GenSigSendType" SG_ 525 PaCo_PLAIPA_InterventionStart 3;
BA_ "GenSigSwitchedByIgnition" SG_ 525 PaCo_PLAIPA_InterventionStart 0;
BA_ "GenSigSendType" SG_ 525 PaCo_PLAIPA_LED 3;
BA_ "GenSigSwitchedByIgnition" SG_ 525 PaCo_PLAIPA_LED 0;
BA_ "GenSigSendType" SG_ 525 PaCo_PLAIPA_PLE 3;
BA_ "GenSigSwitchedByIgnition" SG_ 525 PaCo_PLAIPA_PLE 0;
BA_ "GenSigSendType" SG_ 525 PaCo_PLAIPA_SwitchParkSlot 3;
BA_ "GenSigSwitchedByIgnition" SG_ 525 PaCo_PLAIPA_SwitchParkSlot 0;
BA_ "GenSigSendType" SG_ 525 PaCo_PLAIPA_TargetState 3;
BA_ "GenSigSwitchedByIgnition" SG_ 525 PaCo_PLAIPA_TargetState 0;
BA_ "GenSigSendType" SG_ 525 PaCo_RA_InterventionStart 3;
BA_ "GenSigSwitchedByIgnition" SG_ 525 PaCo_RA_InterventionStart 0;
BA_ "GenSigSendType" SG_ 525 PaCo_RA_Targetstate 3;
BA_ "GenSigSwitchedByIgnition" SG_ 525 PaCo_RA_Targetstate 0;
BA_ "GenSigSendType" SG_ 525 PaCo_RBFMA_ImplementationAEBPR 3;
BA_ "GenSigSwitchedByIgnition" SG_ 525 PaCo_RBFMA_ImplementationAEBPR 0;
BA_ "GenSigSendType" SG_ 525 PaCo_RBFMA_InterventionStrategy 3;
BA_ "GenSigSwitchedByIgnition" SG_ 525 PaCo_RBFMA_InterventionStrategy 0;
BA_ "GenSigSendType" SG_ 525 PaCo_RCTA_InterventionStrategy 3;
BA_ "GenSigSwitchedByIgnition" SG_ 525 PaCo_RCTA_InterventionStrategy 0;
BA_ "GenSigSendType" SG_ 525 PaCo_RCTA_Warning 3;
BA_ "GenSigSwitchedByIgnition" SG_ 525 PaCo_RCTA_Warning 0;
BA_ "GenSigSendType" SG_ 525 PaCo_TPA_TargetState 3;
BA_ "GenSigSwitchedByIgnition" SG_ 525 PaCo_TPA_TargetState 0;
BA_ "GenSigSendType" SG_ 525 PaCo_VPS_DarkenVideo 3;
BA_ "GenSigSwitchedByIgnition" SG_ 525 PaCo_VPS_DarkenVideo 0;
BA_ "GenSigSendType" SG_ 525 PaCo_VPS_LED 3;
BA_ "GenSigSwitchedByIgnition" SG_ 525 PaCo_VPS_LED 0;
BA_ "GenSigSendType" SG_ 525 PaCo_VPS_PLE 3;
BA_ "GenSigSwitchedByIgnition" SG_ 525 PaCo_VPS_PLE 0;
BA_ "GenSigSendType" SG_ 525 PaCo_VPS_TargetBirdview 3;
BA_ "GenSigSwitchedByIgnition" SG_ 525 PaCo_VPS_TargetBirdview 0;
BA_ "GenSigSendType" SG_ 525 PaCo_VPS_TargetBowl 3;
BA_ "GenSigSendType" SG_ 525 PaCo_VPS_TargetCarOverlay 3;
BA_ "GenSigSendType" SG_ 525 PaCo_VPS_TargetGraphicOverlay 3;
BA_ "GenSigSendType" SG_ 525 PaCo_VPS_TargetMode 3;
BA_ "GenSigSwitchedByIgnition" SG_ 525 PaCo_VPS_TargetMode 0;
BA_ "GenSigSendType" SG_ 525 PaCo_VPS_TargetRVCscreen 3;
BA_ "GenSigSwitchedByIgnition" SG_ 525 PaCo_VPS_TargetRVCscreen 0;
BA_ "GenSigSendType" SG_ 525 PaCo_VPS_TargetState 3;
BA_ "GenSigSwitchedByIgnition" SG_ 525 PaCo_VPS_TargetState 0;
BA_ "GenSigSendType" SG_ 525 PaCo_VPS_TargetView 3;
BA_ "GenSigSwitchedByIgnition" SG_ 525 PaCo_VPS_TargetView 0;
BA_ "GenSigSendType" SG_ 518 IPA_TPA_Abbruch 0;
BA_ "GenSigSwitchedByIgnition" SG_ 518 IPA_TPA_Abbruch 0;
BA_ "GenSigSendType" SG_ 518 IPA_TPA_ausgerichtetes_Parken 0;
BA_ "GenSigSwitchedByIgnition" SG_ 518 IPA_TPA_ausgerichtetes_Parken 0;
BA_ "GenSigSendType" SG_ 518 IPA_TPA_Fehler 0;
BA_ "GenSigSwitchedByIgnition" SG_ 518 IPA_TPA_Fehler 0;
BA_ "GenSigSendType" SG_ 518 IPA_TPA_Remote 0;
BA_ "GenSigSwitchedByIgnition" SG_ 518 IPA_TPA_Remote 0;
BA_ "GenSigSendType" SG_ 518 IPA_TPA_Remote_Anf 0;
BA_ "GenSigSwitchedByIgnition" SG_ 518 IPA_TPA_Remote_Anf 0;
BA_ "GenSigSendType" SG_ 518 IPA_TPA_Status 0;
BA_ "GenSigStartValue" SG_ 518 IPA_TPA_Status 1;
BA_ "GenSigSwitchedByIgnition" SG_ 518 IPA_TPA_Status 0;
BA_ "GenSigSendType" SG_ 518 Parken_01_BZ 0;
BA_ "GenSigFuncType" SG_ 518 Parken_01_BZ 1;
BA_ "GenSigSwitchedByIgnition" SG_ 518 Parken_01_BZ 0;
BA_ "GenSigSendType" SG_ 518 Parken_01_CRC 0;
BA_ "GenSigFuncType" SG_ 518 Parken_01_CRC 2;
BA_ "GenSigSwitchedByIgnition" SG_ 518 Parken_01_CRC 0;
BA_ "GenSigSendType" SG_ 518 Parken_aktives_System 0;
BA_ "GenSigSendType" SG_ 518 Parken_Anforderung_HMS 0;
BA_ "GenSigSwitchedByIgnition" SG_ 518 Parken_Anforderung_HMS 0;
BA_ "GenSigSendType" SG_ 518 Parken_Anhalteweg_Anf 0;
BA_ "GenSigStartValue" SG_ 518 Parken_Anhalteweg_Anf 1022;
BA_ "GenSigSwitchedByIgnition" SG_ 518 Parken_Anhalteweg_Anf 0;
BA_ "Fehlerwert" SG_ 518 Parken_Anhalteweg_Anf 1023;
BA_ "GenSigSendType" SG_ 518 Parken_beibehalten 0;
BA_ "GenSigStartValue" SG_ 518 Parken_beibehalten 2;
BA_ "GenSigSwitchedByIgnition" SG_ 518 Parken_beibehalten 0;
BA_ "Fehlerwert" SG_ 518 Parken_beibehalten 3;
BA_ "GenSigSendType" SG_ 518 Parken_BKD_Anf 0;
BA_ "GenSigStartValue" SG_ 518 Parken_BKD_Anf 14;
BA_ "GenSigSwitchedByIgnition" SG_ 518 Parken_BKD_Anf 0;
BA_ "Fehlerwert" SG_ 518 Parken_BKD_Anf 15;
BA_ "GenSigSendType" SG_ 518 Parken_Blinker_li_Anf 0;
BA_ "GenSigSwitchedByIgnition" SG_ 518 Parken_Blinker_li_Anf 0;
BA_ "GenSigSendType" SG_ 518 Parken_Blinker_re_Anf 0;
BA_ "GenSigSwitchedByIgnition" SG_ 518 Parken_Blinker_re_Anf 0;
BA_ "GenSigSendType" SG_ 518 Parken_Bordstein_Winkel 0;
BA_ "GenSigSwitchedByIgnition" SG_ 518 Parken_Bordstein_Winkel 0;
BA_ "GenSigSendType" SG_ 518 Parken_erhoehtes_Moment 0;
BA_ "GenSigSwitchedByIgnition" SG_ 518 Parken_erhoehtes_Moment 0;
BA_ "GenSigSendType" SG_ 518 Parken_Fahrbereitschaft_Anf 0;
BA_ "GenSigSendType" SG_ 518 Parken_Fahrstufenwunsch 0;
BA_ "GenSigSendType" SG_ 518 Parken_max_Beschleunigung 0;
BA_ "GenSigStartValue" SG_ 518 Parken_max_Beschleunigung 122;
BA_ "GenSigSwitchedByIgnition" SG_ 518 Parken_max_Beschleunigung 0;
BA_ "Fehlerwert" SG_ 518 Parken_max_Beschleunigung 127;
BA_ "GenSigSendType" SG_ 518 Parken_max_Geschwindigkeit 0;
BA_ "GenSigStartValue" SG_ 518 Parken_max_Geschwindigkeit 251;
BA_ "GenSigSwitchedByIgnition" SG_ 518 Parken_max_Geschwindigkeit 0;
BA_ "Fehlerwert" SG_ 518 Parken_max_Geschwindigkeit 255;
BA_ "GenSigSendType" SG_ 518 Parken_Motorlauf_Anf 0;
BA_ "GenSigSendType" SG_ 518 Parken_Notstopp_Anf 0;
BA_ "GenSigSwitchedByIgnition" SG_ 518 Parken_Notstopp_Anf 0;
BA_ "GenSigSendType" SG_ 518 Parken_Prefill_Anf 0;
BA_ "GenSigSwitchedByIgnition" SG_ 518 Parken_Prefill_Anf 0;
BA_ "GenSigSendType" SG_ 518 Parken_Schleichfahrt_Anf 0;
BA_ "GenSigSendType" SG_ 518 Parken_Soll_Anhalteweg_Anf 0;
BA_ "GenSigStartValue" SG_ 518 Parken_Soll_Anhalteweg_Anf 1022;
BA_ "GenSigSwitchedByIgnition" SG_ 518 Parken_Soll_Anhalteweg_Anf 0;
BA_ "Fehlerwert" SG_ 518 Parken_Soll_Anhalteweg_Anf 1023;
BA_ "GenSigSendType" SG_ 518 Parken_Sollbeschleunigung 0;
BA_ "GenSigSendType" SG_ 518 Parken_Status_IPA_TSK 0;
BA_ "GenSigStartValue" SG_ 518 Parken_Status_IPA_TSK 1;
BA_ "GenSigSwitchedByIgnition" SG_ 518 Parken_Status_IPA_TSK 0;
BA_ "GenSigSendType" SG_ 518 Parken_Verz_Anf 0;
BA_ "GenSigStartValue" SG_ 518 Parken_Verz_Anf 126;
BA_ "GenSigSwitchedByIgnition" SG_ 518 Parken_Verz_Anf 0;
BA_ "GenSigSendType" SG_ 518 Parken_Verz_Anf_ASIL 0;
BA_ "GenSigSwitchedByIgnition" SG_ 518 Parken_Verz_Anf_ASIL 0;
BA_ "GenSigSendType" SG_ 518 Parken_Warnruck_Anf 0;
BA_ "GenSigSwitchedByIgnition" SG_ 518 Parken_Warnruck_Anf 0;
BA_ "GenSigSendType" SG_ 518 Parken_Warnruckeln_Anf 0;
BA_ "GenSigSwitchedByIgnition" SG_ 518 Parken_Warnruckeln_Anf 0;
BA_ "GenSigSendType" SG_ 796 PCS_Li_BlockID 0;
BA_ "GenSigSendType" SG_ 796 PCS_Li_CS 0;
BA_ "GenSigStartValue" SG_ 796 PCS_Li_CS 126;
BA_ "Fehlerwert" SG_ 796 PCS_Li_CS 127;
BA_ "GenSigSendType" SG_ 796 PCS_Li_CW 0;
BA_ "GenSigStartValue" SG_ 796 PCS_Li_CW 126;
BA_ "Fehlerwert" SG_ 796 PCS_Li_CW 127;
BA_ "GenSigSendType" SG_ 796 PCS_Li_MessZeitpunkt 0;
BA_ "GenSigStartValue" SG_ 796 PCS_Li_MessZeitpunkt 8191;
BA_ "GenSigSendType" SG_ 796 PCS_Li_Status 0;
BA_ "Fehlerwert" SG_ 796 PCS_Li_Status 15;
BA_ "GenSigSendType" SG_ 796 PCS_Li_TTC 0;
BA_ "GenSigStartValue" SG_ 796 PCS_Li_TTC 1022;
BA_ "Fehlerwert" SG_ 796 PCS_Li_TTC 1023;
BA_ "GenSigSendType" SG_ 797 PCS_Re_BlockID 0;
BA_ "GenSigSendType" SG_ 797 PCS_Re_CS 0;
BA_ "GenSigStartValue" SG_ 797 PCS_Re_CS 126;
BA_ "Fehlerwert" SG_ 797 PCS_Re_CS 127;
BA_ "GenSigSendType" SG_ 797 PCS_Re_CW 0;
BA_ "GenSigStartValue" SG_ 797 PCS_Re_CW 126;
BA_ "Fehlerwert" SG_ 797 PCS_Re_CW 127;
BA_ "GenSigSendType" SG_ 797 PCS_Re_MessZeitpunkt 0;
BA_ "GenSigStartValue" SG_ 797 PCS_Re_MessZeitpunkt 8191;
BA_ "GenSigSendType" SG_ 797 PCS_Re_Status 0;
BA_ "Fehlerwert" SG_ 797 PCS_Re_Status 15;
BA_ "GenSigSendType" SG_ 797 PCS_Re_TTC 0;
BA_ "GenSigStartValue" SG_ 797 PCS_Re_TTC 1022;
BA_ "Fehlerwert" SG_ 797 PCS_Re_TTC 1023;
BA_ "GenSigSendType" SG_ 2527679498 IAA_Active_User_ID 4;
BA_ "GenSigSwitchedByIgnition" SG_ 2527679498 IAA_Active_User_ID 0;
BA_ "GenSigSendType" SG_ 2527679498 IAA_Identified_User_ID 4;
BA_ "GenSigSwitchedByIgnition" SG_ 2527679498 IAA_Identified_User_ID 0;
BA_ "GenSigSendType" SG_ 2527679498 IAA_PSO_wake_up 4;
BA_ "GenSigSwitchedByIgnition" SG_ 2527679498 IAA_PSO_wake_up 0;
BA_ "GenSigSendType" SG_ 2527679498 Perso_Aktiv 4;
BA_ "GenSigSwitchedByIgnition" SG_ 2527679498 Perso_Aktiv 0;
BA_ "GenSigSendType" SG_ 2527679498 Perso_Bedienstelle 4;
BA_ "GenSigSwitchedByIgnition" SG_ 2527679498 Perso_Bedienstelle 0;
BA_ "GenSigSendType" SG_ 2527679498 Perso_Fahrernummer 4;
BA_ "GenSigSwitchedByIgnition" SG_ 2527679498 Perso_Fahrernummer 0;
BA_ "GenSigSendType" SG_ 2527679498 Perso_Freigabe_Verstellung 4;
BA_ "GenSigSwitchedByIgnition" SG_ 2527679498 Perso_Freigabe_Verstellung 0;
BA_ "GenSigSendType" SG_ 2527679498 Perso_Kontonummer 4;
BA_ "GenSigSwitchedByIgnition" SG_ 2527679498 Perso_Kontonummer 0;
BA_ "GenSigSendType" SG_ 2527679498 Perso_Schreibschutz 4;
BA_ "GenSigSwitchedByIgnition" SG_ 2527679498 Perso_Schreibschutz 0;
BA_ "GenSigSendType" SG_ 2527679498 Perso_Status 1;
BA_ "GenSigSwitchedByIgnition" SG_ 2527679498 Perso_Status 0;
BA_ "GenSigSendType" SG_ 2527679498 Perso_Steuerung 4;
BA_ "GenSigSwitchedByIgnition" SG_ 2527679498 Perso_Steuerung 0;
BA_ "GenSigSendType" SG_ 2527679498 Perso_Steuerungsparameter 4;
BA_ "GenSigSwitchedByIgnition" SG_ 2527679498 Perso_Steuerungsparameter 0;
BA_ "GenSigSendType" SG_ 1031 PLA_04_BZ 0;
BA_ "GenSigFuncType" SG_ 1031 PLA_04_BZ 1;
BA_ "GenSigSwitchedByIgnition" SG_ 1031 PLA_04_BZ 0;
BA_ "GenSigSendType" SG_ 1031 PLA_04_CRC 0;
BA_ "GenSigFuncType" SG_ 1031 PLA_04_CRC 2;
BA_ "GenSigSwitchedByIgnition" SG_ 1031 PLA_04_CRC 0;
BA_ "GenSigSendType" SG_ 1031 PLAIPA_PaCo_Button 0;
BA_ "GenSigSwitchedByIgnition" SG_ 1031 PLAIPA_PaCo_Button 0;
BA_ "GenSigSendType" SG_ 1031 PLAIPA_PaCo_FunctionState 0;
BA_ "GenSigStartValue" SG_ 1031 PLAIPA_PaCo_FunctionState 1;
BA_ "GenSigSwitchedByIgnition" SG_ 1031 PLAIPA_PaCo_FunctionState 0;
BA_ "GenSigSendType" SG_ 1031 PLAIPA_PaCo_GarageActivatable 0;
BA_ "GenSigSwitchedByIgnition" SG_ 1031 PLAIPA_PaCo_GarageActivatable 0;
BA_ "GenSigSendType" SG_ 1031 PLAIPA_PaCo_InterventionPossible 0;
BA_ "GenSigSwitchedByIgnition" SG_ 1031 PLAIPA_PaCo_InterventionPossible 0;
BA_ "GenSigSendType" SG_ 1031 PLAIPA_PaCo_MainState 0;
BA_ "GenSigSwitchedByIgnition" SG_ 1031 PLAIPA_PaCo_MainState 0;
BA_ "Fehlerwert" SG_ 1031 PLAIPA_PaCo_MainState 7;
BA_ "GenSigSendType" SG_ 1031 PLAIPA_PaCo_ParkingSlots 0;
BA_ "GenSigSwitchedByIgnition" SG_ 1031 PLAIPA_PaCo_ParkingSlots 0;
BA_ "GenSigSendType" SG_ 1031 PLAIPA_PaCo_ParkingSlots_02 0;
BA_ "GenSigSwitchedByIgnition" SG_ 1031 PLAIPA_PaCo_ParkingSlots_02 0;
BA_ "GenSigSendType" SG_ 1031 PLAIPA_PaCo_PLEPossible 0;
BA_ "GenSigSwitchedByIgnition" SG_ 1031 PLAIPA_PaCo_PLEPossible 0;
BA_ "GenSigSendType" SG_ 1031 PLAIPA_PaCo_RemoteActivatable 0;
BA_ "GenSigSwitchedByIgnition" SG_ 1031 PLAIPA_PaCo_RemoteActivatable 0;
BA_ "GenSigSendType" SG_ 1031 PLAIPA_PaCo_SwitchPossible 0;
BA_ "GenSigSwitchedByIgnition" SG_ 1031 PLAIPA_PaCo_SwitchPossible 0;
BA_ "GenSigSendType" SG_ 1031 PLAIPA_PaCo_UnavailableReason 0;
BA_ "GenSigSwitchedByIgnition" SG_ 1031 PLAIPA_PaCo_UnavailableReason 0;
BA_ "GenSigSendType" SG_ 1031 RA_PaCo_FunctionState 0;
BA_ "GenSigStartValue" SG_ 1031 RA_PaCo_FunctionState 7;
BA_ "GenSigSwitchedByIgnition" SG_ 1031 RA_PaCo_FunctionState 0;
BA_ "GenSigSendType" SG_ 1031 RA_PaCo_InterventionPossible 0;
BA_ "GenSigSwitchedByIgnition" SG_ 1031 RA_PaCo_InterventionPossible 0;
BA_ "GenSigSendType" SG_ 1031 RA_PaCo_MainState 0;
BA_ "GenSigSwitchedByIgnition" SG_ 1031 RA_PaCo_MainState 0;
BA_ "Fehlerwert" SG_ 1031 RA_PaCo_MainState 2;
BA_ "GenSigSendType" SG_ 1031 RA_PaCo_UnavailableReason 0;
BA_ "GenSigSwitchedByIgnition" SG_ 1031 RA_PaCo_UnavailableReason 0;
BA_ "GenSigSendType" SG_ 1031 RA_PaCo_USSensorStatus 3;
BA_ "GenSigSwitchedByIgnition" SG_ 1031 RA_PaCo_USSensorStatus 0;
BA_ "GenSigSendType" SG_ 1031 RPA_Anf_Sonder_Funktion_Status 0;
BA_ "GenSigSwitchedByIgnition" SG_ 1031 RPA_Anf_Sonder_Funktion_Status 0;
BA_ "GenSigSendType" SG_ 1031 RPA_Anf_Sonder_Klemme_15 0;
BA_ "GenSigSwitchedByIgnition" SG_ 1031 RPA_Anf_Sonder_Klemme_15 0;
BA_ "GenSigSendType" SG_ 1031 RPA_Anf_WFS_Freigabe 0;
BA_ "GenSigSwitchedByIgnition" SG_ 1031 RPA_Anf_WFS_Freigabe 0;
BA_ "GenSigSendType" SG_ 1122 PSD_Abzweigerichtung 0;
BA_ "GenSigSwitchedByIgnition" SG_ 1122 PSD_Abzweigerichtung 0;
BA_ "GenSigSendType" SG_ 1122 PSD_Abzweigewinkel 0;
BA_ "GenSigSwitchedByIgnition" SG_ 1122 PSD_Abzweigewinkel 0;
BA_ "GenSigSendType" SG_ 1122 PSD_ADAS_Qualitaet 0;
BA_ "GenSigSendType" SG_ 1122 PSD_Anfangskruemmung 0;
BA_ "GenSigSwitchedByIgnition" SG_ 1122 PSD_Anfangskruemmung 0;
BA_ "GenSigSendType" SG_ 1122 PSD_Anfangskruemmung_Vorz 0;
BA_ "GenSigSwitchedByIgnition" SG_ 1122 PSD_Anfangskruemmung_Vorz 0;
BA_ "GenSigSendType" SG_ 1122 PSD_Bebauung 0;
BA_ "GenSigSendType" SG_ 1122 PSD_Endkruemmung 0;
BA_ "GenSigSendType" SG_ 1122 PSD_Endkruemmung_Vorz 0;
BA_ "GenSigSendType" SG_ 1122 PSD_Fahrspuren_Anzahl 0;
BA_ "GenSigStartValue" SG_ 1122 PSD_Fahrspuren_Anzahl 1;
BA_ "GenSigSwitchedByIgnition" SG_ 1122 PSD_Fahrspuren_Anzahl 0;
BA_ "GenSigSendType" SG_ 1122 PSD_Geradester_Pfad 0;
BA_ "GenSigSendType" SG_ 1122 PSD_Idenditaets_ID 0;
BA_ "Fehlerwert" SG_ 1122 PSD_Idenditaets_ID 1;
BA_ "GenSigSendType" SG_ 1122 PSD_Rampe 0;
BA_ "GenSigSendType" SG_ 1122 PSD_Segment_ID 0;
BA_ "GenSigSendType" SG_ 1122 PSD_Segment_Komplett 0;
BA_ "GenSigSwitchedByIgnition" SG_ 1122 PSD_Segment_Komplett 0;
BA_ "GenSigSendType" SG_ 1122 PSD_Segmentlaenge 0;
BA_ "GenSigSendType" SG_ 1122 PSD_Strassenkategorie 0;
BA_ "GenSigStartValue" SG_ 1122 PSD_Strassenkategorie 7;
BA_ "GenSigSwitchedByIgnition" SG_ 1122 PSD_Strassenkategorie 0;
BA_ "GenSigSendType" SG_ 1122 PSD_Vorgaenger_Segment_ID 0;
BA_ "GenSigSendType" SG_ 1122 PSD_wahrscheinlichster_Pfad 0;
BA_ "GenSigSendType" SG_ 1123 PSD_Attribut_1_ID 0;
BA_ "GenSigSendType" SG_ 1123 PSD_Attribut_1_Offset 0;
BA_ "GenSigSendType" SG_ 1123 PSD_Attribut_1_Wert 0;
BA_ "GenSigSendType" SG_ 1123 PSD_Attribut_2_ID 0;
BA_ "GenSigSendType" SG_ 1123 PSD_Attribut_2_Offset 0;
BA_ "GenSigSendType" SG_ 1123 PSD_Attribut_2_Wert 0;
BA_ "GenSigSendType" SG_ 1123 PSD_Attribut_Segment_ID_05 0;
BA_ "Fehlerwert" SG_ 1123 PSD_Attribut_Segment_ID_05 1;
BA_ "GenSigSendType" SG_ 1123 PSD_Attribute_Komplett_05 0;
BA_ "GenSigSendType" SG_ 1123 PSD_Pos_Fahrspur 0;
BA_ "GenSigSendType" SG_ 1123 PSD_Pos_Fehler_Laengsrichtung 0;
BA_ "GenSigSendType" SG_ 1123 PSD_Pos_Inhibitzeit 0;
BA_ "GenSigSendType" SG_ 1123 PSD_Pos_Segment_ID 0;
BA_ "GenSigSendType" SG_ 1123 PSD_Pos_Segmentlaenge 0;
BA_ "GenSigSendType" SG_ 1123 PSD_Pos_Standort_Eindeutig 0;
BA_ "GenSigSwitchedByIgnition" SG_ 1123 PSD_Pos_Standort_Eindeutig 0;
BA_ "GenSigSendType" SG_ 1124 PSD_06_Mux 0;
BA_ "NWM-WakeupAllowed" SG_ 1124 PSD_06_Mux 1;
BA_ "GenSigSwitchedByIgnition" SG_ 1124 PSD_06_Mux 0;
BA_ "Fehlerwert" SG_ 1124 PSD_Attribut_Segment_ID 1;
BA_ "GenSigSwitchedByIgnition" SG_ 1124 PSD_Attribute_Komplett_06 0;
BA_ "GenSigStartValue" SG_ 1124 PSD_Ges_Typ 3;
BA_ "GenSigSwitchedByIgnition" SG_ 1124 PSD_Ges_Typ 0;
BA_ "GenSigSwitchedByIgnition" SG_ 1124 PSD_Steigung_1_Attribute_kompl 0;
BA_ "Fehlerwert" SG_ 1124 PSD_Steigung_1_Segment_ID 1;
BA_ "GenSigSwitchedByIgnition" SG_ 1124 PSD_Steigung_2_Attribute_kompl 0;
BA_ "Fehlerwert" SG_ 1124 PSD_Steigung_2_Segment_ID 1;
BA_ "GenSigSendType" SG_ 317 QFK_01_BZ 0;
BA_ "GenSigFuncType" SG_ 317 QFK_01_BZ 1;
BA_ "GenSigSwitchedByIgnition" SG_ 317 QFK_01_BZ 0;
BA_ "GenSigSendType" SG_ 317 QFK_01_CRC 0;
BA_ "GenSigFuncType" SG_ 317 QFK_01_CRC 2;
BA_ "GenSigSwitchedByIgnition" SG_ 317 QFK_01_CRC 0;
BA_ "GenSigSendType" SG_ 317 QFK_01_Sendestatus 6;
BA_ "GenSigSwitchedByIgnition" SG_ 317 QFK_01_Sendestatus 0;
BA_ "GenSigSendType" SG_ 317 QFK_Anf_Giermomoffset 0;
BA_ "GenSigSwitchedByIgnition" SG_ 317 QFK_Anf_Giermomoffset 0;
BA_ "GenSigSendType" SG_ 317 QFK_Anf_Giermomoffset_VZ 0;
BA_ "GenSigSwitchedByIgnition" SG_ 317 QFK_Anf_Giermomoffset_VZ 0;
BA_ "GenSigSendType" SG_ 317 QFK_DynBegr_aktiv 0;
BA_ "GenSigSwitchedByIgnition" SG_ 317 QFK_DynBegr_aktiv 0;
BA_ "GenSigSendType" SG_ 317 QFK_IstKraft 0;
BA_ "GenSigStartValue" SG_ 317 QFK_IstKraft 1022;
BA_ "GenSigSwitchedByIgnition" SG_ 317 QFK_IstKraft 0;
BA_ "Fehlerwert" SG_ 317 QFK_IstKraft 1023;
BA_ "GenSigSendType" SG_ 317 QFK_IstKraft_VZ 0;
BA_ "GenSigSwitchedByIgnition" SG_ 317 QFK_IstKraft_VZ 0;
BA_ "GenSigSendType" SG_ 317 QFK_IstKraftNiveau 0;
BA_ "GenSigSwitchedByIgnition" SG_ 317 QFK_IstKraftNiveau 0;
BA_ "GenSigSendType" SG_ 317 QFK_IstKraftNiveau_VZ 0;
BA_ "GenSigSwitchedByIgnition" SG_ 317 QFK_IstKraftNiveau_VZ 0;
BA_ "GenSigSendType" SG_ 317 QFK_KrIst 0;
BA_ "GenSigStartValue" SG_ 317 QFK_KrIst 65534;
BA_ "GenSigSwitchedByIgnition" SG_ 317 QFK_KrIst 0;
BA_ "Fehlerwert" SG_ 317 QFK_KrIst 65535;
BA_ "GenSigSendType" SG_ 317 QFK_KrIst_VZ 0;
BA_ "GenSigSwitchedByIgnition" SG_ 317 QFK_KrIst_VZ 0;
BA_ "GenSigSendType" SG_ 317 QFK_KruemmIst 0;
BA_ "GenSigSwitchedByIgnition" SG_ 317 QFK_KruemmIst 0;
BA_ "GenSigSendType" SG_ 317 QFK_KruemmIst_VZ 0;
BA_ "GenSigSwitchedByIgnition" SG_ 317 QFK_KruemmIst_VZ 0;
BA_ "GenSigSendType" SG_ 317 QFK_Status 0;
BA_ "GenSigStartValue" SG_ 317 QFK_Status 1;
BA_ "GenSigSwitchedByIgnition" SG_ 317 QFK_Status 0;
BA_ "GenSigSendType" SG_ 317 QFK_stAWV 0;
BA_ "GenSigStartValue" SG_ 317 QFK_stAWV 1;
BA_ "GenSigSwitchedByIgnition" SG_ 317 QFK_stAWV 0;
BA_ "GenSigSendType" SG_ 317 QFK_stDSR 0;
BA_ "GenSigStartValue" SG_ 317 QFK_stDSR 1;
BA_ "GenSigSwitchedByIgnition" SG_ 317 QFK_stDSR 0;
BA_ "GenSigSendType" SG_ 317 QFK_stEingriffBr 0;
BA_ "GenSigSwitchedByIgnition" SG_ 317 QFK_stEingriffBr 0;
BA_ "GenSigSendType" SG_ 317 QFK_stHCA 0;
BA_ "GenSigStartValue" SG_ 317 QFK_stHCA 1;
BA_ "GenSigSendType" SG_ 317 QFK_stMA 0;
BA_ "GenSigStartValue" SG_ 317 QFK_stMA 1;
BA_ "GenSigSendType" SG_ 317 QFK_stPLA 0;
BA_ "GenSigStartValue" SG_ 317 QFK_stPLA 1;
BA_ "GenSigSwitchedByIgnition" SG_ 317 QFK_stPLA 0;
BA_ "GenSigSendType" SG_ 317 QFK_ZPosIst 0;
BA_ "GenSigStartValue" SG_ 317 QFK_ZPosIst 65535;
BA_ "GenSigSwitchedByIgnition" SG_ 317 QFK_ZPosIst 0;
BA_ "GenSigSendType" SG_ 317 QFK_ZPosIst_VZ 0;
BA_ "GenSigSendType" SG_ 317 SOK_QFK_01_Signatur 0;
BA_ "GenSigFuncType" SG_ 317 SOK_QFK_01_Signatur 15;
BA_ "GenSigSendType" SG_ 591 RDR1_Blindheit_erkannt 0;
BA_ "GenSigSendType" SG_ 591 RDR1_Obj_01_ax_StdA 0;
BA_ "GenSigStartValue" SG_ 591 RDR1_Obj_01_ax_StdA 63;
BA_ "GenSigSwitchedByIgnition" SG_ 591 RDR1_Obj_01_ax_StdA 0;
BA_ "GenSigSendType" SG_ 591 RDR1_Obj_01_ax_v 0;
BA_ "GenSigStartValue" SG_ 591 RDR1_Obj_01_ax_v 255;
BA_ "GenSigSwitchedByIgnition" SG_ 591 RDR1_Obj_01_ax_v 0;
BA_ "GenSigSendType" SG_ 591 RDR1_Obj_01_dx_StdA 0;
BA_ "GenSigStartValue" SG_ 591 RDR1_Obj_01_dx_StdA 127;
BA_ "GenSigSwitchedByIgnition" SG_ 591 RDR1_Obj_01_dx_StdA 0;
BA_ "GenSigSendType" SG_ 591 RDR1_Obj_01_dx_v 0;
BA_ "GenSigSendType" SG_ 591 RDR1_Obj_01_dy_StdA 0;
BA_ "GenSigStartValue" SG_ 591 RDR1_Obj_01_dy_StdA 127;
BA_ "GenSigSendType" SG_ 591 RDR1_Obj_01_dy_v 0;
BA_ "GenSigStartValue" SG_ 591 RDR1_Obj_01_dy_v 512;
BA_ "GenSigSendType" SG_ 591 RDR1_Obj_01_Nummer 0;
BA_ "GenSigSendType" SG_ 591 RDR1_Obj_01_vx_StdA 0;
BA_ "GenSigStartValue" SG_ 591 RDR1_Obj_01_vx_StdA 127;
BA_ "GenSigSwitchedByIgnition" SG_ 591 RDR1_Obj_01_vx_StdA 0;
BA_ "GenSigSendType" SG_ 591 RDR1_Obj_01_vx_v 0;
BA_ "GenSigStartValue" SG_ 591 RDR1_Obj_01_vx_v 512;
BA_ "GenSigSendType" SG_ 591 RDR1_Obj_02_dx_v 0;
BA_ "GenSigSendType" SG_ 591 RDR1_Obj_02_dy_v 0;
BA_ "GenSigStartValue" SG_ 591 RDR1_Obj_02_dy_v 512;
BA_ "GenSigSendType" SG_ 591 RDR1_Obj_02_Nummer 0;
BA_ "GenSigSendType" SG_ 591 RDR1_Obj_02_vx_v 0;
BA_ "GenSigStartValue" SG_ 591 RDR1_Obj_02_vx_v 512;
BA_ "GenSigSendType" SG_ 591 RDR1_Obj_03_dx_v 0;
BA_ "GenSigSendType" SG_ 591 RDR1_Obj_03_dy_v 0;
BA_ "GenSigStartValue" SG_ 591 RDR1_Obj_03_dy_v 512;
BA_ "GenSigSendType" SG_ 591 RDR1_Obj_03_Nummer 0;
BA_ "GenSigSendType" SG_ 591 RDR1_Obj_03_vx_v 0;
BA_ "GenSigStartValue" SG_ 591 RDR1_Obj_03_vx_v 512;
BA_ "GenSigSendType" SG_ 591 RDR1_Obj_04_dx_v 0;
BA_ "GenSigSendType" SG_ 591 RDR1_Obj_04_dy_v 0;
BA_ "GenSigStartValue" SG_ 591 RDR1_Obj_04_dy_v 512;
BA_ "GenSigSendType" SG_ 591 RDR1_Obj_04_Nummer 0;
BA_ "GenSigSendType" SG_ 591 RDR1_Obj_04_vx_v 0;
BA_ "GenSigStartValue" SG_ 591 RDR1_Obj_04_vx_v 512;
BA_ "GenSigSendType" SG_ 591 RDR1_Obj_05_dx_v 0;
BA_ "GenSigSendType" SG_ 591 RDR1_Obj_05_dy_v 0;
BA_ "GenSigStartValue" SG_ 591 RDR1_Obj_05_dy_v 512;
BA_ "GenSigSendType" SG_ 591 RDR1_Obj_05_Nummer 0;
BA_ "GenSigSendType" SG_ 591 RDR1_Obj_05_vx_v 0;
BA_ "GenSigStartValue" SG_ 591 RDR1_Obj_05_vx_v 512;
BA_ "GenSigSendType" SG_ 591 RDR1_Obj_06_dx_v 0;
BA_ "GenSigSendType" SG_ 591 RDR1_Obj_06_dy_v 0;
BA_ "GenSigStartValue" SG_ 591 RDR1_Obj_06_dy_v 512;
BA_ "GenSigSendType" SG_ 591 RDR1_Obj_06_Nummer 0;
BA_ "GenSigSendType" SG_ 591 RDR1_Obj_06_vx_v 0;
BA_ "GenSigStartValue" SG_ 591 RDR1_Obj_06_vx_v 512;
BA_ "GenSigSendType" SG_ 591 RDR1_Objekte_02_Datenalter 0;
BA_ "GenSigSendType" SG_ 591 RDR1_relev_Nichtverfuegbarkeit 0;
BA_ "GenSigSendType" SG_ 591 RDR1_relevanter_Fehler 0;
BA_ "GenSigSendType" SG_ 591 RDR1_Verkehrssinn 0;
BA_REL_ "GenSigTimeoutTime" BU_SG_REL_ FASFrontradar SG_ 2589283656 ORU_Status 5000;
BA_REL_ "GenSigTimeoutTime" BU_SG_REL_ FASFrontradar SG_ 2589284073 ORUG01_01_CRC 5000;
BA_REL_ "GenSigTimeoutTime" BU_SG_REL_ FASFrontradar SG_ 2589284073 ORUG01_01_BZ 5000;
BA_REL_ "GenSigTimeoutTime" BU_SG_REL_ FASFrontradar SG_ 2589284073 ORUG1_TargetRelease 5000;
BA_REL_ "GenSigTimeoutTime" BU_SG_REL_ FASFrontradar SG_ 2589284074 ORUG02_01_CRC 5000;
BA_REL_ "GenSigTimeoutTime" BU_SG_REL_ FASFrontradar SG_ 2589284074 ORUG02_01_BZ 5000;
BA_REL_ "GenSigTimeoutTime" BU_SG_REL_ FASFrontradar SG_ 2589284074 ORUG2_TargetRelease 5000;
BA_REL_ "GenSigTimeoutTime" BU_SG_REL_ FASFrontradar SG_ 2527679498 Perso_Kontonummer 5000;
BA_REL_ "GenSigTimeoutTime" BU_SG_REL_ FASFrontradar SG_ 2527679498 Perso_Steuerung 5000;
BA_REL_ "GenSigTimeoutTime" BU_SG_REL_ FASFrontradar SG_ 2527679498 Perso_Steuerungsparameter 5000;
BA_REL_ "GenSigTimeoutTime" BU_SG_REL_ FASFrontradar SG_ 2527679498 Perso_Status 5000;
BA_REL_ "GenSigTimeoutTime" BU_SG_REL_ FASFrontradar SG_ 2527679498 Perso_Bedienstelle 5000;
BA_REL_ "GenSigTimeoutTime" BU_SG_REL_ FASFrontradar SG_ 2527679498 Perso_Freigabe_Verstellung 5000;
BA_REL_ "GenSigTimeoutTime" BU_SG_REL_ FASFrontradar SG_ 2527679498 Perso_Aktiv 5000;
BA_REL_ "GenSigTimeoutTime" BU_SG_REL_ FASFrontradar SG_ 2527679498 Perso_Fahrernummer 5000;
BA_REL_ "GenSigTimeoutTime" BU_SG_REL_ FASFrontradar SG_ 2527679498 Perso_Schreibschutz 5000;
BA_REL_ "GenSigTimeoutTime" BU_SG_REL_ FASFrontradar SG_ 1031 PLAIPA_PaCo_FunctionState 1000;
BA_REL_ "GenSigTimeoutTime" BU_SG_REL_ FASFrontradar SG_ 317 QFK_DynBegr_aktiv 500;
BA_REL_ "GenSigTimeoutTime" BU_SG_REL_ FASFrontradar SG_ 317 QFK_Status 500;
BA_REL_ "GenSigTimeoutTime" BU_SG_REL_ FASFrontradar SG_ 317 QFK_stAWV 500;
BA_REL_ "GenSigTimeoutTime" BU_SG_REL_ FASFrontradar SG_ 317 QFK_stDSR 500;
BA_REL_ "GenSigTimeoutTime" BU_SG_REL_ FASFrontradar SG_ 317 QFK_KruemmIst 500;
BA_REL_ "GenSigTimeoutTime" BU_SG_REL_ FASFrontradar SG_ 317 QFK_KruemmIst_VZ 500;
BA_REL_ "GenSigTimeoutTime" BU_SG_REL_ ICAS1_X_Gateway SG_ 2589284079 ORU_0013_CRC 5000;
BA_REL_ "GenSigTimeoutTime" BU_SG_REL_ ICAS1_X_Gateway SG_ 2589284079 ORU_0013_BZ 5000;
BA_REL_ "GenSigTimeoutTime" BU_SG_REL_ ICAS1_X_Gateway SG_ 2589284079 FASFrontradar_ORUDataIndex 5000;
BA_REL_ "GenSigTimeoutTime" BU_SG_REL_ ICAS1_X_Gateway SG_ 2589284079 FASFrontradar_ORUData 5000;
BA_REL_ "GenSigTimeoutTime" BU_SG_REL_ ICAS1_X_Gateway SG_ 2589284120 ORU_00A5_CRC 5000;
BA_REL_ "GenSigTimeoutTime" BU_SG_REL_ ICAS1_X_Gateway SG_ 2589284120 ORU_00A5_BZ 5000;
BA_REL_ "GenSigTimeoutTime" BU_SG_REL_ ICAS1_X_Gateway SG_ 2589284120 MFK_ORUDataIndex 5000;
BA_REL_ "GenSigTimeoutTime" BU_SG_REL_ ICAS1_X_Gateway SG_ 2589284120 MFK_ORUData 5000;
BA_REL_ "GenSigTimeoutTime" BU_SG_REL_ MFK SG_ 2589283656 ORU_Warnung 5000;
BA_REL_ "GenSigTimeoutTime" BU_SG_REL_ MFK SG_ 2589283656 ORU_Status 5000;
BA_REL_ "GenSigTimeoutTime" BU_SG_REL_ MFK SG_ 2589284073 ORUG01_01_CRC 5000;
BA_REL_ "GenSigTimeoutTime" BU_SG_REL_ MFK SG_ 2589284073 ORUG01_01_BZ 5000;
BA_REL_ "GenSigTimeoutTime" BU_SG_REL_ MFK SG_ 2589284073 ORUG1_TargetRelease 5000;
BA_REL_ "GenSigTimeoutTime" BU_SG_REL_ MFK SG_ 2589284074 ORUG02_01_CRC 5000;
BA_REL_ "GenSigTimeoutTime" BU_SG_REL_ MFK SG_ 2589284074 ORUG02_01_BZ 5000;
BA_REL_ "GenSigTimeoutTime" BU_SG_REL_ MFK SG_ 2589284074 ORUG2_TargetRelease 5000;
BA_REL_ "GenSigTimeoutTime" BU_SG_REL_ MFK SG_ 525 PaCo_01_Sendestatus 5000;
BA_REL_ "GenSigTimeoutTime" BU_SG_REL_ MFK SG_ 525 PaCo_PLAIPA_TargetState 5000;
BA_REL_ "GenSigTimeoutTime" BU_SG_REL_ MFK SG_ 525 PaCo_MainState 5000;
BA_REL_ "GenSigTimeoutTime" BU_SG_REL_ MFK SG_ 525 PaCo_TPA_TargetState 5000;
BA_REL_ "GenSigTimeoutTime" BU_SG_REL_ MFK SG_ 518 IPA_TPA_Remote 500;
BA_REL_ "GenSigTimeoutTime" BU_SG_REL_ MFK SG_ 518 IPA_TPA_Remote_Anf 500;
BA_REL_ "GenSigTimeoutTime" BU_SG_REL_ MFK SG_ 518 IPA_TPA_Fehler 500;
BA_REL_ "GenSigTimeoutTime" BU_SG_REL_ MFK SG_ 518 IPA_TPA_Abbruch 500;
BA_REL_ "GenSigTimeoutTime" BU_SG_REL_ MFK SG_ 518 IPA_TPA_Status 500;
BA_REL_ "GenSigTimeoutTime" BU_SG_REL_ MFK SG_ 2527679498 Perso_Kontonummer 5000;
BA_REL_ "GenSigTimeoutTime" BU_SG_REL_ MFK SG_ 2527679498 Perso_Steuerung 5000;
BA_REL_ "GenSigTimeoutTime" BU_SG_REL_ MFK SG_ 2527679498 Perso_Steuerungsparameter 5000;
BA_REL_ "GenSigTimeoutTime" BU_SG_REL_ MFK SG_ 2527679498 Perso_Status 5000;
BA_REL_ "GenSigTimeoutTime" BU_SG_REL_ MFK SG_ 2527679498 Perso_Bedienstelle 5000;
BA_REL_ "GenSigTimeoutTime" BU_SG_REL_ MFK SG_ 2527679498 Perso_Freigabe_Verstellung 5000;
BA_REL_ "GenSigTimeoutTime" BU_SG_REL_ MFK SG_ 2527679498 Perso_Aktiv 5000;
BA_REL_ "GenSigTimeoutTime" BU_SG_REL_ MFK SG_ 2527679498 Perso_Fahrernummer 5000;
BA_REL_ "GenSigTimeoutTime" BU_SG_REL_ MFK SG_ 2527679498 Perso_Schreibschutz 5000;
BA_REL_ "GenSigTimeoutTime" BU_SG_REL_ MFK SG_ 1031 PLAIPA_PaCo_UnavailableReason 1000;
BA_REL_ "GenSigTimeoutTime" BU_SG_REL_ MFK SG_ 317 QFK_01_Sendestatus 500;
BA_REL_ "GenSigTimeoutTime" BU_SG_REL_ MFK SG_ 317 QFK_stEingriffBr 500;
BA_REL_ "GenSigTimeoutTime" BU_SG_REL_ MFK SG_ 317 QFK_DynBegr_aktiv 500;
BA_REL_ "GenSigTimeoutTime" BU_SG_REL_ MFK SG_ 317 QFK_Anf_Giermomoffset_VZ 500;
BA_REL_ "GenSigTimeoutTime" BU_SG_REL_ MFK SG_ 317 QFK_Status 500;
BA_REL_ "GenSigTimeoutTime" BU_SG_REL_ MFK SG_ 317 QFK_stHCA 500;
BA_REL_ "GenSigTimeoutTime" BU_SG_REL_ MFK SG_ 317 QFK_KrIst_VZ 500;
BA_REL_ "GenSigTimeoutTime" BU_SG_REL_ MFK SG_ 317 QFK_IstKraft_VZ 500;
BA_REL_ "GenSigTimeoutTime" BU_SG_REL_ MFK SG_ 317 QFK_KruemmIst 500;
BA_REL_ "GenSigTimeoutTime" BU_SG_REL_ MFK SG_ 317 QFK_KruemmIst_VZ 500;
BA_REL_ "GenSigTimeoutTime" BU_SG_REL_ MFK SG_ 317 QFK_IstKraftNiveau 500;
BA_REL_ "GenSigTimeoutTime" BU_SG_REL_ MFK SG_ 317 QFK_IstKraftNiveau_VZ 500;
BA_REL_ "GenSigTimeoutTime" BU_SG_REL_ MFK SG_ 317 QFK_Anf_Giermomoffset 500;
BA_REL_ "GenSigTimeoutTime" BU_SG_REL_ MFK SG_ 317 QFK_KrIst 500;
BA_REL_ "GenSigTimeoutTime" BU_SG_REL_ MFK SG_ 317 QFK_IstKraft 500;
BA_REL_ "GenSigTimeoutTime" BU_SG_REL_ MFK120 SG_ 2589283656 ORU_Warnung 5000;
BA_REL_ "GenSigTimeoutTime" BU_SG_REL_ MFK120 SG_ 2589283656 ORU_Status 5000;
BA_REL_ "GenSigTimeoutTime" BU_SG_REL_ MFK120 SG_ 2589284073 ORUG01_01_CRC 5000;
BA_REL_ "GenSigTimeoutTime" BU_SG_REL_ MFK120 SG_ 2589284073 ORUG01_01_BZ 5000;
BA_REL_ "GenSigTimeoutTime" BU_SG_REL_ MFK120 SG_ 2589284073 ORUG1_TargetRelease 5000;
BA_REL_ "GenSigTimeoutTime" BU_SG_REL_ MFK120 SG_ 2589284074 ORUG02_01_CRC 5000;
BA_REL_ "GenSigTimeoutTime" BU_SG_REL_ MFK120 SG_ 2589284074 ORUG02_01_BZ 5000;
BA_REL_ "GenSigTimeoutTime" BU_SG_REL_ MFK120 SG_ 2589284074 ORUG2_TargetRelease 5000;
BA_REL_ "GenSigTimeoutTime" BU_SG_REL_ MFK120 SG_ 525 PaCo_01_Sendestatus 5000;
BA_REL_ "GenSigTimeoutTime" BU_SG_REL_ MFK120 SG_ 525 PaCo_PLAIPA_TargetState 5000;
BA_REL_ "GenSigTimeoutTime" BU_SG_REL_ MFK120 SG_ 525 PaCo_MainState 5000;
BA_REL_ "GenSigTimeoutTime" BU_SG_REL_ MFK120 SG_ 525 PaCo_TPA_TargetState 5000;
BA_REL_ "GenSigTimeoutTime" BU_SG_REL_ MFK120 SG_ 518 IPA_TPA_ausgerichtetes_Parken 500;
BA_REL_ "GenSigTimeoutTime" BU_SG_REL_ MFK120 SG_ 518 IPA_TPA_Remote 500;
BA_REL_ "GenSigTimeoutTime" BU_SG_REL_ MFK120 SG_ 518 IPA_TPA_Remote_Anf 500;
BA_REL_ "GenSigTimeoutTime" BU_SG_REL_ MFK120 SG_ 518 IPA_TPA_Fehler 500;
BA_REL_ "GenSigTimeoutTime" BU_SG_REL_ MFK120 SG_ 518 IPA_TPA_Abbruch 500;
BA_REL_ "GenSigTimeoutTime" BU_SG_REL_ MFK120 SG_ 518 IPA_TPA_Status 500;
BA_REL_ "GenSigTimeoutTime" BU_SG_REL_ MFK120 SG_ 2527679498 Perso_Kontonummer 5000;
BA_REL_ "GenSigTimeoutTime" BU_SG_REL_ MFK120 SG_ 2527679498 Perso_Steuerung 5000;
BA_REL_ "GenSigTimeoutTime" BU_SG_REL_ MFK120 SG_ 2527679498 Perso_Steuerungsparameter 5000;
BA_REL_ "GenSigTimeoutTime" BU_SG_REL_ MFK120 SG_ 2527679498 Perso_Status 5000;
BA_REL_ "GenSigTimeoutTime" BU_SG_REL_ MFK120 SG_ 2527679498 Perso_Aktiv 5000;
BA_REL_ "GenSigTimeoutTime" BU_SG_REL_ MFK120 SG_ 2527679498 Perso_Fahrernummer 5000;
BA_REL_ "GenSigTimeoutTime" BU_SG_REL_ MFK120 SG_ 1031 PLAIPA_PaCo_UnavailableReason 1000;
BA_REL_ "GenSigTimeoutTime" BU_SG_REL_ MFK120 SG_ 1122 PSD_Segment_ID 1500;
BA_REL_ "GenSigTimeoutTime" BU_SG_REL_ MFK120 SG_ 1122 PSD_Vorgaenger_Segment_ID 1500;
BA_REL_ "GenSigTimeoutTime" BU_SG_REL_ MFK120 SG_ 1122 PSD_Segmentlaenge 1500;
BA_REL_ "GenSigTimeoutTime" BU_SG_REL_ MFK120 SG_ 1122 PSD_Strassenkategorie 1500;
BA_REL_ "GenSigTimeoutTime" BU_SG_REL_ MFK120 SG_ 1122 PSD_Endkruemmung 1500;
BA_REL_ "GenSigTimeoutTime" BU_SG_REL_ MFK120 SG_ 1122 PSD_Endkruemmung_Vorz 1500;
BA_REL_ "GenSigTimeoutTime" BU_SG_REL_ MFK120 SG_ 1122 PSD_Idenditaets_ID 1500;
BA_REL_ "GenSigTimeoutTime" BU_SG_REL_ MFK120 SG_ 1122 PSD_ADAS_Qualitaet 1500;
BA_REL_ "GenSigTimeoutTime" BU_SG_REL_ MFK120 SG_ 1122 PSD_wahrscheinlichster_Pfad 1500;
BA_REL_ "GenSigTimeoutTime" BU_SG_REL_ MFK120 SG_ 1122 PSD_Geradester_Pfad 1500;
BA_REL_ "GenSigTimeoutTime" BU_SG_REL_ MFK120 SG_ 1122 PSD_Fahrspuren_Anzahl 1500;
BA_REL_ "GenSigTimeoutTime" BU_SG_REL_ MFK120 SG_ 1122 PSD_Bebauung 1500;
BA_REL_ "GenSigTimeoutTime" BU_SG_REL_ MFK120 SG_ 1122 PSD_Segment_Komplett 1500;
BA_REL_ "GenSigTimeoutTime" BU_SG_REL_ MFK120 SG_ 1122 PSD_Rampe 1500;
BA_REL_ "GenSigTimeoutTime" BU_SG_REL_ MFK120 SG_ 1122 PSD_Anfangskruemmung 1500;
BA_REL_ "GenSigTimeoutTime" BU_SG_REL_ MFK120 SG_ 1122 PSD_Anfangskruemmung_Vorz 1500;
BA_REL_ "GenSigTimeoutTime" BU_SG_REL_ MFK120 SG_ 1122 PSD_Abzweigerichtung 1500;
BA_REL_ "GenSigTimeoutTime" BU_SG_REL_ MFK120 SG_ 1122 PSD_Abzweigewinkel 1500;
BA_REL_ "GenSigTimeoutTime" BU_SG_REL_ MFK120 SG_ 1123 PSD_Pos_Segment_ID 1500;
BA_REL_ "GenSigTimeoutTime" BU_SG_REL_ MFK120 SG_ 1123 PSD_Pos_Segmentlaenge 1500;
BA_REL_ "GenSigTimeoutTime" BU_SG_REL_ MFK120 SG_ 1123 PSD_Pos_Inhibitzeit 1500;
BA_REL_ "GenSigTimeoutTime" BU_SG_REL_ MFK120 SG_ 1123 PSD_Pos_Standort_Eindeutig 1500;
BA_REL_ "GenSigTimeoutTime" BU_SG_REL_ MFK120 SG_ 1123 PSD_Pos_Fehler_Laengsrichtung 1500;
BA_REL_ "GenSigTimeoutTime" BU_SG_REL_ MFK120 SG_ 1123 PSD_Pos_Fahrspur 1500;
BA_REL_ "GenSigTimeoutTime" BU_SG_REL_ MFK120 SG_ 1123 PSD_Attribut_Segment_ID_05 1500;
BA_REL_ "GenSigTimeoutTime" BU_SG_REL_ MFK120 SG_ 1123 PSD_Attribut_1_ID 1500;
BA_REL_ "GenSigTimeoutTime" BU_SG_REL_ MFK120 SG_ 1123 PSD_Attribut_1_Wert 1500;
BA_REL_ "GenSigTimeoutTime" BU_SG_REL_ MFK120 SG_ 1123 PSD_Attribut_1_Offset 1500;
BA_REL_ "GenSigTimeoutTime" BU_SG_REL_ MFK120 SG_ 1123 PSD_Attribut_2_ID 1500;
BA_REL_ "GenSigTimeoutTime" BU_SG_REL_ MFK120 SG_ 1123 PSD_Attribut_2_Wert 1500;
BA_REL_ "GenSigTimeoutTime" BU_SG_REL_ MFK120 SG_ 1123 PSD_Attribut_2_Offset 1500;
BA_REL_ "GenSigTimeoutTime" BU_SG_REL_ MFK120 SG_ 1123 PSD_Attribute_Komplett_05 1500;
BA_REL_ "GenSigTimeoutTime" BU_SG_REL_ MFK120 SG_ 1124 PSD_06_Mux 1500;
BA_REL_ "GenSigTimeoutTime" BU_SG_REL_ MFK120 SG_ 1124 PSD_Sys_Segment_ID 1500;
BA_REL_ "GenSigTimeoutTime" BU_SG_REL_ MFK120 SG_ 1124 PSD_Attribut_Segment_ID 1500;
BA_REL_ "GenSigTimeoutTime" BU_SG_REL_ MFK120 SG_ 1124 PSD_Ges_Segment_ID 1500;
BA_REL_ "GenSigTimeoutTime" BU_SG_REL_ MFK120 SG_ 1124 PSD_Baum_Laenge_VZ 1500;
BA_REL_ "GenSigTimeoutTime" BU_SG_REL_ MFK120 SG_ 1124 PSD_Steigung_1_Segment_ID 1500;
BA_REL_ "GenSigTimeoutTime" BU_SG_REL_ MFK120 SG_ 1124 PSD_Baum_Laenge 1500;
BA_REL_ "GenSigTimeoutTime" BU_SG_REL_ MFK120 SG_ 1124 PSD_Sys_Laendercode 1500;
BA_REL_ "GenSigTimeoutTime" BU_SG_REL_ MFK120 SG_ 1124 PSD_Attribut_3_ID 1500;
BA_REL_ "GenSigTimeoutTime" BU_SG_REL_ MFK120 SG_ 1124 PSD_Ges_Offset 1500;
BA_REL_ "GenSigTimeoutTime" BU_SG_REL_ MFK120 SG_ 1124 PSD_Steigung_1_A_Steigung 1500;
BA_REL_ "GenSigTimeoutTime" BU_SG_REL_ MFK120 SG_ 1124 PSD_Attribut_3_Offset 1500;
BA_REL_ "GenSigTimeoutTime" BU_SG_REL_ MFK120 SG_ 1124 PSD_Ges_Geschwindigkeit 1500;
BA_REL_ "GenSigTimeoutTime" BU_SG_REL_ MFK120 SG_ 1124 PSD_Steigung_1_A_Vorz 1500;
BA_REL_ "GenSigTimeoutTime" BU_SG_REL_ MFK120 SG_ 1124 PSD_Sys_Geschwindigkeit_Einheit 1500;
BA_REL_ "GenSigTimeoutTime" BU_SG_REL_ MFK120 SG_ 1124 PSD_Steigung_1_A_Offset 1500;
BA_REL_ "GenSigTimeoutTime" BU_SG_REL_ MFK120 SG_ 1124 PSD_Sys_Verkehrsrichtung 1500;
BA_REL_ "GenSigTimeoutTime" BU_SG_REL_ MFK120 SG_ 1124 PSD_Sys_Geometrieguete 1500;
BA_REL_ "GenSigTimeoutTime" BU_SG_REL_ MFK120 SG_ 1124 PSD_Sys_Mapmatchingguete 1500;
BA_REL_ "GenSigTimeoutTime" BU_SG_REL_ MFK120 SG_ 1124 PSD_Attribut_3_Wert 1500;
BA_REL_ "GenSigTimeoutTime" BU_SG_REL_ MFK120 SG_ 1124 PSD_Ges_Typ 1500;
BA_REL_ "GenSigTimeoutTime" BU_SG_REL_ MFK120 SG_ 1124 PSD_Sys_Alter_Karte 1500;
BA_REL_ "GenSigTimeoutTime" BU_SG_REL_ MFK120 SG_ 1124 PSD_Ges_Spur_Geschw_Begrenzung 1500;
BA_REL_ "GenSigTimeoutTime" BU_SG_REL_ MFK120 SG_ 1124 PSD_Steigung_1_B_Steigung 1500;
BA_REL_ "GenSigTimeoutTime" BU_SG_REL_ MFK120 SG_ 1124 PSD_Attribut_4_ID 1500;
BA_REL_ "GenSigTimeoutTime" BU_SG_REL_ MFK120 SG_ 1124 PSD_Sys_Zielfuehrung 1500;
BA_REL_ "GenSigTimeoutTime" BU_SG_REL_ MFK120 SG_ 1124 PSD_Sys_US_State 1500;
BA_REL_ "GenSigTimeoutTime" BU_SG_REL_ MFK120 SG_ 1124 PSD_Ges_Geschwindigkeit_Gespann 1500;
BA_REL_ "GenSigTimeoutTime" BU_SG_REL_ MFK120 SG_ 1124 PSD_Baum_Breite_VZ 1500;
BA_REL_ "GenSigTimeoutTime" BU_SG_REL_ MFK120 SG_ 1124 PSD_Attribut_4_Wert 1500;
BA_REL_ "GenSigTimeoutTime" BU_SG_REL_ MFK120 SG_ 1124 PSD_Baum_Breite 1500;
BA_REL_ "GenSigTimeoutTime" BU_SG_REL_ MFK120 SG_ 1124 PSD_Ges_Geschwindigkeit_Witter 1500;
BA_REL_ "GenSigTimeoutTime" BU_SG_REL_ MFK120 SG_ 1124 PSD_Steigung_1_B_Vorz 1500;
BA_REL_ "GenSigTimeoutTime" BU_SG_REL_ MFK120 SG_ 1124 PSD_Steigung_1_B_Offset 1500;
BA_REL_ "GenSigTimeoutTime" BU_SG_REL_ MFK120 SG_ 1124 PSD_Sys_Quali_Geometrien 1500;
BA_REL_ "GenSigTimeoutTime" BU_SG_REL_ MFK120 SG_ 1124 PSD_Ges_Geschwindigkeit_Tag_Anf 1500;
BA_REL_ "GenSigTimeoutTime" BU_SG_REL_ MFK120 SG_ 1124 PSD_Attribut_4_Offset 1500;
BA_REL_ "GenSigTimeoutTime" BU_SG_REL_ MFK120 SG_ 1124 PSD_Sys_Quali_Ortsinfo 1500;
BA_REL_ "GenSigTimeoutTime" BU_SG_REL_ MFK120 SG_ 1124 PSD_Ges_Geschwindigkeit_Tag_Ende 1500;
BA_REL_ "GenSigTimeoutTime" BU_SG_REL_ MFK120 SG_ 1124 PSD_Sys_Quali_verfuegbar 1500;
BA_REL_ "GenSigTimeoutTime" BU_SG_REL_ MFK120 SG_ 1124 PSD_Sys_Zielfuehrung_geaendert 1500;
BA_REL_ "GenSigTimeoutTime" BU_SG_REL_ MFK120 SG_ 1124 PSD_Ges_Geschwindigkeit_Std_Anf 1500;
BA_REL_ "GenSigTimeoutTime" BU_SG_REL_ MFK120 SG_ 1124 PSD_Steigung_1_Attribute_kompl 1500;
BA_REL_ "GenSigTimeoutTime" BU_SG_REL_ MFK120 SG_ 1124 PSD_Sys_Geometrieguete_erweitert 1500;
BA_REL_ "GenSigTimeoutTime" BU_SG_REL_ MFK120 SG_ 1124 PSD_Steigung_2_Segment_ID 1500;
BA_REL_ "GenSigTimeoutTime" BU_SG_REL_ MFK120 SG_ 1124 PSD_Attribut_5_ID 1500;
BA_REL_ "GenSigTimeoutTime" BU_SG_REL_ MFK120 SG_ 1124 PSD_Ges_Geschwindigkeit_Std_Ende 1500;
BA_REL_ "GenSigTimeoutTime" BU_SG_REL_ MFK120 SG_ 1124 PSD_Attribut_5_Offset 1500;
BA_REL_ "GenSigTimeoutTime" BU_SG_REL_ MFK120 SG_ 1124 PSD_Steigung_2_Steigung 1500;
BA_REL_ "GenSigTimeoutTime" BU_SG_REL_ MFK120 SG_ 1124 PSD_Sys_Quali_sonstige_Attribute 1500;
BA_REL_ "GenSigTimeoutTime" BU_SG_REL_ MFK120 SG_ 1124 PSD_Ges_Ueberholverbot 1500;
BA_REL_ "GenSigTimeoutTime" BU_SG_REL_ MFK120 SG_ 1124 PSD_Sys_Quali_Steigungen 1500;
BA_REL_ "GenSigTimeoutTime" BU_SG_REL_ MFK120 SG_ 1124 PSD_Ges_Wechselverkehrszeichen 1500;
BA_REL_ "GenSigTimeoutTime" BU_SG_REL_ MFK120 SG_ 1124 PSD_Attribut_5_Wert 1500;
BA_REL_ "GenSigTimeoutTime" BU_SG_REL_ MFK120 SG_ 1124 PSD_Steigung_2_Vorz 1500;
BA_REL_ "GenSigTimeoutTime" BU_SG_REL_ MFK120 SG_ 1124 PSD_Sys_Quali_Strassenkennz 1500;
BA_REL_ "GenSigTimeoutTime" BU_SG_REL_ MFK120 SG_ 1124 PSD_Wechselverkehrszeichen_Typ 1500;
BA_REL_ "GenSigTimeoutTime" BU_SG_REL_ MFK120 SG_ 1124 PSD_Baum_Ausrichtung 1500;
BA_REL_ "GenSigTimeoutTime" BU_SG_REL_ MFK120 SG_ 1124 PSD_Steigung_2_Offset 1500;
BA_REL_ "GenSigTimeoutTime" BU_SG_REL_ MFK120 SG_ 1124 PSD_Ges_Gesetzlich_Kategorie 1500;
BA_REL_ "GenSigTimeoutTime" BU_SG_REL_ MFK120 SG_ 1124 PSD_Sys_Quali_Tempolimits 1500;
BA_REL_ "GenSigTimeoutTime" BU_SG_REL_ MFK120 SG_ 1124 PSD_Attribute_Komplett_06 1500;
BA_REL_ "GenSigTimeoutTime" BU_SG_REL_ MFK120 SG_ 1124 PSD_Ges_Gesetzlich_Zusatz 1500;
BA_REL_ "GenSigTimeoutTime" BU_SG_REL_ MFK120 SG_ 1124 PSD_Sys_Quali_Vorfahrtsregelung 1500;
BA_REL_ "GenSigTimeoutTime" BU_SG_REL_ MFK120 SG_ 1124 PSD_Ges_Verkehrszeichen_Quelle 1500;
BA_REL_ "GenSigTimeoutTime" BU_SG_REL_ MFK120 SG_ 1124 PSD_Steigung_2_Attribute_kompl 1500;
BA_REL_ "GenSigTimeoutTime" BU_SG_REL_ MFK120 SG_ 1124 PSD_Ges_Attribute_Komplett 1500;
BA_REL_ "GenSigTimeoutTime" BU_SG_REL_ MFK120 SG_ 317 QFK_stEingriffBr 500;
BA_REL_ "GenSigTimeoutTime" BU_SG_REL_ MFK120 SG_ 317 QFK_DynBegr_aktiv 500;
BA_REL_ "GenSigTimeoutTime" BU_SG_REL_ MFK120 SG_ 317 QFK_Anf_Giermomoffset_VZ 500;
BA_REL_ "GenSigTimeoutTime" BU_SG_REL_ MFK120 SG_ 317 QFK_Status 500;
BA_REL_ "GenSigTimeoutTime" BU_SG_REL_ MFK120 SG_ 317 QFK_stHCA 500;
BA_REL_ "GenSigTimeoutTime" BU_SG_REL_ MFK120 SG_ 317 QFK_KrIst_VZ 500;
BA_REL_ "GenSigTimeoutTime" BU_SG_REL_ MFK120 SG_ 317 QFK_IstKraft_VZ 500;
BA_REL_ "GenSigTimeoutTime" BU_SG_REL_ MFK120 SG_ 317 QFK_KruemmIst 500;
BA_REL_ "GenSigTimeoutTime" BU_SG_REL_ MFK120 SG_ 317 QFK_KruemmIst_VZ 500;
BA_REL_ "GenSigTimeoutTime" BU_SG_REL_ MFK120 SG_ 317 QFK_IstKraftNiveau 500;
BA_REL_ "GenSigTimeoutTime" BU_SG_REL_ MFK120 SG_ 317 QFK_IstKraftNiveau_VZ 500;
BA_REL_ "GenSigTimeoutTime" BU_SG_REL_ MFK120 SG_ 317 QFK_Anf_Giermomoffset 500;
BA_REL_ "GenSigTimeoutTime" BU_SG_REL_ MFK120 SG_ 317 QFK_KrIst 500;
BA_REL_ "GenSigTimeoutTime" BU_SG_REL_ MFK120 SG_ 317 QFK_IstKraft 500;
BA_REL_ "GenSigTimeoutTime" BU_SG_REL_ MIK SG_ 2589283656 ORU_Status 5000;
BA_REL_ "GenSigTimeoutTime" BU_SG_REL_ MRR2023 SG_ 2331595789 NR_FR_Object_09_10_CRC 500;
BA_REL_ "GenSigTimeoutTime" BU_SG_REL_ MRR2023 SG_ 2331595789 NR_FR_Object_09_10_BZ 500;
BA_REL_ "GenSigTimeoutTime" BU_SG_REL_ MRR2023 SG_ 2331595789 NR_FR_Object_09_10_BlockID_02 500;
BA_REL_ "GenSigTimeoutTime" BU_SG_REL_ MRR2023 SG_ 2331595789 NR_FR_Object_09_ID 500;
BA_REL_ "GenSigTimeoutTime" BU_SG_REL_ MRR2023 SG_ 2331595789 NR_FR_Object_09_ReferencePoint 500;
BA_REL_ "GenSigTimeoutTime" BU_SG_REL_ MRR2023 SG_ 2331595789 NR_FR_Object_09_PosX 500;
BA_REL_ "GenSigTimeoutTime" BU_SG_REL_ MRR2023 SG_ 2331595789 NR_FR_Object_09_PosXSD 500;
BA_REL_ "GenSigTimeoutTime" BU_SG_REL_ MRR2023 SG_ 2331595789 NR_FR_Object_09_PosY 500;
BA_REL_ "GenSigTimeoutTime" BU_SG_REL_ MRR2023 SG_ 2331595789 NR_FR_Object_09_PosYSD 500;
BA_REL_ "GenSigTimeoutTime" BU_SG_REL_ MRR2023 SG_ 2331595789 NR_FR_Object_09_vAbsX 500;
BA_REL_ "GenSigTimeoutTime" BU_SG_REL_ MRR2023 SG_ 2331595789 NR_FR_Object_09_vAbsXSD 500;
BA_REL_ "GenSigTimeoutTime" BU_SG_REL_ MRR2023 SG_ 2331595789 NR_FR_Object_09_vAbsY 500;
BA_REL_ "GenSigTimeoutTime" BU_SG_REL_ MRR2023 SG_ 2331595789 NR_FR_Object_09_vAbsYSD 500;
BA_REL_ "GenSigTimeoutTime" BU_SG_REL_ MRR2023 SG_ 2331595789 NR_FR_Object_09_aAbsX 500;
BA_REL_ "GenSigTimeoutTime" BU_SG_REL_ MRR2023 SG_ 2331595789 NR_FR_Object_09_aAbsXSD 500;
BA_REL_ "GenSigTimeoutTime" BU_SG_REL_ MRR2023 SG_ 2331595789 NR_FR_Object_09_aAbsY 500;
BA_REL_ "GenSigTimeoutTime" BU_SG_REL_ MRR2023 SG_ 2331595789 NR_FR_Object_09_aAbsYSD 500;
BA_REL_ "GenSigTimeoutTime" BU_SG_REL_ MRR2023 SG_ 2331595789 NR_FR_Object_09_DynamicState 500;
BA_REL_ "GenSigTimeoutTime" BU_SG_REL_ MRR2023 SG_ 2331595789 NR_FR_Object_09_YawAngle 500;
BA_REL_ "GenSigTimeoutTime" BU_SG_REL_ MRR2023 SG_ 2331595789 NR_FR_Object_09_YawAngleSD 500;
BA_REL_ "GenSigTimeoutTime" BU_SG_REL_ MRR2023 SG_ 2331595789 NR_FR_Object_09_Width 500;
BA_REL_ "GenSigTimeoutTime" BU_SG_REL_ MRR2023 SG_ 2331595789 NR_FR_Object_09_WidthSD 500;
BA_REL_ "GenSigTimeoutTime" BU_SG_REL_ MRR2023 SG_ 2331595789 NR_FR_Object_09_Length 500;
BA_REL_ "GenSigTimeoutTime" BU_SG_REL_ MRR2023 SG_ 2331595789 NR_FR_Object_09_LengthSD 500;
BA_REL_ "GenSigTimeoutTime" BU_SG_REL_ MRR2023 SG_ 2331595789 NR_FR_Object_09_Class 500;
BA_REL_ "GenSigTimeoutTime" BU_SG_REL_ MRR2023 SG_ 2331595789 NR_FR_Object_09_ClassPlausib 500;
BA_REL_ "GenSigTimeoutTime" BU_SG_REL_ MRR2023 SG_ 2331595789 NR_FR_Object_09_ExistProb 500;
BA_REL_ "GenSigTimeoutTime" BU_SG_REL_ MRR2023 SG_ 2331595789 NR_FR_Object_09_Age 500;
BA_REL_ "GenSigTimeoutTime" BU_SG_REL_ MRR2023 SG_ 2331595789 NR_FR_Object_09_YawRateAbs 500;
BA_REL_ "GenSigTimeoutTime" BU_SG_REL_ MRR2023 SG_ 2331595789 NR_FR_Object_09_YawRateAbsSD 500;
BA_REL_ "GenSigTimeoutTime" BU_SG_REL_ MRR2023 SG_ 2331595789 NR_FR_Object_09_MeasurementState 500;
BA_REL_ "GenSigTimeoutTime" BU_SG_REL_ MRR2023 SG_ 2331595789 NR_FR_Object_10_ID 500;
BA_REL_ "GenSigTimeoutTime" BU_SG_REL_ MRR2023 SG_ 2331595789 NR_FR_Object_10_ReferencePoint 500;
BA_REL_ "GenSigTimeoutTime" BU_SG_REL_ MRR2023 SG_ 2331595789 NR_FR_Object_10_PosX 500;
BA_REL_ "GenSigTimeoutTime" BU_SG_REL_ MRR2023 SG_ 2331595789 NR_FR_Object_10_PosXSD 500;
BA_REL_ "GenSigTimeoutTime" BU_SG_REL_ MRR2023 SG_ 2331595789 NR_FR_Object_10_PosY 500;
BA_REL_ "GenSigTimeoutTime" BU_SG_REL_ MRR2023 SG_ 2331595789 NR_FR_Object_10_PosYSD 500;
BA_REL_ "GenSigTimeoutTime" BU_SG_REL_ MRR2023 SG_ 2331595789 NR_FR_Object_10_vAbsX 500;
BA_REL_ "GenSigTimeoutTime" BU_SG_REL_ MRR2023 SG_ 2331595789 NR_FR_Object_10_vAbsXSD 500;
BA_REL_ "GenSigTimeoutTime" BU_SG_REL_ MRR2023 SG_ 2331595789 NR_FR_Object_10_vAbsY 500;
BA_REL_ "GenSigTimeoutTime" BU_SG_REL_ MRR2023 SG_ 2331595789 NR_FR_Object_10_vAbsYSD 500;
BA_REL_ "GenSigTimeoutTime" BU_SG_REL_ MRR2023 SG_ 2331595789 NR_FR_Object_10_aAbsX 500;
BA_REL_ "GenSigTimeoutTime" BU_SG_REL_ MRR2023 SG_ 2331595789 NR_FR_Object_10_aAbsXSD 500;
BA_REL_ "GenSigTimeoutTime" BU_SG_REL_ MRR2023 SG_ 2331595789 NR_FR_Object_10_aAbsY 500;
BA_REL_ "GenSigTimeoutTime" BU_SG_REL_ MRR2023 SG_ 2331595789 NR_FR_Object_10_aAbsYSD 500;
BA_REL_ "GenSigTimeoutTime" BU_SG_REL_ MRR2023 SG_ 2331595789 NR_FR_Object_10_DynamicState 500;
BA_REL_ "GenSigTimeoutTime" BU_SG_REL_ MRR2023 SG_ 2331595789 NR_FR_Object_10_YawAngle 500;
BA_REL_ "GenSigTimeoutTime" BU_SG_REL_ MRR2023 SG_ 2331595789 NR_FR_Object_10_YawAngleSD 500;
BA_REL_ "GenSigTimeoutTime" BU_SG_REL_ MRR2023 SG_ 2331595789 NR_FR_Object_10_Width 500;
BA_REL_ "GenSigTimeoutTime" BU_SG_REL_ MRR2023 SG_ 2331595789 NR_FR_Object_10_WidthSD 500;
BA_REL_ "GenSigTimeoutTime" BU_SG_REL_ MRR2023 SG_ 2331595789 NR_FR_Object_10_Length 500;
BA_REL_ "GenSigTimeoutTime" BU_SG_REL_ MRR2023 SG_ 2331595789 NR_FR_Object_10_LengthSD 500;
BA_REL_ "GenSigTimeoutTime" BU_SG_REL_ MRR2023 SG_ 2331595789 NR_FR_Object_10_Class 500;
BA_REL_ "GenSigTimeoutTime" BU_SG_REL_ MRR2023 SG_ 2331595789 NR_FR_Object_10_ClassPlausib 500;
BA_REL_ "GenSigTimeoutTime" BU_SG_REL_ MRR2023 SG_ 2331595789 NR_FR_Object_10_ExistProb 500;
BA_REL_ "GenSigTimeoutTime" BU_SG_REL_ MRR2023 SG_ 2331595789 NR_FR_Object_10_Age 500;
BA_REL_ "GenSigTimeoutTime" BU_SG_REL_ MRR2023 SG_ 2331595789 NR_FR_Object_10_YawRateAbs 500;
BA_REL_ "GenSigTimeoutTime" BU_SG_REL_ MRR2023 SG_ 2331595789 NR_FR_Object_10_YawRateAbsSD 500;
BA_REL_ "GenSigTimeoutTime" BU_SG_REL_ MRR2023 SG_ 2331595789 NR_FR_Object_10_MeasurementState 500;
BA_REL_ "GenSigTimeoutTime" BU_SG_REL_ MRR2023 SG_ 2589284097 NR_FR_HW_Version 5000;
BA_REL_ "GenSigTimeoutTime" BU_SG_REL_ MRR2023 SG_ 2589284097 NR_FR_SW_Version 5000;
BA_REL_ "GenSigTimeoutTime" BU_SG_REL_ MRR2023 SG_ 2589284097 NR_FR_SerialNumber 5000;
BA_REL_ "GenSigTimeoutTime" BU_SG_REL_ MRR2023 SG_ 2331595851 NR_FR_Structure_BlockID_02 500;
BA_REL_ "GenSigTimeoutTime" BU_SG_REL_ MRR2023 SG_ 2331595851 NR_FR_Structure_right_LatDist 500;
BA_REL_ "GenSigTimeoutTime" BU_SG_REL_ MRR2023 SG_ 2331595851 NR_FR_Structure_right_Type 500;
BA_REL_ "GenSigTimeoutTime" BU_SG_REL_ MRR2023 SG_ 2331595851 NR_FR_Structure_right_ExistProb 500;
BA_REL_ "GenSigTimeoutTime" BU_SG_REL_ MRR2023 SG_ 2264486984 NR_FR_SyncReadyVersion 500;
BA_REL_ "GenSigTimeoutTime" BU_SG_REL_ MRR2023 SG_ 2264486984 NR_FR_EarliestStartTime 500;
BA_REL_ "GenSigTimeoutTime" BU_SG_REL_ MRR2023 SG_ 2264486984 NR_FR_RequestedModulation 500;
BA_REL_ "GenSigTimeoutTime" BU_SG_REL_ MRR2023 SG_ 2264486984 NR_FR_InteferenceInfo 500;
BA_REL_ "GenSigTimeoutTime" BU_SG_REL_ MRR2023 SG_ 2264486984 NR_FR_SyncCycleCount 500;
BA_REL_ "GenSigTimeoutTime" BU_SG_REL_ MRR2023 SG_ 2264486984 NR_FR_LatestSyncCounter 500;
BA_REL_ "GenSigTimeoutTime" BU_SG_REL_ MRR2023 SG_ 2589283656 ORU_01_CRC 5000;
BA_REL_ "GenSigTimeoutTime" BU_SG_REL_ MRR2023 SG_ 2589283656 ORU_01_BZ 5000;
BA_REL_ "GenSigTimeoutTime" BU_SG_REL_ MRR2023 SG_ 2589283656 ORU_Status 5000;
BA_REL_ "GenSigTimeoutTime" BU_SG_REL_ MRR2023 SG_ 2589284073 ORUG1_TargetRelease 5000;
BA_REL_ "GenSigTimeoutTime" BU_SG_REL_ MRR2023 SG_ 2589284074 ORUG2_TargetRelease 5000;
BA_REL_ "GenSigTimeoutTime" BU_SG_REL_ MRR2023 SG_ 2527679498 Perso_Kontonummer 5000;
BA_REL_ "GenSigTimeoutTime" BU_SG_REL_ MRR2023 SG_ 2527679498 Perso_Steuerung 5000;
BA_REL_ "GenSigTimeoutTime" BU_SG_REL_ MRR2023 SG_ 2527679498 Perso_Steuerungsparameter 5000;
BA_REL_ "GenSigTimeoutTime" BU_SG_REL_ MRR2023 SG_ 2527679498 Perso_Status 5000;
BA_REL_ "GenSigTimeoutTime" BU_SG_REL_ MRR2023 SG_ 2527679498 Perso_Bedienstelle 5000;
BA_REL_ "GenSigTimeoutTime" BU_SG_REL_ MRR2023 SG_ 2527679498 Perso_Freigabe_Verstellung 5000;
BA_REL_ "GenSigTimeoutTime" BU_SG_REL_ MRR2023 SG_ 2527679498 Perso_Aktiv 5000;
BA_REL_ "GenSigTimeoutTime" BU_SG_REL_ MRR2023 SG_ 2527679498 Perso_Fahrernummer 5000;
BA_REL_ "GenSigTimeoutTime" BU_SG_REL_ MRR2023 SG_ 2527679498 Perso_Schreibschutz 5000;
BA_REL_ "GenSigTimeoutTime" BU_SG_REL_ MRR2023 SG_ 1031 PLAIPA_PaCo_FunctionState 1000;
BA_REL_ "GenSigTimeoutTime" BU_SG_REL_ MRR2023 SG_ 1122 PSD_Segment_ID 1500;
BA_REL_ "GenSigTimeoutTime" BU_SG_REL_ MRR2023 SG_ 1122 PSD_Vorgaenger_Segment_ID 1500;
BA_REL_ "GenSigTimeoutTime" BU_SG_REL_ MRR2023 SG_ 1122 PSD_Segmentlaenge 1500;
BA_REL_ "GenSigTimeoutTime" BU_SG_REL_ MRR2023 SG_ 1122 PSD_Strassenkategorie 1500;
BA_REL_ "GenSigTimeoutTime" BU_SG_REL_ MRR2023 SG_ 1122 PSD_Endkruemmung 1500;
BA_REL_ "GenSigTimeoutTime" BU_SG_REL_ MRR2023 SG_ 1122 PSD_Endkruemmung_Vorz 1500;
BA_REL_ "GenSigTimeoutTime" BU_SG_REL_ MRR2023 SG_ 1122 PSD_Idenditaets_ID 1500;
BA_REL_ "GenSigTimeoutTime" BU_SG_REL_ MRR2023 SG_ 1122 PSD_ADAS_Qualitaet 1500;
BA_REL_ "GenSigTimeoutTime" BU_SG_REL_ MRR2023 SG_ 1122 PSD_wahrscheinlichster_Pfad 1500;
BA_REL_ "GenSigTimeoutTime" BU_SG_REL_ MRR2023 SG_ 1122 PSD_Geradester_Pfad 1500;
BA_REL_ "GenSigTimeoutTime" BU_SG_REL_ MRR2023 SG_ 1122 PSD_Fahrspuren_Anzahl 1500;
BA_REL_ "GenSigTimeoutTime" BU_SG_REL_ MRR2023 SG_ 1122 PSD_Bebauung 1500;
BA_REL_ "GenSigTimeoutTime" BU_SG_REL_ MRR2023 SG_ 1122 PSD_Segment_Komplett 1500;
BA_REL_ "GenSigTimeoutTime" BU_SG_REL_ MRR2023 SG_ 1122 PSD_Rampe 1500;
BA_REL_ "GenSigTimeoutTime" BU_SG_REL_ MRR2023 SG_ 1122 PSD_Anfangskruemmung 1500;
BA_REL_ "GenSigTimeoutTime" BU_SG_REL_ MRR2023 SG_ 1122 PSD_Anfangskruemmung_Vorz 1500;
BA_REL_ "GenSigTimeoutTime" BU_SG_REL_ MRR2023 SG_ 1122 PSD_Abzweigerichtung 1500;
BA_REL_ "GenSigTimeoutTime" BU_SG_REL_ MRR2023 SG_ 1122 PSD_Abzweigewinkel 1500;
BA_REL_ "GenSigTimeoutTime" BU_SG_REL_ MRR2023 SG_ 1123 PSD_Pos_Segment_ID 1500;
BA_REL_ "GenSigTimeoutTime" BU_SG_REL_ MRR2023 SG_ 1123 PSD_Pos_Segmentlaenge 1500;
BA_REL_ "GenSigTimeoutTime" BU_SG_REL_ MRR2023 SG_ 1123 PSD_Pos_Inhibitzeit 1500;
BA_REL_ "GenSigTimeoutTime" BU_SG_REL_ MRR2023 SG_ 1123 PSD_Pos_Standort_Eindeutig 1500;
BA_REL_ "GenSigTimeoutTime" BU_SG_REL_ MRR2023 SG_ 1123 PSD_Pos_Fehler_Laengsrichtung 1500;
BA_REL_ "GenSigTimeoutTime" BU_SG_REL_ MRR2023 SG_ 1123 PSD_Pos_Fahrspur 1500;
BA_REL_ "GenSigTimeoutTime" BU_SG_REL_ MRR2023 SG_ 1123 PSD_Attribut_Segment_ID_05 1500;
BA_REL_ "GenSigTimeoutTime" BU_SG_REL_ MRR2023 SG_ 1123 PSD_Attribut_1_ID 1500;
BA_REL_ "GenSigTimeoutTime" BU_SG_REL_ MRR2023 SG_ 1123 PSD_Attribut_1_Wert 1500;
BA_REL_ "GenSigTimeoutTime" BU_SG_REL_ MRR2023 SG_ 1123 PSD_Attribut_1_Offset 1500;
BA_REL_ "GenSigTimeoutTime" BU_SG_REL_ MRR2023 SG_ 1123 PSD_Attribut_2_ID 1500;
BA_REL_ "GenSigTimeoutTime" BU_SG_REL_ MRR2023 SG_ 1123 PSD_Attribut_2_Wert 1500;
BA_REL_ "GenSigTimeoutTime" BU_SG_REL_ MRR2023 SG_ 1123 PSD_Attribut_2_Offset 1500;
BA_REL_ "GenSigTimeoutTime" BU_SG_REL_ MRR2023 SG_ 1123 PSD_Attribute_Komplett_05 1500;
BA_REL_ "GenSigTimeoutTime" BU_SG_REL_ MRR2023 SG_ 1124 PSD_06_Mux 1500;
BA_REL_ "GenSigTimeoutTime" BU_SG_REL_ MRR2023 SG_ 1124 PSD_Sys_Segment_ID 1500;
BA_REL_ "GenSigTimeoutTime" BU_SG_REL_ MRR2023 SG_ 1124 PSD_Attribut_Segment_ID 1500;
BA_REL_ "GenSigTimeoutTime" BU_SG_REL_ MRR2023 SG_ 1124 PSD_Ges_Segment_ID 1500;
BA_REL_ "GenSigTimeoutTime" BU_SG_REL_ MRR2023 SG_ 1124 PSD_Baum_Laenge_VZ 1500;
BA_REL_ "GenSigTimeoutTime" BU_SG_REL_ MRR2023 SG_ 1124 PSD_Steigung_1_Segment_ID 1500;
BA_REL_ "GenSigTimeoutTime" BU_SG_REL_ MRR2023 SG_ 1124 PSD_Baum_Laenge 1500;
BA_REL_ "GenSigTimeoutTime" BU_SG_REL_ MRR2023 SG_ 1124 PSD_Sys_Laendercode 1500;
BA_REL_ "GenSigTimeoutTime" BU_SG_REL_ MRR2023 SG_ 1124 PSD_Attribut_3_ID 1500;
BA_REL_ "GenSigTimeoutTime" BU_SG_REL_ MRR2023 SG_ 1124 PSD_Ges_Offset 1500;
BA_REL_ "GenSigTimeoutTime" BU_SG_REL_ MRR2023 SG_ 1124 PSD_Steigung_1_A_Steigung 1500;
BA_REL_ "GenSigTimeoutTime" BU_SG_REL_ MRR2023 SG_ 1124 PSD_Attribut_3_Offset 1500;
BA_REL_ "GenSigTimeoutTime" BU_SG_REL_ MRR2023 SG_ 1124 PSD_Ges_Geschwindigkeit 1500;
BA_REL_ "GenSigTimeoutTime" BU_SG_REL_ MRR2023 SG_ 1124 PSD_Steigung_1_A_Vorz 1500;
BA_REL_ "GenSigTimeoutTime" BU_SG_REL_ MRR2023 SG_ 1124 PSD_Sys_Geschwindigkeit_Einheit 1500;
BA_REL_ "GenSigTimeoutTime" BU_SG_REL_ MRR2023 SG_ 1124 PSD_Steigung_1_A_Offset 1500;
BA_REL_ "GenSigTimeoutTime" BU_SG_REL_ MRR2023 SG_ 1124 PSD_Sys_Verkehrsrichtung 1500;
BA_REL_ "GenSigTimeoutTime" BU_SG_REL_ MRR2023 SG_ 1124 PSD_Sys_Geometrieguete 1500;
BA_REL_ "GenSigTimeoutTime" BU_SG_REL_ MRR2023 SG_ 1124 PSD_Sys_Mapmatchingguete 1500;
BA_REL_ "GenSigTimeoutTime" BU_SG_REL_ MRR2023 SG_ 1124 PSD_Attribut_3_Wert 1500;
BA_REL_ "GenSigTimeoutTime" BU_SG_REL_ MRR2023 SG_ 1124 PSD_Ges_Typ 1500;
BA_REL_ "GenSigTimeoutTime" BU_SG_REL_ MRR2023 SG_ 1124 PSD_Sys_Alter_Karte 1500;
BA_REL_ "GenSigTimeoutTime" BU_SG_REL_ MRR2023 SG_ 1124 PSD_Ges_Spur_Geschw_Begrenzung 1500;
BA_REL_ "GenSigTimeoutTime" BU_SG_REL_ MRR2023 SG_ 1124 PSD_Steigung_1_B_Steigung 1500;
BA_REL_ "GenSigTimeoutTime" BU_SG_REL_ MRR2023 SG_ 1124 PSD_Attribut_4_ID 1500;
BA_REL_ "GenSigTimeoutTime" BU_SG_REL_ MRR2023 SG_ 1124 PSD_Sys_Zielfuehrung 1500;
BA_REL_ "GenSigTimeoutTime" BU_SG_REL_ MRR2023 SG_ 1124 PSD_Sys_US_State 1500;
BA_REL_ "GenSigTimeoutTime" BU_SG_REL_ MRR2023 SG_ 1124 PSD_Ges_Geschwindigkeit_Gespann 1500;
BA_REL_ "GenSigTimeoutTime" BU_SG_REL_ MRR2023 SG_ 1124 PSD_Baum_Breite_VZ 1500;
BA_REL_ "GenSigTimeoutTime" BU_SG_REL_ MRR2023 SG_ 1124 PSD_Attribut_4_Wert 1500;
BA_REL_ "GenSigTimeoutTime" BU_SG_REL_ MRR2023 SG_ 1124 PSD_Baum_Breite 1500;
BA_REL_ "GenSigTimeoutTime" BU_SG_REL_ MRR2023 SG_ 1124 PSD_Ges_Geschwindigkeit_Witter 1500;
BA_REL_ "GenSigTimeoutTime" BU_SG_REL_ MRR2023 SG_ 1124 PSD_Steigung_1_B_Vorz 1500;
BA_REL_ "GenSigTimeoutTime" BU_SG_REL_ MRR2023 SG_ 1124 PSD_Steigung_1_B_Offset 1500;
BA_REL_ "GenSigTimeoutTime" BU_SG_REL_ MRR2023 SG_ 1124 PSD_Sys_Quali_Geometrien 1500;
BA_REL_ "GenSigTimeoutTime" BU_SG_REL_ MRR2023 SG_ 1124 PSD_Ges_Geschwindigkeit_Tag_Anf 1500;
BA_REL_ "GenSigTimeoutTime" BU_SG_REL_ MRR2023 SG_ 1124 PSD_Attribut_4_Offset 1500;
BA_REL_ "GenSigTimeoutTime" BU_SG_REL_ MRR2023 SG_ 1124 PSD_Sys_Quali_Ortsinfo 1500;
BA_REL_ "GenSigTimeoutTime" BU_SG_REL_ MRR2023 SG_ 1124 PSD_Ges_Geschwindigkeit_Tag_Ende 1500;
BA_REL_ "GenSigTimeoutTime" BU_SG_REL_ MRR2023 SG_ 1124 PSD_Sys_Quali_verfuegbar 1500;
BA_REL_ "GenSigTimeoutTime" BU_SG_REL_ MRR2023 SG_ 1124 PSD_Sys_Zielfuehrung_geaendert 1500;
BA_REL_ "GenSigTimeoutTime" BU_SG_REL_ MRR2023 SG_ 1124 PSD_Ges_Geschwindigkeit_Std_Anf 1500;
BA_REL_ "GenSigTimeoutTime" BU_SG_REL_ MRR2023 SG_ 1124 PSD_Steigung_1_Attribute_kompl 1500;
BA_REL_ "GenSigTimeoutTime" BU_SG_REL_ MRR2023 SG_ 1124 PSD_Sys_Geometrieguete_erweitert 1500;
BA_REL_ "GenSigTimeoutTime" BU_SG_REL_ MRR2023 SG_ 1124 PSD_Steigung_2_Segment_ID 1500;
BA_REL_ "GenSigTimeoutTime" BU_SG_REL_ MRR2023 SG_ 1124 PSD_Attribut_5_ID 1500;
BA_REL_ "GenSigTimeoutTime" BU_SG_REL_ MRR2023 SG_ 1124 PSD_Ges_Geschwindigkeit_Std_Ende 1500;
BA_REL_ "GenSigTimeoutTime" BU_SG_REL_ MRR2023 SG_ 1124 PSD_Attribut_5_Offset 1500;
BA_REL_ "GenSigTimeoutTime" BU_SG_REL_ MRR2023 SG_ 1124 PSD_Steigung_2_Steigung 1500;
BA_REL_ "GenSigTimeoutTime" BU_SG_REL_ MRR2023 SG_ 1124 PSD_Sys_Quali_sonstige_Attribute 1500;
BA_REL_ "GenSigTimeoutTime" BU_SG_REL_ MRR2023 SG_ 1124 PSD_Ges_Ueberholverbot 1500;
BA_REL_ "GenSigTimeoutTime" BU_SG_REL_ MRR2023 SG_ 1124 PSD_Sys_Quali_Steigungen 1500;
BA_REL_ "GenSigTimeoutTime" BU_SG_REL_ MRR2023 SG_ 1124 PSD_Ges_Wechselverkehrszeichen 1500;
BA_REL_ "GenSigTimeoutTime" BU_SG_REL_ MRR2023 SG_ 1124 PSD_Attribut_5_Wert 1500;
BA_REL_ "GenSigTimeoutTime" BU_SG_REL_ MRR2023 SG_ 1124 PSD_Steigung_2_Vorz 1500;
BA_REL_ "GenSigTimeoutTime" BU_SG_REL_ MRR2023 SG_ 1124 PSD_Sys_Quali_Strassenkennz 1500;
BA_REL_ "GenSigTimeoutTime" BU_SG_REL_ MRR2023 SG_ 1124 PSD_Wechselverkehrszeichen_Typ 1500;
BA_REL_ "GenSigTimeoutTime" BU_SG_REL_ MRR2023 SG_ 1124 PSD_Baum_Ausrichtung 1500;
BA_REL_ "GenSigTimeoutTime" BU_SG_REL_ MRR2023 SG_ 1124 PSD_Steigung_2_Offset 1500;
BA_REL_ "GenSigTimeoutTime" BU_SG_REL_ MRR2023 SG_ 1124 PSD_Ges_Gesetzlich_Kategorie 1500;
BA_REL_ "GenSigTimeoutTime" BU_SG_REL_ MRR2023 SG_ 1124 PSD_Sys_Quali_Tempolimits 1500;
BA_REL_ "GenSigTimeoutTime" BU_SG_REL_ MRR2023 SG_ 1124 PSD_Attribute_Komplett_06 1500;
BA_REL_ "GenSigTimeoutTime" BU_SG_REL_ MRR2023 SG_ 1124 PSD_Ges_Gesetzlich_Zusatz 1500;
BA_REL_ "GenSigTimeoutTime" BU_SG_REL_ MRR2023 SG_ 1124 PSD_Sys_Quali_Vorfahrtsregelung 1500;
BA_REL_ "GenSigTimeoutTime" BU_SG_REL_ MRR2023 SG_ 1124 PSD_Ges_Verkehrszeichen_Quelle 1500;
BA_REL_ "GenSigTimeoutTime" BU_SG_REL_ MRR2023 SG_ 1124 PSD_Steigung_2_Attribute_kompl 1500;
BA_REL_ "GenSigTimeoutTime" BU_SG_REL_ MRR2023 SG_ 1124 PSD_Ges_Attribute_Komplett 1500;
BA_REL_ "GenSigTimeoutTime" BU_SG_REL_ MRR2023 SG_ 317 QFK_DynBegr_aktiv 500;
BA_REL_ "GenSigTimeoutTime" BU_SG_REL_ MRR2023 SG_ 317 QFK_Status 500;
BA_REL_ "GenSigTimeoutTime" BU_SG_REL_ MRR2023 SG_ 317 QFK_stAWV 500;
BA_REL_ "GenSigTimeoutTime" BU_SG_REL_ MRR2023 SG_ 317 QFK_stDSR 500;
BA_REL_ "GenSigTimeoutTime" BU_SG_REL_ MRR2023 SG_ 317 QFK_KruemmIst 500;
BA_REL_ "GenSigTimeoutTime" BU_SG_REL_ MRR2023 SG_ 317 QFK_KruemmIst_VZ 500;
VAL_ 2331595789 NR_FR_Object_09_ID 0 "No_object" 255 "Init" ;
VAL_ 2331595789 NR_FR_Object_09_ReferencePoint 0 "unknown" 1 "front_left" 2 "front_center" 3 "front_right" 4 "right_center" 5 "rear_right" 6 "rear_center" 7 "rear_left" 8 "left_center" 9 "object_center" 10 "any_side_center" 15 "Init" ;
VAL_ 2331595789 NR_FR_Object_09_PosX 16383 "Init" ;
VAL_ 2331595789 NR_FR_Object_09_PosXSD 255 "Init" ;
VAL_ 2331595789 NR_FR_Object_09_PosY 8191 "Init" ;
VAL_ 2331595789 NR_FR_Object_09_PosYSD 255 "Init" ;
VAL_ 2331595789 NR_FR_Object_09_vAbsX 4095 "Init" ;
VAL_ 2331595789 NR_FR_Object_09_vAbsXSD 63 "Init" ;
VAL_ 2331595789 NR_FR_Object_09_vAbsY 4095 "Init" ;
VAL_ 2331595789 NR_FR_Object_09_vAbsYSD 63 "Init" ;
VAL_ 2331595789 NR_FR_Object_09_aAbsX 511 "Init" ;
VAL_ 2331595789 NR_FR_Object_09_aAbsXSD 63 "Init" ;
VAL_ 2331595789 NR_FR_Object_09_aAbsY 511 "Init" ;
VAL_ 2331595789 NR_FR_Object_09_aAbsYSD 63 "Init" ;
VAL_ 2331595789 NR_FR_Object_09_DynamicState 0 "moving" 1 "stationary" 2 "stopped" 3 "Init" ;
VAL_ 2331595789 NR_FR_Object_09_YawAngle 4095 "Init" ;
VAL_ 2331595789 NR_FR_Object_09_YawAngleSD 511 "Init" ;
VAL_ 2331595789 NR_FR_Object_09_Width 255 "Init" ;
VAL_ 2331595789 NR_FR_Object_09_WidthSD 127 "Init" ;
VAL_ 2331595789 NR_FR_Object_09_Length 1023 "Init" ;
VAL_ 2331595789 NR_FR_Object_09_LengthSD 127 "Init" ;
VAL_ 2331595789 NR_FR_Object_09_Class 0 "unknown" 1 "reserved" 2 "reserved" 3 "pedestrian" 4 "reserved" 5 "bicycle" 6 "motorcycle" 7 "car" 8 "reserved" 9 "truck" 10 "reserved" 11 "reserved" 12 "reserved" 13 "reserved" 15 "Init" ;
VAL_ 2331595789 NR_FR_Object_09_ClassPlausib 15 "Init" ;
VAL_ 2331595789 NR_FR_Object_09_ExistProb 127 "Init" ;
VAL_ 2331595789 NR_FR_Object_09_Age 127 "Init" ;
VAL_ 2331595789 NR_FR_Object_09_YawRateAbs 4095 "Init" ;
VAL_ 2331595789 NR_FR_Object_09_YawRateAbsSD 63 "Init" ;
VAL_ 2331595789 NR_FR_Object_09_MeasurementState 0 "predicted" 1 "measured" ;
VAL_ 2331595789 NR_FR_Object_10_ID 0 "No_object" 255 "Init" ;
VAL_ 2331595789 NR_FR_Object_10_ReferencePoint 0 "unknown" 1 "front_left" 2 "front_center" 3 "front_right" 4 "right_center" 5 "rear_right" 6 "rear_center" 7 "rear_left" 8 "left_center" 9 "object_center" 10 "any_side_center" 15 "Init" ;
VAL_ 2331595789 NR_FR_Object_10_PosX 16383 "Init" ;
VAL_ 2331595789 NR_FR_Object_10_PosXSD 255 "Init" ;
VAL_ 2331595789 NR_FR_Object_10_PosY 8191 "Init" ;
VAL_ 2331595789 NR_FR_Object_10_PosYSD 255 "Init" ;
VAL_ 2331595789 NR_FR_Object_10_vAbsX 4095 "Init" ;
VAL_ 2331595789 NR_FR_Object_10_vAbsXSD 63 "Init" ;
VAL_ 2331595789 NR_FR_Object_10_vAbsY 4095 "Init" ;
VAL_ 2331595789 NR_FR_Object_10_vAbsYSD 63 "Init" ;
VAL_ 2331595789 NR_FR_Object_10_aAbsX 511 "Init" ;
VAL_ 2331595789 NR_FR_Object_10_aAbsXSD 63 "Init" ;
VAL_ 2331595789 NR_FR_Object_10_aAbsY 511 "Init" ;
VAL_ 2331595789 NR_FR_Object_10_aAbsYSD 63 "Init" ;
VAL_ 2331595789 NR_FR_Object_10_DynamicState 0 "moving" 1 "stationary" 2 "stopped" 3 "Init" ;
VAL_ 2331595789 NR_FR_Object_10_YawAngle 4095 "Init" ;
VAL_ 2331595789 NR_FR_Object_10_YawAngleSD 511 "Init" ;
VAL_ 2331595789 NR_FR_Object_10_Width 255 "Init" ;
VAL_ 2331595789 NR_FR_Object_10_WidthSD 127 "Init" ;
VAL_ 2331595789 NR_FR_Object_10_Length 1023 "Init" ;
VAL_ 2331595789 NR_FR_Object_10_LengthSD 127 "Init" ;
VAL_ 2331595789 NR_FR_Object_10_Class 0 "unknown" 1 "reserved" 2 "reserved" 3 "pedestrian" 4 "reserved" 5 "bicycle" 6 "motorcycle" 7 "car" 8 "reserved" 9 "truck" 10 "reserved" 11 "reserved" 12 "reserved" 13 "reserved" 15 "Init" ;
VAL_ 2331595789 NR_FR_Object_10_ClassPlausib 15 "Init" ;
VAL_ 2331595789 NR_FR_Object_10_ExistProb 127 "Init" ;
VAL_ 2331595789 NR_FR_Object_10_Age 127 "Init" ;
VAL_ 2331595789 NR_FR_Object_10_YawRateAbs 4095 "Init" ;
VAL_ 2331595789 NR_FR_Object_10_YawRateAbsSD 63 "Init" ;
VAL_ 2331595789 NR_FR_Object_10_MeasurementState 0 "predicted" 1 "measured" ;
VAL_ 2331595851 NR_FR_Structure_right_LatDist 511 "Init" ;
VAL_ 2331595851 NR_FR_Structure_right_Type 0 "inactive" 1 "continuous_structural" 2 "linked_structural" 3 "irregular_or_unknown" 4 "point" ;
VAL_ 2331595851 NR_FR_Structure_right_ExistProb 127 "Init" ;
VAL_ 2589284120 MFK_ORUDataIndex 0 "Init_no_data_is_transmitted" 1 "index_for_data" 2 "index_for_data" 3 "index_for_data" 4 "index_for_data" 5 "index_for_data" 6 "index_for_data" 7 "index_for_data" 8 "index_for_data" 9 "index_for_data" 10 "index_for_data" 11 "index_for_data" 12 "index_for_data" 13 "index_for_data" 14 "index_for_data" 15 "unused" ;
VAL_ 2589283656 ORU_Inventory 0 "Init" 1 "Inventory_Erstellung_nicht_aktiv" 2 "Inventory_Erstellung_aktiv" ;
VAL_ 2589283656 ORU_EM_Anfrage_freigegebeneNetze 0 "only_12V" 1 "networks_48V_and_12V" 2 "networks_HV_and_12V" 3 "networks_HV_and_48V_and_12V" ;
VAL_ 2589283656 ORU_Warnung 0 "keine_Anzeige" 1 "Update_unvollstaendig_Prio1" 2 "Update_fehlgeschlagen_Prio1" 3 "reserviert" ;
VAL_ 2589283656 ORU_Status 0 "IDLE" 1 "PENDING" 2 "PREPARATION" 3 "PREPARATION_HV" 4 "RUNNING" 5 "RUNNING_HV" 6 "PENDING_NOTREADY" 7 "FAILURE_POWERTRAIN_DISABLED" ;
VAL_ 2589284073 ORUG1_HVReleased 0 "HVECUNotReleased" 1 "HVECUReleased" ;
VAL_ 2589284073 ORUG1_Anforderung_HMS 0 "keine_Anforderung" 1 "halten" 2 "parken" 3 "halten_Standby" 4 "anfahren" 5 "Loesen_ueber_Rampe" 6 "Parken_mit_P" 7 "HMS_uebernehmen" ;
VAL_ 2589284073 ORUG1_Parken_beibehalten_HMS 0 "Parken_nicht_beibehalten" 1 "Parken_beibehalten" 2 "Init" 3 "Fehler" ;
VAL_ 2589284073 ORUG1_Warning 0 "Idle" 1 "Yellow" 2 "Red" 3 "Suppress" ;
VAL_ 2589284073 ORUG1_HVLock 0 "Idle" 1 "ActivateLock" 2 "ReleaseLock" ;
VAL_ 2589284074 ORUG2_GuardState 0 "Idle" 1 "DataErr" 2 "CountErr" 3 "Collecting" 4 "HwVerErr" 5 "Waiting" 6 "Ready" ;
VAL_ 2589284074 ORUG2_GuardInfo 0 "Idle" 1 "VehicleLockActive" 2 "HMSLocked" 4 "KLSLocked" 8 "PWRaLocked" 16 "PWRcLocked" 32 "HVLockActive" 64 "BCMeLocked" 128 "OCCLocked" 256 "DCDCLocked" 512 "WarningsSuppressed" 1024 "CrashDetected" 2048 "Buffer1Blocked" 4096 "Buffer2Blocked" 8192 "Buffer3Blocked" 16384 "reserved" ;
VAL_ 2589284074 ORUG2_TorqueLock 0 "Idle" 1 "ActivateLock" 2 "ReleaseLock" ;
VAL_ 525 PaCo_01_Sendestatus 0 "PaCo_01_im_langsamen_Zyklus" 1 "PaCo_01_im_schnellen_Zyklus" ;
VAL_ 525 PaCo_APS_TargetState 0 "Inactive" 1 "Active" 2 "Active_ReducedRange" 3 "Active_Muted" ;
VAL_ 525 PaCo_APSOPS_DetectionFront 0 "Detection_Inactive" 1 "Detection_Active" ;
VAL_ 525 PaCo_APSOPS_DetectionRear 0 "Detection_Inactive" 1 "Detection_Active" ;
VAL_ 525 PaCo_APSOPS_LED 0 "LED_Inactive" 1 "LED_Active" 2 "LED_Flashing" 3 "Error" ;
VAL_ 525 PaCo_OPS_TargetState 0 "OPS_Inactive" 1 "OPS_Active" 2 "OPS_Active_Muted" ;
VAL_ 525 PaCo_OPS_DrivingTube 0 "Inactive" 1 "Active" ;
VAL_ 525 PaCo_PLAIPA_InterventionStart 0 "Inactive" 1 "Active" ;
VAL_ 525 PaCo_PLAIPA_PLE 0 "Inactive" 1 "Active" ;
VAL_ 525 PaCo_PLAIPA_LED 0 "LED_Inactive" 1 "LED_Active" 2 "LED_Flashing" 3 "Error" ;
VAL_ 525 PaCo_PLAIPA_TargetState 0 "Inactive" 1 "Active_Visible" 2 "DeactBy_NoReason" 3 "DeactBy_Speed" 4 "DeactBy_PLAIPAButton" 5 "DeactBy_PGear" 6 "DeactBy_RGear" 7 "DeactBy_APSOPSoff" 8 "DeactBy_HeadunitVisualOff" 9 "DeactBy_End_Remote" 10 "Active_Remote" 11 "Active_Garage" ;
VAL_ 525 PaCo_PLAIPA_SwitchParkSlot 0 "NotToggle_ToNextParkingSlot" 1 "Toggle_ToNextParkingSlot" ;
VAL_ 525 PaCo_RBFMA_InterventionStrategy 0 "No_Intervention" 1 "Only_Braking" 2 "Only_Steering" 3 "Braking_And_Steering" ;
VAL_ 525 PaCo_VPS_TargetView 0 "NoView" 1 "RearView" 2 "FrontView" 3 "SV_Left" 4 "SV_Right" 5 "SV_Both" 6 "BirdView_2D" 7 "BirdView_3D" 8 "VirtualView" ;
VAL_ 525 PaCo_VPS_TargetMode 0 "NoMode" 1 "Parking_Manual" 2 "Parking_Automatic" 3 "Crossing" 4 "BumperFocus" 5 "TrailerAssist_Manual" 6 "SV_Focus_Front" 7 "SV_Focus_Rear" 8 "SV_Focus_All" 9 "Legal" 10 "TrailerAssist_AAA" 11 "TrailerAssist_ARA" 12 "Smartphone" 13 "VirtualView" 14 "BumperFocus_AWC" ;
VAL_ 525 PaCo_VPS_LED 0 "LED_Inactive" 1 "LED_Active" 2 "LED_Flashing" 3 "Error" ;
VAL_ 525 PaCo_VPS_TargetState 0 "Inactive" 1 "Active" 2 "data_recording" ;
VAL_ 525 PaCo_VPS_TargetBirdview 0 "NoBirdview" 1 "Birdview_2D" 2 "Birdview_3D" 3 "Birdview_Autoakt" 4 "OPS_only" 5 "TPA_Trajectory" ;
VAL_ 525 PaCo_VPS_DarkenVideo 0 "Inactive" 1 "Active" ;
VAL_ 525 PaCo_VPS_PLE 0 "Inactive" 1 "Active" ;
VAL_ 525 PaCo_ARA_TargetState 0 "Inactive" 1 "Active" ;
VAL_ 525 PaCo_RCTA_InterventionStrategy 0 "NoIntervention" 1 "Braking" ;
VAL_ 525 PaCo_MainState 0 "Init" 1 "InOperation_NoError" 7 "Fehler" ;
VAL_ 525 PaCo_RCTA_Warning 0 "RCTA_Inactive" 1 "RCTA_Active" 2 "RCTA_Active_Muted" 3 "RCTA_Off" ;
VAL_ 525 PaCo_APS_AudioLowering 0 "Inactive" 1 "Active" ;
VAL_ 525 PaCo_VPS_TargetRVCscreen 0 "noScreen" 1 "Fullscreen" 2 "Splitscreen_SidebySide" ;
VAL_ 525 PaCo_AAA_Intervention 0 "No_Intervention" 1 "Intervention" ;
VAL_ 525 PaCo_AAA_TargetState 0 "Inactive" 1 "Active" 2 "remoteActive" ;
VAL_ 525 PaCo_TPA_TargetState 0 "Inactive" 1 "Active_Visible" 2 "DeactBy_NoReason" 8 "DeactBy_HeadunitVisualOff" ;
VAL_ 525 PaCo_DiETa_LED 0 "LED_Inactive" 1 "LED_Active" 2 "LED_Flashing" 3 "Error" ;
VAL_ 525 PaCo_RA_InterventionStart 0 "Inactive" 1 "Active" ;
VAL_ 525 PaCo_VPS_TargetCarOverlay 0 "noCarOverlay" 1 "normalCarOverlay" 2 "transparentCarOverlay" ;
VAL_ 525 PaCo_VPS_TargetBowl 0 "NoBowl" 1 "Preset_1" 2 "Preset_2" 3 "Preset_3" 4 "Preset_4" 5 "Preset_5" 6 "Preset_6" 7 "Preset_7" 8 "Preset_8" 9 "Preset_9" 10 "Modified" 11 "Preset_AWC" 12 "Preset_IPA" 13 "Preset_ParkingFront" 14 "Preset_ParkingRear" 15 "Preset_RPA" 16 "Preset_CarWash" ;
VAL_ 525 PaCo_VPS_TargetGraphicOverlay 0 "NoGraphic" 1 "IPA" 2 "ARA" 3 "AAA" 4 "TrailerAssist" 5 "AR" 6 "AWC" 7 "Parkbox" 8 "CarWash" 9 "RPA" 10 "TPA_Training" 11 "TPA_AutomatedDriving" 12 "TPA_Remote" 13 "legal" ;
VAL_ 525 PaCo_RA_Targetstate 0 "inactive" 1 "standby" 2 "activation" 3 "active" 4 "continue" 5 "DeactBy_NoReason" 6 "DeactBy_Speed" 7 "DeactBy_Button" 8 "DeactBy_HeadunitVisualOff" 9 "DeactBy_PGear" 10 "DeactBy_eCall" 11 "DeactBy_APSOPSoff" ;
VAL_ 525 PaCo_AEBPR_InterventionStrategy 0 "Inactive" 1 "Active" ;
VAL_ 525 PaCo_AEBPR_ImplementationRBFMA 0 "RBFMA_not_implemented" 1 "RBFMA_implemented" ;
VAL_ 525 PaCo_RBFMA_ImplementationAEBPR 0 "AEBPR_not_implemented" 1 "AEBPR_implemented" ;
VAL_ 525 PaCo_ARA_InterventionStart 0 "Inactive" 1 "Active" ;
VAL_ 518 Parken_BKD_Anf 14 "Neutralwert" 15 "Fehler" ;
VAL_ 518 Parken_Verz_Anf 126 "Neutralwert" 127 "reserved" ;
VAL_ 518 Parken_Prefill_Anf 0 "keine_Anforderung" 1 "Prefill_Anforderung" ;
VAL_ 518 Parken_Warnruck_Anf 0 "Keine_Anforderung" 1 "schwacher_Warnruck" 2 "mittlerer_Warnruck" 3 "starker_Warnruck" ;
VAL_ 518 Parken_Verz_Anf_ASIL 0 "ASIL_QM" 1 "ASIL_A" 2 "ASIL_B" 3 "ASIL_C" ;
VAL_ 518 Parken_Warnruckeln_Anf 0 "keine_Anforderung" 1 "schwaches_Warnruckeln" 2 "mittleres_Warnruckeln" 3 "starkes_Warnruckeln" ;
VAL_ 518 Parken_beibehalten 0 "Parken_nicht_beibehalten" 1 "Parken_beibehalten" 2 "Init" 3 "Fehler" ;
VAL_ 518 Parken_Anforderung_HMS 0 "keine_Anforderung" 1 "Halten" 2 "Parken" 3 "Halten_standby" 4 "Anfahren" 5 "Loesen_ueber_Rampe" 6 "Parken_mit_P" 7 "HMS_uebernehmen" ;
VAL_ 518 Parken_Fahrbereitschaft_Anf 0 "keine_Anforderung" 1 "Anforderung_Fahrbereitschaft" ;
VAL_ 518 Parken_Motorlauf_Anf 0 "Keine_Anforderung" 1 "Motor_aus" 2 "Motor_an" 3 "Weiterlauf_Fahreruebernahme" ;
VAL_ 518 IPA_TPA_ausgerichtetes_Parken 0 "nicht_aktiv" 1 "aktiv" ;
VAL_ 518 Parken_Notstopp_Anf 0 "Ueberwachung_aus" 1 "Ueberwachung_ein" 2 "Notstopp_ausloesen" ;
VAL_ 518 Parken_Anhalteweg_Anf 1022 "Neutralwert" 1023 "Fehler" ;
VAL_ 518 Parken_aktives_System 0 "kein_aktives_System" 1 "Manoevrierassistent_Ueberwachung" 2 "IPA" 3 "fernbedientes_Parken" 4 "Manoevrierassistent" 5 "Manoevrierassistent_quer" 6 "Anhaengerrangierassistent" 7 "fernbedienter_Anhaengerrangierassistent" ;
VAL_ 518 Parken_max_Beschleunigung 0 "Inaktiv" 122 "Init" 127 "Fehler" ;
VAL_ 518 Parken_Blinker_li_Anf 0 "keine_Anforderung" 1 "Blinker_links_aktivieren" ;
VAL_ 518 Parken_Sollbeschleunigung 0 "Neutralwert" ;
VAL_ 518 Parken_Blinker_re_Anf 0 "keine_Anforderung" 1 "Blinker_rechts_aktivieren" ;
VAL_ 518 Parken_Status_IPA_TSK 1 "IPA_TSK_Init" 2 "IPA_TSK_Fehler" 4 "IPA_TSK_aktivierbar" 5 "IPA_TSK_pausiert" 6 "IPA_TSK_aktiv" 8 "IPA_TSK_funktionsbereit" ;
VAL_ 518 Parken_erhoehtes_Moment 0 "keine_Anforderung" 1 "Anforderung_Rampe1" 2 "Anforderung_Rampe2" 3 "Anforderung_Rampe3" 4 "Anforderung_Rampe4" 5 "Anforderung_Rampe5" 6 "Anforderung_Rampe6" 7 "Anforderung_Rampe7" 8 "Anforderung_Rampe8" 9 "Anforderung_Rampe9" 10 "Anforderung_Rampe10" 11 "Anforderung_Rampe11" 12 "Anforderung_Rampe12" 13 "Anforderung_Rampe13" 14 "Anforderung_Rampe14" 15 "Anforderung_Rampe15" ;
VAL_ 518 Parken_max_Geschwindigkeit 0 "Inaktiv" 251 "Init" 255 "Fehler" ;
VAL_ 518 Parken_Soll_Anhalteweg_Anf 1022 "Neutralwert" 1023 "Fehler" ;
VAL_ 518 Parken_Fahrstufenwunsch 0 "Init" 1 "Fahrstufe_beibehalten" 2 "Position_R" 3 "Position_D" 4 "Position_N" ;
VAL_ 518 Parken_Schleichfahrt_Anf 0 "keine_Anforderung" 1 "Schleichfahrt_angefordert" ;
VAL_ 518 Parken_Bordstein_Winkel 0 "Neutralwert" ;
VAL_ 518 IPA_TPA_Remote 0 "nicht_aktiv" 1 "aktiv" 2 "Uebergabe" 3 "Uebernahme" ;
VAL_ 518 IPA_TPA_Remote_Anf 0 "keine_Anforderung" 1 "Remote_Anforderung" 2 "Remote_Zug_rueckgaengig" ;
VAL_ 518 IPA_TPA_Fehler 0 "Init_kein_Fehler" 1 "IPA_Systemfehler" 2 "RPA_Systemfehler" 3 "temporaerer_Fehler" 4 "sonstiger_Fehler" ;
VAL_ 518 IPA_TPA_Abbruch 0 "Init_kein_Abbruch" 1 "Hindernis" 2 "Manoever_nicht_fahrbar" 3 "Abbruch_mit_Wiederaufnahme" 4 "Abbruch_ohne_Wiederaufnahme" 5 "temporaerer_Fehler" 6 "sonstiger_Fehler" ;
VAL_ 518 IPA_TPA_Status 0 "deaktiv" 1 "Init" 4 "startbereit" 6 "Regelung_aktiv" 7 "Parkvorgang_abgeschlossen" 8 "funktionsbereit" 9 "Unterbrechung" 10 "Abbruch" 15 "Error" ;
VAL_ 796 PCS_Li_MessZeitpunkt 8191 "Init" ;
VAL_ 796 PCS_Li_CW 126 "Init" 127 "Fehler" ;
VAL_ 796 PCS_Li_CS 126 "Init" 127 "Fehler" ;
VAL_ 796 PCS_Li_TTC 1022 "Init" 1023 "Fehler" ;
VAL_ 796 PCS_Li_Status 0 "Init" 1 "Aktiv" 2 "Nicht_verfuegbar" 3 "Eingeschraenkt_Kalibrierung" 4 "Eingeschraenkt_Sensorsicht" 5 "Eingeschraenkt_Anhaengerbetrieb" 6 "Eingeschraenkt_Systemgrenze" 7 "Eingeschraenkt_Abschleppen" 15 "Fehler" ;
VAL_ 797 PCS_Re_MessZeitpunkt 8191 "Init" ;
VAL_ 797 PCS_Re_CW 126 "Init" 127 "Fehler" ;
VAL_ 797 PCS_Re_CS 126 "Init" 127 "Fehler" ;
VAL_ 797 PCS_Re_TTC 1022 "Init" 1023 "Fehler" ;
VAL_ 797 PCS_Re_Status 0 "Init" 1 "Aktiv" 2 "Nicht_verfuegbar" 3 "Eingeschraenkt_Kalibrierung" 4 "Eingeschraenkt_Sensorsicht" 5 "Eingeschraenkt_Anhaengerbetrieb" 6 "Eingeschraenkt_Systemgrenze" 7 "Eingeschraenkt_Abschleppen" 15 "Fehler" ;
VAL_ 2527679498 Perso_Kontonummer 0 "kein_Benutzerkonto" 1 "Benutzerkonto_1" 2 "Benutzerkonto_2" 3 "Benutzerkonto_3" 4 "Benutzerkonto_4" 5 "Benutzerkonto_5" 6 "Benutzerkonto_6" 7 "Benutzerkonto_7" ;
VAL_ 2527679498 Perso_Steuerung 0 "keine_Steuerung" 1 "Reset_alle_Konten" 2 "Reset_aktives_Konto" 3 "Kopiere_aktives_Konto_nach" 4 "Wiederherstellen_aktives_Konto" 5 "Aktivieren_aktives_Konto" 6 "Reset_Konto" 7 "Reset_alle_Fahrer" 8 "Reset_aktiver_Fahrer" 9 "Reset_Fahrer" ;
VAL_ 2527679498 Perso_Steuerungsparameter 0 "kein_Parameter" 1 "Benutzerkonto_1" 2 "Benutzerkonto_2" 3 "Benutzerkonto_3" 4 "Benutzerkonto_4" 5 "Benutzerkonto_5" 6 "Benutzerkonto_6" 7 "Benutzerkonto_7" ;
VAL_ 2527679498 Perso_Status 0 "deaktiviert" 1 "PSO_1x_aktiviert" 2 "PSO_2x_aktiviert" ;
VAL_ 2527679498 Perso_Bedienstelle 0 "Init" 1 "Kombiinstrument" 2 "ABT" ;
VAL_ 2527679498 Perso_Freigabe_Verstellung 0 "Init" 1 "freigegeben" ;
VAL_ 2527679498 Perso_Aktiv 0 "deaktiviert" 1 "aktiviert" ;
VAL_ 2527679498 IAA_PSO_wake_up 0 "wake_up_inactive" 1 "wake_up_active" ;
VAL_ 2527679498 Perso_Fahrernummer 0 "kein_Fahrer" 1 "Fahrer_1" 2 "Fahrer_2" 3 "Fahrer_3" 4 "Fahrer_4" 5 "Fahrer_5" 6 "Fahrer_6" 7 "Fahrer_7" ;
VAL_ 2527679498 Perso_Schreibschutz 0 "Schreibschutz_deaktiviert" 1 "Schreibschutz_aktiviert" ;
VAL_ 1031 PLAIPA_PaCo_ParkingSlots_02 0 "Nothing" 1 "One_ParkingSlot" 2 "Two_ParkingSlots" 3 "Three_ParkingSlots" 4 "Four_ParkingSlots" 5 "Five_ParkingSlots" 6 "Six_ParkingSlots" 7 "Seven_ParkingSlots" 8 "Eight_ParkingSlots" ;
VAL_ 1031 RA_PaCo_USSensorStatus 0 "No_Error" 1 "Sensor_Defect" 2 "Sensor_Contaminated" ;
VAL_ 1031 RA_PaCo_MainState 0 "Init" 1 "InOperation_NoError" 2 "Fehler" ;
VAL_ 1031 RA_PaCo_FunctionState 0 "Available" 1 "Trajectory_Recording" 2 "Activating" 3 "Reversing_In_Intervention" 4 "Completed" 5 "Cancelled" 6 "Driver_TakingOver" 7 "Not_Available" ;
VAL_ 1031 RA_PaCo_InterventionPossible 0 "Not_Possible" 1 "Possible_Or_Active" ;
VAL_ 1031 RA_PaCo_UnavailableReason 0 "No_Reason" 1 "EmergencyAssist_active" 2 "Offroad_active" 3 "ASR_ESP_inactive" 4 "SystemFailure" 5 "FunctionDefective" 6 "AnyDoorOpen" 7 "TrunkOpen" 8 "GeoFencingRA" 9 "SpeedOutOfRange" 10 "TrajectoryNotAvailable" 11 "TrailerHitched" ;
VAL_ 1031 PLAIPA_PaCo_RemoteActivatable 0 "NotActivatable" 1 "Activatable" 2 "NotActivatable_temp" 3 "NotActivatable_geoFencing" 4 "NotActivatable_defect" ;
VAL_ 1031 PLAIPA_PaCo_GarageActivatable 0 "NotActivatable" 1 "Activatable" ;
VAL_ 1031 RPA_Anf_Sonder_Funktion_Status 0 "Init" 1 "Anforderung" 2 "Aktiv" 3 "Beendet" 4 "Abbruch_Klemmenabschaltung" ;
VAL_ 1031 RPA_Anf_Sonder_Klemme_15 0 "Init" 1 "KL_15_HW" 3 "KL_15_HW_UND_CAN" ;
VAL_ 1031 RPA_Anf_WFS_Freigabe 0 "Keine" 1 "Uneingeschraenkt" 2 "Eingeschraenkt" ;
VAL_ 1031 PLAIPA_PaCo_SwitchPossible 0 "Not_Possible" 1 "Possible" ;
VAL_ 1031 PLAIPA_PaCo_ParkingSlots 0 "Nothing" 1 "One_ParkingSlot" 2 "Two_ParkingSlots" 3 "Three_ParkingSlots" 4 "Four_ParkingSlots" ;
VAL_ 1031 PLAIPA_PaCo_UnavailableReason 0 "No_Reason" 1 "EmergencyAssist_active" 2 "Offroad_active" 3 "TooSmall_ParkOutSlot" 4 "ASR_ESP_inactive" 5 "SlidingDoor_open" 6 "LeafDoor_open" 7 "SystemFailure" 8 "FunctionDefective" 9 "AnyDoorOpen" 10 "TrunkOpen" 11 "GeoFencingIPA" ;
VAL_ 1031 PLAIPA_PaCo_InterventionPossible 0 "Not_Possible" 1 "Possible_Or_Active" ;
VAL_ 1031 PLAIPA_PaCo_MainState 0 "Init" 1 "InOperation_NoError" 7 "Fehler" ;
VAL_ 1031 PLAIPA_PaCo_FunctionState 0 "Resume_Possible" 1 "Park_In_SearchMode" 2 "Park_In_SlotFound" 3 "Park_Out_SlotFound" 4 "Park_In_Intervention" 5 "Park_Out_Intervention" 6 "Standby" 7 "Completed" 8 "Cancelled" 9 "ParkIn_NoPass_FrontLeft" 10 "ParkIn_NoPass_FrontRight" 11 "ParkIn_NoPass_BackLeft" 12 "ParkIn_NoPass_BackRight" 13 "Not_Activatable" 14 "Remote_Activation" 15 "Remote_HandingOver" 16 "Remote_In_Intervention" 17 "Remote_Out_Intervention" ;
VAL_ 1031 PLAIPA_PaCo_PLEPossible 0 "Not_Possible" 1 "Possible" ;
VAL_ 1031 PLAIPA_PaCo_Button 0 "Init_or_not_equipped" 1 "Button_not_pressed" 2 "Button_pressed_debounced" 3 "Error" ;
VAL_ 1122 PSD_Segment_ID 0 "keine Segmentinformationen vorhanden" 1 "Fehlerwert" ;
VAL_ 1122 PSD_Vorgaenger_Segment_ID 0 "keine Segmentinformation vorhanden" 1 "Fehlerwert" ;
VAL_ 1122 PSD_Strassenkategorie 0 "Rest_Feldweg_Schotterweg_Privatweg" 1 "Ortsstraße" 2 "Kreisstraße" 3 "Landstraße" 4 "Bundesstraße" 5 "Autobahn" 7 "Init" ;
VAL_ 1122 PSD_Endkruemmung 255 "Gerade" ;
VAL_ 1122 PSD_Endkruemmung_Vorz 0 "Kruemmung_positiv" 1 "Kruemmung_negativ" ;
VAL_ 1122 PSD_Idenditaets_ID 0 "keine_Segment_Informationen_vorhanden" 1 "Fehler" ;
VAL_ 1122 PSD_ADAS_Qualitaet 0 "keine_ADAS_Qualitaet" 1 "ADAS_Qualitaet" ;
VAL_ 1122 PSD_wahrscheinlichster_Pfad 0 "Pfad_mit_geringer_Wahrscheinlichkeit" 1 "wahrscheinlichster_Pfad" ;
VAL_ 1122 PSD_Geradester_Pfad 0 "nicht_geradester_PFad" 1 "geradester_Pfad" ;
VAL_ 1122 PSD_Fahrspuren_Anzahl 0 "Einbahnstrasse_in_falsche_Richtung" 1 "eine_Fahrspur" 2 "zwei_Fahrspuren" 3 "drei_Fahrspuren" 4 "vier_Fahrspuren" 5 "fuenf_Fahrspuren" 6 "sechs_Fahrspuren" 7 "mehr_als_sechs_Fahrspuren" ;
VAL_ 1122 PSD_Bebauung 0 "ausserhalb_bebauten_Gebietes" 1 "innerhalb_bebauten_Gebietes" ;
VAL_ 1122 PSD_Segment_Komplett 0 "Segment_Attribute_nicht_komplett" 1 "Segment_Attribute_komplett" ;
VAL_ 1122 PSD_Rampe 0 "Strasse_mit_Gegenverkehr" 1 "Auffahrt_Einbahnstr" 2 "Abfahrt_Einbahnstr" 3 "Einbahnstrasse" ;
VAL_ 1122 PSD_Anfangskruemmung 255 "Gerade" ;
VAL_ 1122 PSD_Anfangskruemmung_Vorz 0 "positiv" 1 "negativ" ;
VAL_ 1122 PSD_Abzweigerichtung 0 "rects_abzweigende_Strasse" 1 "links_abzweigende_Strasse" ;
VAL_ 1123 PSD_Pos_Segment_ID 0 "keine Position gegeben" 1 "Fehlerwert" ;
VAL_ 1123 PSD_Pos_Standort_Eindeutig 0 "mehrdeutiger_Standort" 1 "eindeutiger_Standort" ;
VAL_ 1123 PSD_Pos_Fehler_Laengsrichtung 0 "Init" 1 "< 2m" 2 "< 5m" 3 "< 10m" 4 "< 20m" 5 "< 50m" 6 "> 50m" 7 "Off-Road" ;
VAL_ 1123 PSD_Pos_Fahrspur 0 "unbekannt" 1 "Erste_Spur_von_rechts" 2 "Zweite_Spur_von_rechts" 3 "Dritte_Spur_von_rechts" 4 "Vierte_Spur_von_rechts" 5 "Fuenfte_Spur_von_rechts" 6 "Sechte_Spur_von_rechts" 7 "Siebte_oder_weitere_Spur_von_rechts" ;
VAL_ 1123 PSD_Attribut_Segment_ID_05 0 "keine_Segment_Information" 1 "Fehler" ;
VAL_ 1123 PSD_Attribut_1_ID 0 "keine_Information" ;
VAL_ 1123 PSD_Attribut_2_ID 0 "keine_Information" ;
VAL_ 1123 PSD_Attribute_Komplett_05 0 "Attribute_nicht_komplett" 1 "Attribute_komplett" ;
VAL_ 1124 PSD_06_Mux 0 "Init" ;
VAL_ 1124 PSD_Sys_Segment_ID 0 "keine Segmentinformationen vorhanden" 1 "nicht zulaessig" ;
VAL_ 1124 PSD_Attribut_Segment_ID 0 "keine_Segment_Information_vorhanden" 1 "Fehler" ;
VAL_ 1124 PSD_Ges_Segment_ID 0 "keine Segmentinformationen vorhanden" 1 "nicht zulaessig" ;
VAL_ 1124 PSD_Baum_Laenge_VZ 0 "Ost" 1 "West" ;
VAL_ 1124 PSD_Steigung_1_Segment_ID 0 "keine_Segment_Information_vorhanden" 1 "Fehler" ;
VAL_ 1124 PSD_Baum_Laenge 33554431 "keine_GPS_Information" ;
VAL_ 1124 PSD_Attribut_3_ID 0 "keine_Information" ;
VAL_ 1124 PSD_Steigung_1_A_Steigung 126 "mehr_als_15_Prozent" 127 "Steigung_unbekannt" ;
VAL_ 1124 PSD_Ges_Geschwindigkeit 0 "Kein Geschwindigkeitsgebot" 1 "0 km/h < v_max <  5 km/h" 2 "5 km/h < v_max < 10km/h" 3 "10 km/h < v_max < 15 km/h" 4 "15 km/h < v_max < 20 km/h" 5 "20 km/h < v_max < 25 km/h" 6 "25 km/h < v_max < 30 km/h" 7 "30 km/h < v_max < 35 km/h" 8 "35 km/h < v_max < 40 km/h" 9 "40 km/h < v_max < 45 km/h" 10 "45 km/h < v_max < 50 km/h" 11 "50 km/h < v_max < 60 km/h" 12 "60 km/h < v_max < 70 km/h" 13 "70 km/h < v_max < 80 km/h" 14 "80 km/h < v_max < 90 km/h" 15 "90 km/h < v_max < 100 km/h" 16 "100 km/h < v_max < 110 km/h" 17 "110 km/h < v_max < 120 km/h" 18 " 120 km/h < v_max < 130 km/h" 19 "130 km/h < v_max < 140 km/h" 20 "140 km/h < v_max < 150 km/h" 21 "150 km/h < v_max < 160 km/h" 22 "160 km/h < v_max" 23 "Geschwindigkeitsgebot aufgehoben" 24 "..0x1F ungültig" ;
VAL_ 1124 PSD_Steigung_1_A_Vorz 0 "Gefaelle" 1 "Steigung" ;
VAL_ 1124 PSD_Sys_Geschwindigkeit_Einheit 0 "km/h" 1 "mph" ;
VAL_ 1124 PSD_Sys_Verkehrsrichtung 0 "Rechtsverkehr" 1 "Linksverkehr" ;
VAL_ 1124 PSD_Sys_Geometrieguete 0 "Geringe_Guete" 1 "tbd" 2 "tbd" 3 "Hohe_Guete" ;
VAL_ 1124 PSD_Sys_Mapmatchingguete 0 "geringe_Guete" 1 "res" 2 "res" 3 "hohe_Guete" ;
VAL_ 1124 PSD_Ges_Typ 0 "Geschw_Klasse_des_Kartendatensuppliers" 1 "Explizit_abgeleiteten_Begrenzung" 2 "Durch_Gesetzg_vorgeg_allgem_Gebot_fuer_uebertr_Rahmenbed" 3 "Init" ;
VAL_ 1124 PSD_Sys_Alter_Karte 0 "kleiner_1_Jahr" 1 "1_Jahr" 2 "2_Jahre" 3 "3_Jahre" 4 "4_Jahre" 5 "5_Jahre" 6 "6_Jahre" 7 "groesser_7_Jahre" ;
VAL_ 1124 PSD_Ges_Spur_Geschw_Begrenzung 0 "Gebot_fuer_alle_spuren_gueltig" ;
VAL_ 1124 PSD_Steigung_1_B_Steigung 126 "mehr_als_15_Prozent" 127 "Steigung_unbekannt" ;
VAL_ 1124 PSD_Attribut_4_ID 0 "keine_Information" ;
VAL_ 1124 PSD_Sys_Zielfuehrung 0 "Zielfuehrung nicht aktiv" 1 "Zielfuehrung aktiv" ;
VAL_ 1124 PSD_Sys_US_State 0 "kein_US_State" 1 "Alabama" 2 "Alaska" 3 "Arkansas" 4 "Arizona" 5 "California" 6 "Colorado" 7 "Conneticut" 8 "District_of_Columbia" 9 "Delaware" 10 "Florida" 11 "Georgia" 12 "Hawaii" 13 "Idaho" 14 "Illinois" 15 "Iowa" 16 "Indiana" 17 "Kansas" 18 "Kentucky" 19 "Louisiana" 20 "Massachusetts" 21 "Maryland" 22 "Maine" 23 "Michigan" 24 "Minnesota" 25 "Missouri" 26 "Mississippi" 27 "Montana" 28 "North_Carolina" 29 "North_Dakota" 30 "Nebraska" 31 "Nevada" 32 "New_Hampshire" 33 "New_Jersey" 34 "New_Mexico" 35 "New_York" 36 "Ohio" 37 "Oklahoma" 38 "Oregon" 39 "Pennsylvania" 40 "Puerto_Rico" 41 "Rhode_Island" 42 "South_Carolina" 43 "South_Dakota" 44 "Tennessee" 45 "Texas" 46 "Utah" 47 "Virginia" 48 "Virgin_Islands" 49 "Vermont" 50 "Washington" 51 "Wisconsin" 52 "West_Virginia" 53 "Wyoming" ;
VAL_ 1124 PSD_Ges_Geschwindigkeit_Gespann 0 "alle Fahrzeuge" 1 "PKW mit Gespann" 2 "LKW, Busse, etc." ;
VAL_ 1124 PSD_Baum_Breite_VZ 0 "Nord" 1 "Sued" ;
VAL_ 1124 PSD_Ges_Geschwindigkeit_Witter 0 "Witterungsunabhängig" 1 "Nässe, Regen, Niederschlag" 2 "Glätte" 3 "Nebel" ;
VAL_ 1124 PSD_Steigung_1_B_Vorz 0 "Gefaelle" 1 "Steigung" ;
VAL_ 1124 PSD_Ges_Geschwindigkeit_Tag_Anf 0 "kein Beginn definiert" 1 "Montag" 2 "Dienstag" 3 "Mittwoch" 4 "Donnerstag" 5 "Freitag" 6 "Samstag" 7 "Sonntag" ;
VAL_ 1124 PSD_Ges_Geschwindigkeit_Tag_Ende 0 "kein Ende definiert" 1 "Montag" 2 "Dienstag" 3 "Mittwoch" 4 "Donnerstag" 5 "Freitag" 6 "Samstag" 7 "Sonntag" ;
VAL_ 1124 PSD_Sys_Quali_verfuegbar 0 "Qualitaetskriterien_nicht_verfuegbar" 1 "Qualitaetskriterien_verfuegbar" ;
VAL_ 1124 PSD_Sys_Zielfuehrung_geaendert 0 "Zielfuehrung_nicht_geaendert" 1 "Zielfuehrung_geaendert" ;
VAL_ 1124 PSD_Ges_Geschwindigkeit_Std_Anf 25 "kein Beginn für stundenweise Einschränkungen" ;
VAL_ 1124 PSD_Steigung_1_Attribute_kompl 0 "Steigungen_nicht_komplett" 1 "Steigungen_komplett" ;
VAL_ 1124 PSD_Sys_Geometrieguete_erweitert 0 "Init" ;
VAL_ 1124 PSD_Steigung_2_Segment_ID 0 "keine_Segment_Information_vorhanden" 1 "Fehler" ;
VAL_ 1124 PSD_Attribut_5_ID 0 "keine_Information" ;
VAL_ 1124 PSD_Ges_Geschwindigkeit_Std_Ende 25 "kein Ende für stundenweise Einschränkungen" ;
VAL_ 1124 PSD_Steigung_2_Steigung 126 "mehr_als_15_Prozent" 127 "Steigung_unbekannt" ;
VAL_ 1124 PSD_Ges_Ueberholverbot 0 "kein Überholverbot" 1 "alle Fahrzeuge" 2 "Überholverbot für PKW mit Gespann" 3 "Überholverbot für LKW, Busse, etc." ;
VAL_ 1124 PSD_Ges_Wechselverkehrszeichen 0 "Kein Wechselverkehrszeichen" 1 "Wechselverkehrszeichen links" 2 "Wechselverkehrszeichen rechts" 3 "Wechselverkehrszeichen links und rechts" 4 "Wechselverkerhszeichen über der Fahrbahn" ;
VAL_ 1124 PSD_Steigung_2_Vorz 0 "Gefaelle" 1 "Steigung" ;
VAL_ 1124 PSD_Wechselverkehrszeichen_Typ 0 "kein_Wechselverkehrszeichen" 1 "LED_Wechselverkehrszeichen" 2 "nicht_LED_Wechselverkehrszeichen" ;
VAL_ 1124 PSD_Ges_Gesetzlich_Kategorie 0 "kein_legales_Verbot" 1 "innerorts" 2 "ausserorts" 3 "Autobahn" ;
VAL_ 1124 PSD_Attribute_Komplett_06 0 "Attribute_nicht_komplett" 1 "Attribute_komplett" ;
VAL_ 1124 PSD_Ges_Gesetzlich_Zusatz 0 "kein_Zusatz_zu_legalem_Gebot" 1 "Anhaenger_Klasse_1" 2 "Anhaenger_Klasse_2" ;
VAL_ 1124 PSD_Ges_Verkehrszeichen_Quelle 0 "VZA_kein_Onlinedienst" 1 "nur_VZA" 2 "nur_VZO" 3 "VZA_und_VZO" ;
VAL_ 1124 PSD_Steigung_2_Attribute_kompl 0 "Steigungen_nicht_komplett" 1 "Steigungen_komplett" ;
VAL_ 1124 PSD_Ges_Attribute_Komplett 0 "Attribute_nicht_komplett" 1 "Attribute_komplett" ;
VAL_ 317 QFK_01_Sendestatus 0 "langsamer_Zyklus" 1 "schneller_Zyklus" ;
VAL_ 317 QFK_stEingriffBr 0 "kein_Eingriff" 1 "Eingriff_aktiv" ;
VAL_ 317 QFK_DynBegr_aktiv 0 "nicht_aktiv" 1 "aktiv" ;
VAL_ 317 QFK_Anf_Giermomoffset_VZ 0 "positiv" 1 "negativ" ;
VAL_ 317 QFK_Status 1 "Init" 2 "Bereit" 3 "Gesperrt" 4 "Eingriff" 5 "Abbruch" 6 "FehlerME" 7 "FehlerOE" 12 "EingriffED" 13 "Eingriff_HandsOff" ;
VAL_ 317 QFK_stHCA 0 "Deaktiv" 1 "Init" 2 "Bereit" 3 "Gesperrt" 4 "Eingriff" 5 "Abbruch" 6 "FehlerME" 7 "FehlerOE" 12 "EingriffED" ;
VAL_ 317 QFK_stPLA 0 "Deaktiv" 1 "Init" 2 "Bereit" 3 "Gesperrt" 4 "Eingriff" 5 "Abbruch" 6 "FehlerME" 7 "FehlerOE" 12 "EingriffED" ;
VAL_ 317 QFK_stAWV 0 "Deaktiv" 1 "Init" 2 "Bereit" 3 "Gesperrt" 4 "Eingriff" 5 "Abbruch" 6 "FehlerME" 7 "FehlerOE" 12 "EingriffED" ;
VAL_ 317 QFK_stDSR 0 "Deaktiv" 1 "Init" 2 "Bereit" 3 "Gesperrt" 4 "Eingriff" 5 "Abbruch" 6 "FehlerME" 7 "FehlerOE" 12 "EingriffED" ;
VAL_ 317 QFK_ZPosIst_VZ 0 "positiv" 1 "negativ" ;
VAL_ 317 QFK_KrIst_VZ 0 "positiv" 1 "negativ" ;
VAL_ 317 QFK_IstKraft_VZ 0 "positiv" 1 "negativ" ;
VAL_ 317 QFK_KruemmIst_VZ 0 "positiv" 1 "negativ" ;
VAL_ 317 QFK_IstKraftNiveau_VZ 0 "positiv" 1 "negativ" ;
VAL_ 317 QFK_ZPosIst 65535 "Inaktiv" ;
VAL_ 317 QFK_stMA 0 "Deaktiv" 1 "Init" 2 "Bereit" 3 "Gesperrt" 4 "Eingriff" 5 "Abbruch" 6 "FehlerME" 7 "FehlerOE" 12 "EingriffED" ;
VAL_ 317 QFK_KrIst 65534 "Init" 65535 "Fehler" ;
VAL_ 317 QFK_IstKraft 1022 "Init" 1023 "Fehler" ;
VAL_ 591 RDR1_relevanter_Fehler 0 "kein_relevanter_Fehler" 1 "relevanter_Fehler" ;
VAL_ 591 RDR1_Blindheit_erkannt 0 "keine_Blindheit_erkannt" 1 "Blindheit_erkannt" ;
VAL_ 591 RDR1_relev_Nichtverfuegbarkeit 0 "verfuegbar" 1 "nicht_verfuegbar" ;
VAL_ 591 RDR1_Verkehrssinn 0 "init" 1 "Linksverkehr" 2 "Rechtsverkehr" 3 "Unbekannt" ;
VAL_ 591 RDR1_Objekte_02_Datenalter 1023 "Daten_aelter_als_Maximum" ;
VAL_ 591 RDR1_Obj_01_ax_v 255 "Init" ;
VAL_ 591 RDR1_Obj_01_ax_StdA 63 "Init" ;
VAL_ 591 RDR1_Obj_01_vx_StdA 127 "Init" ;
VAL_ 591 RDR1_Obj_01_dx_StdA 127 "Init" ;
VAL_ 591 RDR1_Obj_01_dy_StdA 127 "Init" ;
